VERSION ""

NS_ :

BS_:

BU_: L_3HKBD L_FHPTC L_2HKBD L_ATCU L_PCM L_EVNT L_HKBD L_RHPTC

BO_ 36 L_ATCU_04: 8 L_ATCU
 SG_ L_ATCU_ArClnIntroEvt : 0|1@1+ (1,0) [0|0] ""  L_HKBD
 SG_ L_ATCU_ArClnSmblClr : 1|4@1+ (1,0) [0|0] ""  L_HKBD
 SG_ L_ATCU_DustLevelDis : 19|3@1+ (1,0) [0|0] ""  L_HKBD
 SG_ L_ATCU_DustBarDisOff : 22|1@1+ (1,0) [0|0] ""  L_HKBD
 SG_ L_ATCU_DustSnrStepDis : 23|6@1+ (1,0) [0|0] ""  L_HKBD
 SG_ L_ATCU_FragStrhDis : 29|2@1+ (1,0) [0|0] ""  L_HKBD,L_PCM
 SG_ L_ATCU_FragKindDis : 31|3@1+ (1,0) [0|0] ""  L_HKBD,L_PCM
 SG_ L_ATCU_Frag1Inform : 34|4@1+ (1,0) [0|0] ""  L_HKBD,L_PCM
 SG_ L_ATCU_Frag2Inform : 38|4@1+ (1,0) [0|0] ""  L_HKBD,L_PCM
 SG_ L_ATCU_Frag1RemainDisp : 42|4@1+ (1,0) [0|0] ""  L_HKBD,L_PCM
 SG_ L_ATCU_Frag2RemainDisp : 46|4@1+ (1,0) [0|0] ""  L_2HKBD,L_HKBD
 SG_ L_ATCU_ArClnSmblTyp : 5|4@1+ (1,0) [0|0] ""  L_HKBD
 SG_ L_ATCU_FrtBlwMaxLvlVaild : 50|4@1+ (1,0) [0|0] ""  L_2HKBD,L_HKBD
 SG_ L_ATCU_OpSta : 54|3@1+ (1,0) [0|0] ""  L_EVNT,L_HKBD
 SG_ L_ATCU_TempDispUnit : 57|2@1+ (1,0) [0|0] ""  L_2HKBD,L_HKBD
 SG_ L_ATCU_DrvAUTOStep : 59|4@1+ (1,0) [0|0] ""  L_HKBD
 SG_ L_ATCU_DiagCodeDis : 9|10@1+ (1,-1) [0|0] ""  L_HKBD

BO_ 37 L_ATCU_05: 8 L_ATCU
 SG_ L_ATCU_RrOpSta : 0|3@1+ (1,0) [0|0] ""  L_2HKBD,L_HKBD
 SG_ L_ATCU_RrDrvTempFDis : 11|8@1+ (1,56) [0|0] "¢µ"  L_2HKBD,L_HKBD
 SG_ L_ATCU_RrDrvModDis : 19|4@1+ (1,0) [0|0] ""  L_2HKBD,L_EVNT,L_HKBD
 SG_ L_ATCU_RrDrvBlwDis : 23|4@1+ (1,0) [0|0] ""  L_2HKBD,L_HKBD
 SG_ L_ATCU_RrDrvAutoDis : 27|2@1+ (1,0) [0|0] ""  L_2HKBD,L_HKBD
 SG_ L_ATCU_RrDrvMultiAutoBlwDis : 29|2@1+ (1,0) [0|0] ""  L_2HKBD,L_HKBD
 SG_ L_ATCU_RrDrvTempCDis : 3|8@1+ (0.5,14) [0|0] "¡É"  L_2HKBD,L_HKBD
 SG_ L_ATCU_RrSyncDis : 31|2@1+ (1,0) [0|0] ""  L_2HKBD,L_HKBD
 SG_ L_ATCU_RrLcdBckLightSta : 33|1@1+ (1,0) [0|0] ""  L_2HKBD,L_HKBD
 SG_ L_ATCU_RrGUIBlankDis : 34|1@1+ (1,0) [0|0] ""  L_2HKBD,L_HKBD
 SG_ L_ATCU_RLStHeatSwHInd : 35|1@1+ (1,0) [0|0] ""  L_2HKBD,L_HKBD
 SG_ L_ATCU_RLStHeatSwMInd : 36|1@1+ (1,0) [0|0] ""  L_2HKBD,L_HKBD
 SG_ L_ATCU_RLStHeatSwLInd : 37|1@1+ (1,0) [0|0] ""  L_2HKBD,L_HKBD
 SG_ L_ATCU_RLStVntSwHInd : 38|1@1+ (1,0) [0|0] ""  L_2HKBD,L_HKBD
 SG_ L_ATCU_RLStVntSwMInd : 39|1@1+ (1,0) [0|0] ""  L_2HKBD,L_HKBD
 SG_ L_ATCU_RLStVntSwLInd : 40|1@1+ (1,0) [0|0] ""  L_2HKBD,L_HKBD
 SG_ L_ATCU_RRStHeatSwHInd : 41|1@1+ (1,0) [0|0] ""  L_2HKBD,L_HKBD
 SG_ L_ATCU_RRStHeatSwMInd : 42|1@1+ (1,0) [0|0] ""  L_2HKBD,L_HKBD
 SG_ L_ATCU_RRStHeatSwLInd : 43|1@1+ (1,0) [0|0] ""  L_2HKBD,L_HKBD
 SG_ L_ATCU_RRStVntSwHInd : 44|1@1+ (1,0) [0|0] ""  L_2HKBD,L_HKBD
 SG_ L_ATCU_RRStVntSwMInd : 45|1@1+ (1,0) [0|0] ""  L_2HKBD,L_HKBD
 SG_ L_ATCU_RRStVntSwLInd : 46|1@1+ (1,0) [0|0] ""  L_2HKBD,L_HKBD
 SG_ L_ATCU_RrMTCOpSta : 47|2@1+ (1,0) [0|0] ""  L_2HKBD,L_HKBD
 SG_ L_ATCU_RrMTCTempLvl : 49|4@1+ (1,0) [0|0] ""  L_2HKBD,L_HKBD
 SG_ L_ATCU_RrPsModDis : 53|4@1+ (1,0) [0|0] ""  L_2HKBD,L_EVNT,L_HKBD
 SG_ L_ATCU_RrLockDis : 57|2@1+ (1,0) [0|0] ""  L_2HKBD,L_HKBD
 SG_ L_ATCU_RrDrvAutoStep : 59|4@1+ (1,0) [0|0] ""  L_2HKBD,L_HKBD

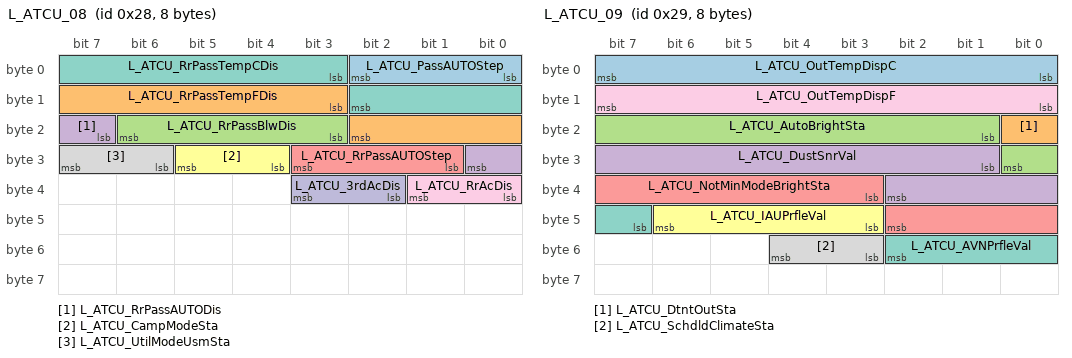
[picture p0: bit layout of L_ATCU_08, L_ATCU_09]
BO_ 40 L_ATCU_08: 8 L_ATCU
 SG_ L_ATCU_PassAUTOStep : 0|3@1+ (1,0) [0|0] ""  L_2HKBD,L_HKBD
 SG_ L_ATCU_RrPassTempFDis : 11|8@1+ (1,56) [0|0] "¢µ"  L_2HKBD,L_HKBD
 SG_ L_ATCU_RrPassBlwDis : 19|4@1+ (1,0) [0|0] ""  L_2HKBD,L_HKBD
 SG_ L_ATCU_RrPassAUTODis : 23|2@1+ (1,0) [0|0] ""  L_2HKBD,L_HKBD
 SG_ L_ATCU_RrPassAUTOStep : 25|3@1+ (1,0) [0|0] ""  L_2HKBD,L_HKBD
 SG_ L_ATCU_CampModeSta : 28|2@1+ (1,0) [0|0] ""  L_2HKBD,L_3HKBD,L_EVNT,L_HKBD
 SG_ L_ATCU_RrPassTempCDis : 3|8@1+ (0.5,14) [0|0] "¡É"  L_2HKBD,L_HKBD
 SG_ L_ATCU_UtilModeUsmSta : 30|2@1+ (1,0) [0|0] ""  L_2HKBD,L_3HKBD,L_EVNT,L_HKBD
 SG_ L_ATCU_RrAcDis : 32|2@1+ (1,0) [0|0] ""  L_2HKBD,L_3HKBD,L_HKBD
 SG_ L_ATCU_3rdAcDis : 34|2@1+ (1,0) [0|0] ""  L_2HKBD,L_3HKBD,L_HKBD

BO_ 41 L_ATCU_09: 8 L_ATCU
 SG_ L_ATCU_OutTempDispC : 0|8@1+ (0.5,-41) [0|0] "¡É"  L_FHPTC,L_HKBD,L_RHPTC
 SG_ L_ATCU_DtntOutSta : 16|1@1+ (1,0) [0|0] ""  L_2HKBD,L_EVNT,L_HKBD
 SG_ L_ATCU_AutoBrightSta : 17|8@1+ (1,0) [0|0] ""  L_2HKBD,L_EVNT,L_HKBD
 SG_ L_ATCU_DustSnrVal : 25|10@1+ (1,0) [0|0] "um/m3"  L_HKBD
 SG_ L_ATCU_NotMinModeBrightSta : 35|8@1+ (1,0) [0|0] ""  L_2HKBD,L_3HKBD,L_EVNT,L_HKBD
 SG_ L_ATCU_IAUPrfleVal : 43|4@1+ (1,0) [0|0] ""  L_EVNT
 SG_ L_ATCU_AVNPrfleVal : 47|4@1+ (1,0) [0|0] ""  L_EVNT
 SG_ L_ATCU_SchdldClimateSta : 51|2@1+ (1,0) [0|0] ""  L_EVNT
 SG_ L_ATCU_OutTempDispF : 8|8@1+ (1,-42) [0|0] "¢µ"  L_FHPTC,L_HKBD,L_RHPTC

BO_ 49 L_ATCU_11: 8 L_ATCU
 SG_ L_ATCU_ResetPreWrngForOthers : 0|2@1+ (1,0) [0|0] ""  L_2HKBD,L_3HKBD,L_EVNT,L_HKBD,L_PCM
 SG_ L_ATCU_ResetReqForOthers : 2|2@1+ (1,0) [0|0] ""  L_2HKBD,L_3HKBD,L_EVNT,L_HKBD,L_PCM

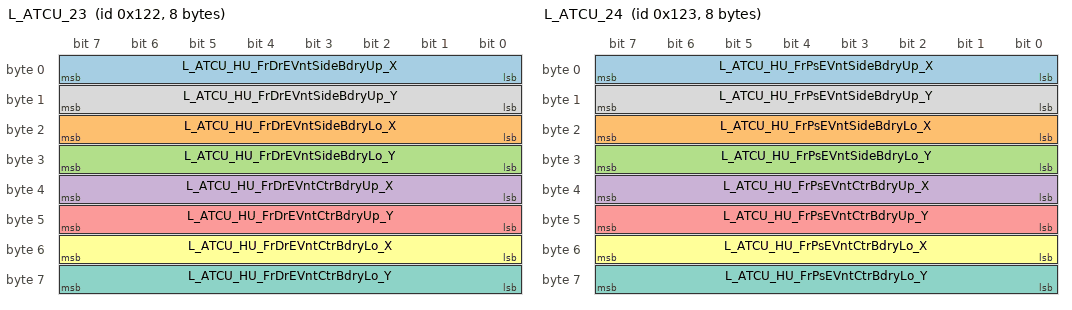
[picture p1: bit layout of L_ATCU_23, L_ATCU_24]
BO_ 290 L_ATCU_23: 8 L_ATCU
 SG_ L_ATCU_HU_FrDrEVntSideBdryUp_X : 0|8@1+ (10,0) [0|0] ""  L_EVNT
 SG_ L_ATCU_HU_FrDrEVntSideBdryLo_X : 16|8@1+ (10,0) [0|0] ""  L_EVNT
 SG_ L_ATCU_HU_FrDrEVntSideBdryLo_Y : 24|8@1+ (10,0) [0|0] ""  L_EVNT
 SG_ L_ATCU_HU_FrDrEVntCtrBdryUp_X : 32|8@1+ (10,0) [0|0] ""  L_EVNT
 SG_ L_ATCU_HU_FrDrEVntCtrBdryUp_Y : 40|8@1+ (10,0) [0|0] ""  L_EVNT
 SG_ L_ATCU_HU_FrDrEVntCtrBdryLo_X : 48|8@1+ (10,0) [0|0] ""  L_EVNT
 SG_ L_ATCU_HU_FrDrEVntCtrBdryLo_Y : 56|8@1+ (10,0) [0|0] ""  L_EVNT
 SG_ L_ATCU_HU_FrDrEVntSideBdryUp_Y : 8|8@1+ (10,0) [0|0] ""  L_EVNT

BO_ 291 L_ATCU_24: 8 L_ATCU
 SG_ L_ATCU_HU_FrPsEVntSideBdryUp_X : 0|8@1+ (10,0) [0|0] ""  L_EVNT
 SG_ L_ATCU_HU_FrPsEVntSideBdryLo_X : 16|8@1+ (10,0) [0|0] ""  L_EVNT
 SG_ L_ATCU_HU_FrPsEVntSideBdryLo_Y : 24|8@1+ (10,0) [0|0] ""  L_EVNT
 SG_ L_ATCU_HU_FrPsEVntCtrBdryUp_X : 32|8@1+ (10,0) [0|0] ""  L_EVNT
 SG_ L_ATCU_HU_FrPsEVntCtrBdryUp_Y : 40|8@1+ (10,0) [0|0] ""  L_EVNT
 SG_ L_ATCU_HU_FrPsEVntCtrBdryLo_X : 48|8@1+ (10,0) [0|0] ""  L_EVNT
 SG_ L_ATCU_HU_FrPsEVntCtrBdryLo_Y : 56|8@1+ (10,0) [0|0] ""  L_EVNT
 SG_ L_ATCU_HU_FrPsEVntSideBdryUp_Y : 8|8@1+ (10,0) [0|0] ""  L_EVNT

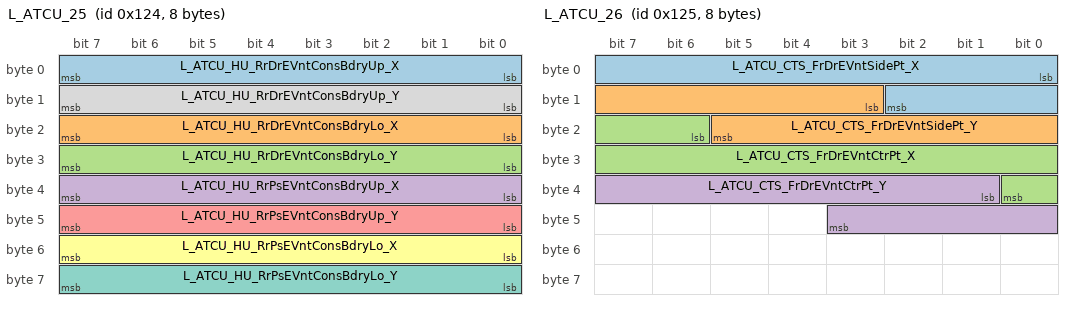
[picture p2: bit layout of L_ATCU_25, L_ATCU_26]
BO_ 292 L_ATCU_25: 8 L_ATCU
 SG_ L_ATCU_HU_RrDrEVntConsBdryUp_X : 0|8@1+ (10,0) [0|0] ""  L_EVNT
 SG_ L_ATCU_HU_RrDrEVntConsBdryLo_X : 16|8@1+ (10,0) [0|0] ""  L_EVNT
 SG_ L_ATCU_HU_RrDrEVntConsBdryLo_Y : 24|8@1+ (10,0) [0|0] ""  L_EVNT
 SG_ L_ATCU_HU_RrPsEVntConsBdryUp_X : 32|8@1+ (10,0) [0|0] ""  L_EVNT
 SG_ L_ATCU_HU_RrPsEVntConsBdryUp_Y : 40|8@1+ (10,0) [0|0] ""  L_EVNT
 SG_ L_ATCU_HU_RrPsEVntConsBdryLo_X : 48|8@1+ (10,0) [0|0] ""  L_EVNT
 SG_ L_ATCU_HU_RrPsEVntConsBdryLo_Y : 56|8@1+ (10,0) [0|0] ""  L_EVNT
 SG_ L_ATCU_HU_RrDrEVntConsBdryUp_Y : 8|8@1+ (10,0) [0|0] ""  L_EVNT

BO_ 293 L_ATCU_26: 8 L_ATCU
 SG_ L_ATCU_CTS_FrDrEVntSidePt_X : 0|11@1+ (1,0) [0|0] ""  L_EVNT
 SG_ L_ATCU_CTS_FrDrEVntSidePt_Y : 11|11@1+ (1,0) [0|0] ""  L_EVNT
 SG_ L_ATCU_CTS_FrDrEVntCtrPt_X : 22|11@1+ (1,0) [0|0] ""  L_EVNT
 SG_ L_ATCU_CTS_FrDrEVntCtrPt_Y : 33|11@1+ (1,0) [0|0] ""  L_EVNT

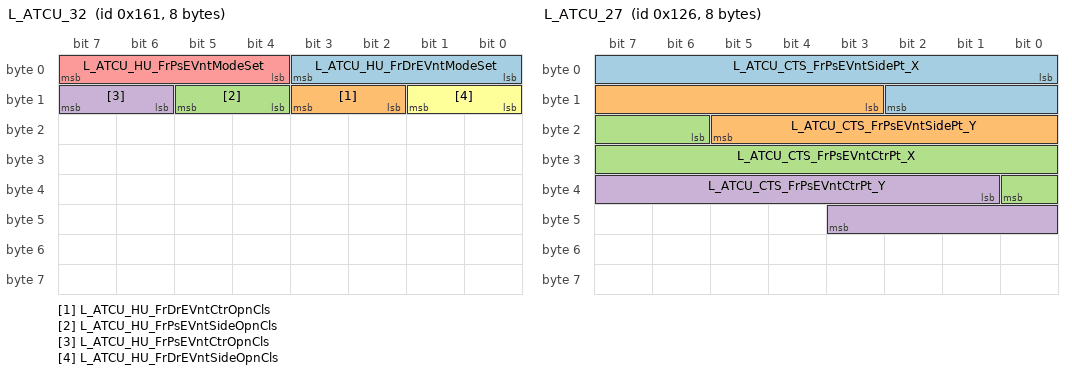
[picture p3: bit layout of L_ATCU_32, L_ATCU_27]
BO_ 353 L_ATCU_32: 8 L_ATCU
 SG_ L_ATCU_HU_FrDrEVntModeSet : 0|4@1+ (1,0) [0|0] ""  L_EVNT
 SG_ L_ATCU_HU_FrDrEVntCtrOpnCls : 10|2@1+ (1,0) [0|0] ""  L_EVNT
 SG_ L_ATCU_HU_FrPsEVntSideOpnCls : 12|2@1+ (1,0) [0|0] ""  L_EVNT
 SG_ L_ATCU_HU_FrPsEVntCtrOpnCls : 14|2@1+ (1,0) [0|0] ""  L_EVNT
 SG_ L_ATCU_HU_FrPsEVntModeSet : 4|4@1+ (1,0) [0|0] ""  L_EVNT
 SG_ L_ATCU_HU_FrDrEVntSideOpnCls : 8|2@1+ (1,0) [0|0] ""  L_EVNT

BO_ 294 L_ATCU_27: 8 L_ATCU
 SG_ L_ATCU_CTS_FrPsEVntSidePt_X : 0|11@1+ (1,0) [0|0] ""  L_EVNT
 SG_ L_ATCU_CTS_FrPsEVntSidePt_Y : 11|11@1+ (1,0) [0|0] ""  L_EVNT
 SG_ L_ATCU_CTS_FrPsEVntCtrPt_X : 22|11@1+ (1,0) [0|0] ""  L_EVNT
 SG_ L_ATCU_CTS_FrPsEVntCtrPt_Y : 33|11@1+ (1,0) [0|0] ""  L_EVNT

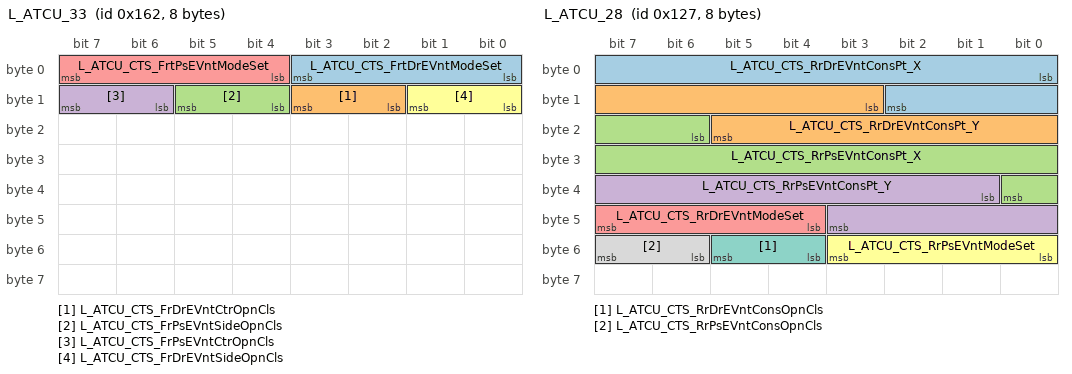
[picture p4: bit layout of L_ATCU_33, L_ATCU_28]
BO_ 354 L_ATCU_33: 8 L_ATCU
 SG_ L_ATCU_CTS_FrtDrEVntModeSet : 0|4@1+ (1,0) [0|0] ""  L_EVNT
 SG_ L_ATCU_CTS_FrDrEVntCtrOpnCls : 10|2@1+ (1,0) [0|0] ""  L_EVNT
 SG_ L_ATCU_CTS_FrPsEVntSideOpnCls : 12|2@1+ (1,0) [0|0] ""  L_EVNT
 SG_ L_ATCU_CTS_FrPsEVntCtrOpnCls : 14|2@1+ (1,0) [0|0] ""  L_EVNT
 SG_ L_ATCU_CTS_FrtPsEVntModeSet : 4|4@1+ (1,0) [0|0] ""  L_EVNT
 SG_ L_ATCU_CTS_FrDrEVntSideOpnCls : 8|2@1+ (1,0) [0|0] ""  L_EVNT

BO_ 295 L_ATCU_28: 8 L_ATCU
 SG_ L_ATCU_CTS_RrDrEVntConsPt_X : 0|11@1+ (1,0) [0|0] ""  L_EVNT
 SG_ L_ATCU_CTS_RrDrEVntConsPt_Y : 11|11@1+ (1,0) [0|0] ""  L_EVNT
 SG_ L_ATCU_CTS_RrPsEVntConsPt_X : 22|11@1+ (1,0) [0|0] ""  L_EVNT
 SG_ L_ATCU_CTS_RrPsEVntConsPt_Y : 33|11@1+ (1,0) [0|0] ""  L_EVNT
 SG_ L_ATCU_CTS_RrDrEVntModeSet : 44|4@1+ (1,0) [0|0] ""  L_EVNT
 SG_ L_ATCU_CTS_RrPsEVntModeSet : 48|4@1+ (1,0) [0|0] ""  L_EVNT
 SG_ L_ATCU_CTS_RrDrEVntConsOpnCls : 52|2@1+ (1,0) [0|0] ""  L_EVNT
 SG_ L_ATCU_CTS_RrPsEVntConsOpnCls : 54|2@1+ (1,0) [0|0] ""  L_EVNT

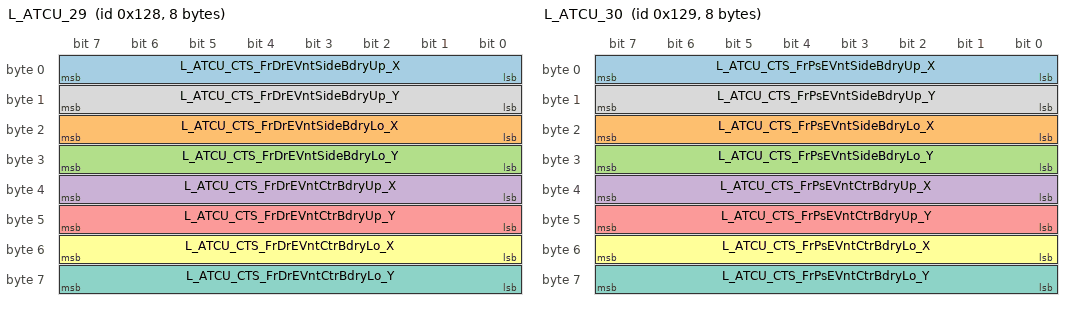
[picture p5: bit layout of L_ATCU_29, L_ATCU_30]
BO_ 296 L_ATCU_29: 8 L_ATCU
 SG_ L_ATCU_CTS_FrDrEVntSideBdryUp_X : 0|8@1+ (10,0) [0|0] ""  L_EVNT
 SG_ L_ATCU_CTS_FrDrEVntSideBdryLo_X : 16|8@1+ (10,0) [0|0] ""  L_EVNT
 SG_ L_ATCU_CTS_FrDrEVntSideBdryLo_Y : 24|8@1+ (10,0) [0|0] ""  L_EVNT
 SG_ L_ATCU_CTS_FrDrEVntCtrBdryUp_X : 32|8@1+ (10,0) [0|0] ""  L_EVNT
 SG_ L_ATCU_CTS_FrDrEVntCtrBdryUp_Y : 40|8@1+ (10,0) [0|0] ""  L_EVNT
 SG_ L_ATCU_CTS_FrDrEVntCtrBdryLo_X : 48|8@1+ (10,0) [0|0] ""  L_EVNT
 SG_ L_ATCU_CTS_FrDrEVntCtrBdryLo_Y : 56|8@1+ (10,0) [0|0] ""  L_EVNT
 SG_ L_ATCU_CTS_FrDrEVntSideBdryUp_Y : 8|8@1+ (10,0) [0|0] ""  L_EVNT

BO_ 297 L_ATCU_30: 8 L_ATCU
 SG_ L_ATCU_CTS_FrPsEVntSideBdryUp_X : 0|8@1+ (10,0) [0|0] ""  L_EVNT
 SG_ L_ATCU_CTS_FrPsEVntSideBdryLo_X : 16|8@1+ (10,0) [0|0] ""  L_EVNT
 SG_ L_ATCU_CTS_FrPsEVntSideBdryLo_Y : 24|8@1+ (10,0) [0|0] ""  L_EVNT
 SG_ L_ATCU_CTS_FrPsEVntCtrBdryUp_X : 32|8@1+ (10,0) [0|0] ""  L_EVNT
 SG_ L_ATCU_CTS_FrPsEVntCtrBdryUp_Y : 40|8@1+ (10,0) [0|0] ""  L_EVNT
 SG_ L_ATCU_CTS_FrPsEVntCtrBdryLo_X : 48|8@1+ (10,0) [0|0] ""  L_EVNT
 SG_ L_ATCU_CTS_FrPsEVntCtrBdryLo_Y : 56|8@1+ (10,0) [0|0] ""  L_EVNT
 SG_ L_ATCU_CTS_FrPsEVntSideBdryUp_Y : 8|8@1+ (10,0) [0|0] ""  L_EVNT

CM_ BO_ 36 "[PE] Periodic and On Event";
CM_ SG_ 36 L_ATCU_ArClnIntroEvt "ATCU_AirCleaningIntroEvent";
CM_ SG_ 36 L_ATCU_ArClnSmblClr "ATCU_AirCleaningSymbolColor";
CM_ SG_ 36 L_ATCU_DustLevelDis "ATCU_DustLevelDisplay";
CM_ SG_ 36 L_ATCU_DustBarDisOff "ATCU_DustBarDisplayOff";
CM_ SG_ 36 L_ATCU_DustSnrStepDis "ATCU_DustSensorStepDisplay";
CM_ SG_ 36 L_ATCU_FragStrhDis "ATCU_FragStrengthDisplay";
CM_ SG_ 36 L_ATCU_FragKindDis "ATCU_FragKindDisplay";
CM_ SG_ 36 L_ATCU_Frag1Inform "ATCU_Frag1Information";
CM_ SG_ 36 L_ATCU_Frag2Inform "ATCU_Frag2Information";
CM_ SG_ 36 L_ATCU_Frag1RemainDisp "ATCU_Frag1RemainDisplay";
CM_ SG_ 36 L_ATCU_Frag2RemainDisp "ATCU_Frag2RemainDisplay";
CM_ SG_ 36 L_ATCU_ArClnSmblTyp "ATCU_AircCleaningSymbolType";
CM_ SG_ 36 L_ATCU_FrtBlwMaxLvlVaild "ATCU_FrontBlowerMaxLevelVaild";
CM_ SG_ 36 L_ATCU_OpSta "ATCU_OperationStatus";
CM_ SG_ 36 L_ATCU_TempDispUnit "ATCU_TemperatureDisplayUnit";
CM_ SG_ 36 L_ATCU_DrvAUTOStep "ATCU_DriverAutoStep";
CM_ SG_ 36 L_ATCU_DiagCodeDis "ATCU_DiagCodeDisplay";
CM_ BO_ 37 "[PE] Periodic and On Event";
CM_ SG_ 37 L_ATCU_RrOpSta "ATCU_RearOperationStatus";
CM_ SG_ 37 L_ATCU_RrDrvTempFDis "ATCU_RearDriverTemperature¢µDisplay";
CM_ SG_ 37 L_ATCU_RrDrvModDis "ATCU_RearDriverModeDisplay";
CM_ SG_ 37 L_ATCU_RrDrvBlwDis "ATCU_RearDriverBlowerDisplay";
CM_ SG_ 37 L_ATCU_RrDrvAutoDis "ATCU_RearDriverAutoDisplay";
CM_ SG_ 37 L_ATCU_RrDrvMultiAutoBlwDis "ATCU_RearDriverMultiAutoBlowerDisplay";
CM_ SG_ 37 L_ATCU_RrDrvTempCDis "ATCU_RearDriverTemperature¡ÉDisplay";
CM_ SG_ 37 L_ATCU_RrSyncDis "ATCU_RearSyncDisplay";
CM_ SG_ 37 L_ATCU_RrLcdBckLightSta "ATCU_RearLCDBackLightStatus";
CM_ SG_ 37 L_ATCU_RrGUIBlankDis "ATCU_RearGUIBlankDisplay";
CM_ SG_ 37 L_ATCU_RLStHeatSwHInd "ATCU_RearLeftSeatHeatSwitchHighIndicator";
CM_ SG_ 37 L_ATCU_RLStHeatSwMInd "ATCU_RearLeftSeatHeatSwitchMiddleIndicator";
CM_ SG_ 37 L_ATCU_RLStHeatSwLInd "ATCU_RearLeftSeatHeatSwitchLowIndicator";
CM_ SG_ 37 L_ATCU_RLStVntSwHInd "ATCU_RearLeftSeatVentilationSwitchHighIndicator";
CM_ SG_ 37 L_ATCU_RLStVntSwMInd "ATCU_RearLeftSeatVentilationSwitchMiddleIndicator";
CM_ SG_ 37 L_ATCU_RLStVntSwLInd "ATCU_RearLeftSeatVentilationSwitchLowIndicator";
CM_ SG_ 37 L_ATCU_RRStHeatSwHInd "ATCU_RearRightSeatHeatSwitchHighIndicator";
CM_ SG_ 37 L_ATCU_RRStHeatSwMInd "ATCU_RearRightSeatHeatSwitchMiddleIndicator";
CM_ SG_ 37 L_ATCU_RRStHeatSwLInd "ATCU_RearRightSeatHeatSwitchLowIndicator";
CM_ SG_ 37 L_ATCU_RRStVntSwHInd "ATCU_RearRightSeatVentilationSwitchHighIndicator";
CM_ SG_ 37 L_ATCU_RRStVntSwMInd "ATCU_RearRightSeatVentilationSwitchMiddleIndicator";
CM_ SG_ 37 L_ATCU_RRStVntSwLInd "ATCU_RearRightSeatVentilationSwitchLowIndicator";
CM_ SG_ 37 L_ATCU_RrMTCOpSta "ATCU_RearMTCOperationStatus";
CM_ SG_ 37 L_ATCU_RrMTCTempLvl "ATCU_RearMTCTempLevel";
CM_ SG_ 37 L_ATCU_RrPsModDis "ATCU_RearPassengerModeDisplay";
CM_ SG_ 37 L_ATCU_RrLockDis "ATCU_RearLockDisplay";
CM_ SG_ 37 L_ATCU_RrDrvAutoStep "ATCU_RearDriverAutoStep";
CM_ BO_ 40 "[PE] Periodic and On Event";
CM_ SG_ 40 L_ATCU_PassAUTOStep "ATCU_PassAUTOStep";
CM_ SG_ 40 L_ATCU_RrPassTempFDis "ATCU_RrPassTempFDisplay";
CM_ SG_ 40 L_ATCU_RrPassBlwDis "ATCU_RrPassBlwDis";
CM_ SG_ 40 L_ATCU_RrPassAUTODis "ATCU_RrPassAUTODis";
CM_ SG_ 40 L_ATCU_RrPassAUTOStep "ATCU_RrPassAUTOStep";
CM_ SG_ 40 L_ATCU_CampModeSta "ATCU_CampModeStatus";
CM_ SG_ 40 L_ATCU_RrPassTempCDis "ATCU_RrPassTempCDisplay";
CM_ SG_ 40 L_ATCU_UtilModeUsmSta "ATCU_UtilityModeUSMStatus";
CM_ SG_ 40 L_ATCU_RrAcDis "ATCU_RrAcDisplay";
CM_ SG_ 40 L_ATCU_3rdAcDis "L_ATCU_3rdAcDisplay";
CM_ BO_ 41 "[P] Periodic";
CM_ SG_ 41 L_ATCU_OutTempDispC "ATCU_OutTemperatureDisplay(¡É)";
CM_ SG_ 41 L_ATCU_DtntOutSta "ATCU_DetentOutStatus";
CM_ SG_ 41 L_ATCU_AutoBrightSta "ATCU_AutoBrightStatus";
CM_ SG_ 41 L_ATCU_DustSnrVal "ATCU_DustSensorValue";
CM_ SG_ 41 L_ATCU_NotMinModeBrightSta "ATCU_NotMinimumModeBrightStatus";
CM_ SG_ 41 L_ATCU_IAUPrfleVal "L_ATCU_IAUProfileValue";
CM_ SG_ 41 L_ATCU_AVNPrfleVal "L_ATCU_AVNProfileValue";
CM_ SG_ 41 L_ATCU_SchdldClimateSta "Operation of the air conditioning system, controlled by the remote control instructions according to the Power status and VCU(HCU, CCU, etc.), NOT ROUTING.";
CM_ SG_ 41 L_ATCU_OutTempDispF "ATCU_OutTemperatureDisplay(¢µ)";
CM_ BO_ 49 "[PE] Periodic and On Event";
CM_ SG_ 49 L_ATCU_ResetPreWrngForOthers "This is a PDC routing signal for reset preparing sideeffect of reset";
CM_ SG_ 49 L_ATCU_ResetReqForOthers "This is a PDC routing signal for SW reset except for Gateway";
CM_ BO_ 290 "[P] Periodic";
CM_ SG_ 290 L_ATCU_HU_FrDrEVntSideBdryUp_X "Front Driver Electric Vent Side Boundary Upper X Point";
CM_ SG_ 290 L_ATCU_HU_FrDrEVntSideBdryLo_X "Front Driver Electric Vent Side Boundary Lower X Point";
CM_ SG_ 290 L_ATCU_HU_FrDrEVntSideBdryLo_Y "Front Driver Electric Vent Side Boundary Lower Y Point";
CM_ SG_ 290 L_ATCU_HU_FrDrEVntCtrBdryUp_X "Front Driver Electric Vent Center Boundary Upper X Point";
CM_ SG_ 290 L_ATCU_HU_FrDrEVntCtrBdryUp_Y "Front Driver Electric Vent Center Boundary Upper Y Point";
CM_ SG_ 290 L_ATCU_HU_FrDrEVntCtrBdryLo_X "Front Driver Electric Vent Center Boundary Lower X Point";
CM_ SG_ 290 L_ATCU_HU_FrDrEVntCtrBdryLo_Y "Front Driver Electric Vent Center Boundary Lower Y Point";
CM_ SG_ 290 L_ATCU_HU_FrDrEVntSideBdryUp_Y "Front Driver Electric Vent Side Boundary Upper Y Point";
CM_ BO_ 291 "[P] Periodic";
CM_ SG_ 291 L_ATCU_HU_FrPsEVntSideBdryUp_X "Front Passenger Electric Vent Side Boundary Upper X Point";
CM_ SG_ 291 L_ATCU_HU_FrPsEVntSideBdryLo_X "Front Passenger Electric Vent Side Boundary Lower X Point";
CM_ SG_ 291 L_ATCU_HU_FrPsEVntSideBdryLo_Y "Front Passenger Electric Vent Side Boundary Lower Y Point";
CM_ SG_ 291 L_ATCU_HU_FrPsEVntCtrBdryUp_X "Front Passenger Electric Vent Center Boundary Upper X Point";
CM_ SG_ 291 L_ATCU_HU_FrPsEVntCtrBdryUp_Y "Front Passenger Electric Vent Center Boundary Upper Y Point";
CM_ SG_ 291 L_ATCU_HU_FrPsEVntCtrBdryLo_X "Front Passenger Electric Vent Center Boundary Lower X Point";
CM_ SG_ 291 L_ATCU_HU_FrPsEVntCtrBdryLo_Y "Front Passenger Electric Vent Center Boundary Lower Y Point";
CM_ SG_ 291 L_ATCU_HU_FrPsEVntSideBdryUp_Y "Front Passenger Electric Vent Side Boundary Upper Y Point";
CM_ BO_ 292 "[P] Periodic";
CM_ SG_ 292 L_ATCU_HU_RrDrEVntConsBdryUp_X "Rear Driver Electric Vent Console Boundary Upper X Point";
CM_ SG_ 292 L_ATCU_HU_RrDrEVntConsBdryLo_X "Rear Driver Electric Vent Console Boundary Lower X Point";
CM_ SG_ 292 L_ATCU_HU_RrDrEVntConsBdryLo_Y "Rear Driver Electric Vent Console Boundary Lower Y Point";
CM_ SG_ 292 L_ATCU_HU_RrPsEVntConsBdryUp_X "Rear Passenger Electric Vent Console Boundary Upper X Point";
CM_ SG_ 292 L_ATCU_HU_RrPsEVntConsBdryUp_Y "Rear Passenger Electric Vent Console Boundary Upper Y Point";
CM_ SG_ 292 L_ATCU_HU_RrPsEVntConsBdryLo_X "Rear Passenger Electric Vent Console Boundary Lower X Point";
CM_ SG_ 292 L_ATCU_HU_RrPsEVntConsBdryLo_Y "Rear Passenger Electric Vent Console Boundary Lower Y Point";
CM_ SG_ 292 L_ATCU_HU_RrDrEVntConsBdryUp_Y "Rear Driver Electric Vent Console Boundary Upper Y Point";
CM_ BO_ 293 "[EC] On Event and On Change";
CM_ SG_ 293 L_ATCU_CTS_FrDrEVntSidePt_X "Front Driver Electric Vent Side Touch Point X Value";
CM_ SG_ 293 L_ATCU_CTS_FrDrEVntSidePt_Y "Front Driver Electric Vent Side Touch Point Y Value";
CM_ SG_ 293 L_ATCU_CTS_FrDrEVntCtrPt_X "Front Driver Electric Vent Center Touch Point X Value";
CM_ SG_ 293 L_ATCU_CTS_FrDrEVntCtrPt_Y "Front Driver Electric Vent Center Touch Point Y Value";
CM_ BO_ 294 "[EC] On Event and On Change";
CM_ SG_ 294 L_ATCU_CTS_FrPsEVntSidePt_X "Front Passenger Electric Vent Side Touch Point X Value";
CM_ SG_ 294 L_ATCU_CTS_FrPsEVntSidePt_Y "Front Passenger Electric Vent Side Touch Point Y Value";
CM_ SG_ 294 L_ATCU_CTS_FrPsEVntCtrPt_X "Front Passenger Electric Vent Center Touch Point X Value";
CM_ SG_ 294 L_ATCU_CTS_FrPsEVntCtrPt_Y "Front Passenger Electric Vent Center Touch Point Y Value";
CM_ BO_ 295 "[EC] On Event and On Change";
CM_ SG_ 295 L_ATCU_CTS_RrDrEVntConsPt_X "Rear Driver Electric Vent Console Touch Point  X Value";
CM_ SG_ 295 L_ATCU_CTS_RrDrEVntConsPt_Y "Rear Driver Electric Vent Console Touch Point  Y Value";
CM_ SG_ 295 L_ATCU_CTS_RrPsEVntConsPt_X "Rear Passenger Electric Vent Console Touch Point  X Value";
CM_ SG_ 295 L_ATCU_CTS_RrPsEVntConsPt_Y "Rear Passenger Electric Vent Console Touch Point  Y Value";
CM_ SG_ 295 L_ATCU_CTS_RrDrEVntModeSet "Rear Driver Electric Vent Mode Set";
CM_ SG_ 295 L_ATCU_CTS_RrPsEVntModeSet "Rear Passenger Electric Vent Mode Set";
CM_ SG_ 295 L_ATCU_CTS_RrDrEVntConsOpnCls "Rear Driver Electric Vent Console Open Close Signal";
CM_ SG_ 295 L_ATCU_CTS_RrPsEVntConsOpnCls "Rear Passenger Electric Vent Console Open Close Signal";
CM_ BO_ 296 "[P] Periodic";
CM_ SG_ 296 L_ATCU_CTS_FrDrEVntSideBdryUp_X "Front Driver Electric Vent Side Boundary Upper X Point";
CM_ SG_ 296 L_ATCU_CTS_FrDrEVntSideBdryLo_X "Front Driver Electric Vent Side Boundary Lower X Point";
CM_ SG_ 296 L_ATCU_CTS_FrDrEVntSideBdryLo_Y "Front Driver Electric Vent Side Boundary Lower Y Point";
CM_ SG_ 296 L_ATCU_CTS_FrDrEVntCtrBdryUp_X "Front Driver Electric Vent Center Boundary Upper X Point";
CM_ SG_ 296 L_ATCU_CTS_FrDrEVntCtrBdryUp_Y "Front Driver Electric Vent Center Boundary Upper Y Point";
CM_ SG_ 296 L_ATCU_CTS_FrDrEVntCtrBdryLo_X "Front Driver Electric Vent Center Boundary Lower X Point";
CM_ SG_ 296 L_ATCU_CTS_FrDrEVntCtrBdryLo_Y "Front Driver Electric Vent Center Boundary Lower Y Point";
CM_ SG_ 296 L_ATCU_CTS_FrDrEVntSideBdryUp_Y "Front Driver Electric Vent Side Boundary Upper Y Point";
CM_ BO_ 297 "[P] Periodic";
CM_ SG_ 297 L_ATCU_CTS_FrPsEVntSideBdryUp_X "Front Passenger Electric Vent Side Boundary Upper X Point";
CM_ SG_ 297 L_ATCU_CTS_FrPsEVntSideBdryLo_X "Front Passenger Electric Vent Side Boundary Lower X Point";
CM_ SG_ 297 L_ATCU_CTS_FrPsEVntSideBdryLo_Y "Front Passenger Electric Vent Side Boundary Lower Y Point";
CM_ SG_ 297 L_ATCU_CTS_FrPsEVntCtrBdryUp_X "Front Passenger Electric Vent Center Boundary Upper X Point";
CM_ SG_ 297 L_ATCU_CTS_FrPsEVntCtrBdryUp_Y "Front Passenger Electric Vent Center Boundary Upper Y Point";
CM_ SG_ 297 L_ATCU_CTS_FrPsEVntCtrBdryLo_X "Front Passenger Electric Vent Center Boundary Lower X Point";
CM_ SG_ 297 L_ATCU_CTS_FrPsEVntCtrBdryLo_Y "Front Passenger Electric Vent Center Boundary Lower Y Point";
CM_ SG_ 297 L_ATCU_CTS_FrPsEVntSideBdryUp_Y "Front Passenger Electric Vent Side Boundary Upper Y Point";
CM_ BO_ 353 "[EC] On Event and On Change";
CM_ SG_ 353 L_ATCU_HU_FrDrEVntModeSet "Front Driver Electric Vent Mode Set";
CM_ SG_ 353 L_ATCU_HU_FrDrEVntCtrOpnCls "Front Driver Electric Vent Center Open Close Signal";
CM_ SG_ 353 L_ATCU_HU_FrPsEVntSideOpnCls "Front Passenger Electric Vent Side Open Close Signal";
CM_ SG_ 353 L_ATCU_HU_FrPsEVntCtrOpnCls "Front Passenger Electric Vent Center Open Close Signal";
CM_ SG_ 353 L_ATCU_HU_FrPsEVntModeSet "Front Passenger Electric Vent Mode Set";
CM_ SG_ 353 L_ATCU_HU_FrDrEVntSideOpnCls "Front Driver Electric Vent Side Open Close Signal";
CM_ BO_ 354 "[EC] On Event and On Change";
CM_ SG_ 354 L_ATCU_CTS_FrtDrEVntModeSet "Front Driver Electric Vent Mode Set";
CM_ SG_ 354 L_ATCU_CTS_FrDrEVntCtrOpnCls "Front Driver Electric Vent Center Open Close Signal";
CM_ SG_ 354 L_ATCU_CTS_FrPsEVntSideOpnCls "Front Passenger Electric Vent Side Open Close Signal";
CM_ SG_ 354 L_ATCU_CTS_FrPsEVntCtrOpnCls "Front Passenger Electric Vent Center Open Close Signal";
CM_ SG_ 354 L_ATCU_CTS_FrtPsEVntModeSet "Front Passenger Electric Vent Mode Set";
CM_ SG_ 354 L_ATCU_CTS_FrDrEVntSideOpnCls "Front Driver Electric Vent Side Open Close Signal";
BA_DEF_ BO_ "UsrMsgIDSforwardDeviation" INT 0 100 ;
BA_DEF_ BO_ "UsrMsgIDSbackwardDeviation" INT 50 1000 ;
BA_DEF_ BO_ "GenMsgCycleTime" INT 0 2000 ;
BA_DEF_ BO_ "GenMsgStartDelayTime" INT 0 2000 ;
BA_DEF_ BO_ "GenMsgSendType" ENUM "Cyclic","NoMsgSendType" ;
BA_DEF_ BO_ "GenMsgCycleTimeFast" INT 0 500 ;
BA_DEF_ BO_ "GenMsgDelayTime" INT 0 20 ;
BA_DEF_ BO_ "GenMsgILSupport" ENUM "No","Yes" ;
BA_DEF_ BO_ "GenMsgNrOfRepetition" INT 0 3 ;
BA_DEF_ BO_ "VFrameFormat" ENUM "StandardCAN","ExtendedCAN","reserved","reserved","reserved","reserved","reserved","reserved","reserved","reserved","reserved","reserved","reserved","reserved","StandardCAN_FD","ExtendedCAN_FD" ;
BA_DEF_ SG_ "UserSigValidity" ENUM "B+","ACC","IG","IG1","IG2","IG3","IG1 or IG2","IG1 or IG3","Undef" ;
BA_DEF_ SG_ "UsrSigPurpose" ENUM "Undef","FN","DIAG","DIAG(Req)","DIAG(Res)","DIAG(Phy)","DEV","CCP(Req)","CCP(Res)","NM","TP" ;
BA_DEF_ SG_ "GenSigStartValue" INT 0 1215752192 ;
BA_DEF_ SG_ "NetworkRequestHoldingTime" INT 0 65535 ;
BA_DEF_ SG_ "Description" STRING ;
BA_DEF_ SG_ "Version" STRING ;
BA_DEF_ SG_ "GenSigEnvVarType" ENUM "Int","Float","Undef" ;
BA_DEF_ SG_ "GenSigSendType" ENUM "Cyclic","OnWrite","OnWriteWithRepetition","OnChange","OnChangeWithRepetition","IfActive","IfActiveWithRepetition","NoSigSendType","OnChangeAndIfActive","OnChangeAndIfActiveWithRepetition" ;
BA_DEF_ SG_ "GwSigLatencyTime" INT 0 65536 ;
BA_DEF_ SG_ "GwSigMissingSourceType" ENUM "Undef","OldValue","DefaultValue","InitialValue" ;
BA_DEF_ SG_ "NWM-WakeupAllowed" ENUM "<n.a.>" ;
BA_DEF_ SG_ "RoutingFactor" INT 1 1215752192 ;
BA_DEF_REL_ BU_SG_REL_ "GenSigTimeoutTime" INT 0 7000 ;
BA_DEF_DEF_ "UsrMsgIDSforwardDeviation" 10 ;
BA_DEF_DEF_ "UsrMsgIDSbackwardDeviation" 100 ;
BA_DEF_DEF_ "GenMsgCycleTime" 200 ;
BA_DEF_DEF_ "GenMsgStartDelayTime" 0 ;
BA_DEF_DEF_ "GenMsgSendType" "NoMsgSendType" ;
BA_DEF_DEF_ "GenMsgCycleTimeFast" 40 ;
BA_DEF_DEF_ "GenMsgDelayTime" 20 ;
BA_DEF_DEF_ "GenMsgILSupport" "Yes" ;
BA_DEF_DEF_ "GenMsgNrOfRepetition" 3 ;
BA_DEF_DEF_ "VFrameFormat" "StandardCAN" ;
BA_DEF_DEF_ "UserSigValidity" "IG" ;
BA_DEF_DEF_ "UsrSigPurpose" "FN" ;
BA_DEF_DEF_ "GenSigStartValue" 0 ;
BA_DEF_DEF_ "NetworkRequestHoldingTime" 0 ;
BA_DEF_DEF_ "Description" "" ;
BA_DEF_DEF_ "Version" "" ;
BA_DEF_DEF_ "GenSigEnvVarType" "Undef" ;
BA_DEF_DEF_ "GenSigSendType" "NoSigSendType" ;
BA_DEF_DEF_ "GwSigLatencyTime" 40 ;
BA_DEF_DEF_ "GwSigMissingSourceType" "Undef" ;
BA_DEF_DEF_ "NWM-WakeupAllowed" "<n.a.>" ;
BA_DEF_DEF_ "RoutingFactor" 1 ;
BA_DEF_DEF_REL_ "GenSigTimeoutTime" 500 ;
BA_ "GenMsgSendType" BO_ 36 0;
BA_ "GenSigSendType" SG_ 36 L_ATCU_ArClnIntroEvt 4;
BA_ "UserSigValidity" SG_ 36 L_ATCU_ArClnIntroEvt 7;
BA_REL_ "GenSigTimeoutTime" BU_SG_REL_ L_HKBD SG_ 36 L_ATCU_ArClnIntroEvt 1500;
BA_ "Version" SG_ 36 L_ATCU_ArClnIntroEvt "23.08.13";
BA_ "Description" SG_ 36 L_ATCU_ArClnSmblClr "This signal indicates the information about Color of AirCleaning Symbol displaying in the AVN";
BA_ "GenSigSendType" SG_ 36 L_ATCU_ArClnSmblClr 4;
BA_ "UserSigValidity" SG_ 36 L_ATCU_ArClnSmblClr 7;
BA_REL_ "GenSigTimeoutTime" BU_SG_REL_ L_HKBD SG_ 36 L_ATCU_ArClnSmblClr 1500;
BA_ "Version" SG_ 36 L_ATCU_ArClnSmblClr "23.08.13";
BA_ "GenSigSendType" SG_ 36 L_ATCU_DustLevelDis 4;
BA_ "UserSigValidity" SG_ 36 L_ATCU_DustLevelDis 7;
BA_REL_ "GenSigTimeoutTime" BU_SG_REL_ L_HKBD SG_ 36 L_ATCU_DustLevelDis 1500;
BA_ "Version" SG_ 36 L_ATCU_DustLevelDis "23.08.13";
BA_ "GenSigSendType" SG_ 36 L_ATCU_DustBarDisOff 4;
BA_ "UserSigValidity" SG_ 36 L_ATCU_DustBarDisOff 7;
BA_REL_ "GenSigTimeoutTime" BU_SG_REL_ L_HKBD SG_ 36 L_ATCU_DustBarDisOff 1500;
BA_ "Version" SG_ 36 L_ATCU_DustBarDisOff "23.08.13";
BA_ "GenSigSendType" SG_ 36 L_ATCU_DustSnrStepDis 4;
BA_ "UserSigValidity" SG_ 36 L_ATCU_DustSnrStepDis 7;
BA_REL_ "GenSigTimeoutTime" BU_SG_REL_ L_HKBD SG_ 36 L_ATCU_DustSnrStepDis 1500;
BA_ "Version" SG_ 36 L_ATCU_DustSnrStepDis "23.08.13";
BA_ "GenSigSendType" SG_ 36 L_ATCU_FragStrhDis 4;
BA_ "UserSigValidity" SG_ 36 L_ATCU_FragStrhDis 7;
BA_REL_ "GenSigTimeoutTime" BU_SG_REL_ L_HKBD SG_ 36 L_ATCU_FragStrhDis 1500;
BA_REL_ "GenSigTimeoutTime" BU_SG_REL_ L_PCM SG_ 36 L_ATCU_FragStrhDis 1500;
BA_ "Version" SG_ 36 L_ATCU_FragStrhDis "23.08.13";
BA_ "Description" SG_ 36 L_ATCU_FragKindDis "This singal indicates display value of Fragnance kind";
BA_ "GenSigSendType" SG_ 36 L_ATCU_FragKindDis 4;
BA_ "UserSigValidity" SG_ 36 L_ATCU_FragKindDis 7;
BA_REL_ "GenSigTimeoutTime" BU_SG_REL_ L_HKBD SG_ 36 L_ATCU_FragKindDis 1500;
BA_REL_ "GenSigTimeoutTime" BU_SG_REL_ L_PCM SG_ 36 L_ATCU_FragKindDis 1500;
BA_ "Version" SG_ 36 L_ATCU_FragKindDis "24.05.08";
BA_ "Description" SG_ 36 L_ATCU_Frag1Inform "This signal indicates Information of Fragrance 1";
BA_ "GenSigSendType" SG_ 36 L_ATCU_Frag1Inform 4;
BA_ "UserSigValidity" SG_ 36 L_ATCU_Frag1Inform 7;
BA_REL_ "GenSigTimeoutTime" BU_SG_REL_ L_HKBD SG_ 36 L_ATCU_Frag1Inform 1500;
BA_REL_ "GenSigTimeoutTime" BU_SG_REL_ L_PCM SG_ 36 L_ATCU_Frag1Inform 1500;
BA_ "Version" SG_ 36 L_ATCU_Frag1Inform "23.08.13";
BA_ "Description" SG_ 36 L_ATCU_Frag2Inform "This signal indicates Information of Fragrance 2";
BA_ "GenSigSendType" SG_ 36 L_ATCU_Frag2Inform 4;
BA_ "UserSigValidity" SG_ 36 L_ATCU_Frag2Inform 7;
BA_REL_ "GenSigTimeoutTime" BU_SG_REL_ L_HKBD SG_ 36 L_ATCU_Frag2Inform 1500;
BA_REL_ "GenSigTimeoutTime" BU_SG_REL_ L_PCM SG_ 36 L_ATCU_Frag2Inform 1500;
BA_ "Version" SG_ 36 L_ATCU_Frag2Inform "23.08.13";
BA_ "Description" SG_ 36 L_ATCU_Frag1RemainDisp "This signal indicates Remain Display of Ragrnace No.1";
BA_ "GenSigSendType" SG_ 36 L_ATCU_Frag1RemainDisp 4;
BA_ "UserSigValidity" SG_ 36 L_ATCU_Frag1RemainDisp 7;
BA_REL_ "GenSigTimeoutTime" BU_SG_REL_ L_HKBD SG_ 36 L_ATCU_Frag1RemainDisp 1500;
BA_REL_ "GenSigTimeoutTime" BU_SG_REL_ L_PCM SG_ 36 L_ATCU_Frag1RemainDisp 1500;
BA_ "Version" SG_ 36 L_ATCU_Frag1RemainDisp "23.08.13";
BA_ "Description" SG_ 36 L_ATCU_Frag2RemainDisp "This signal indicates Remain Display of Ragrnace No.2";
BA_ "GenSigSendType" SG_ 36 L_ATCU_Frag2RemainDisp 4;
BA_ "UserSigValidity" SG_ 36 L_ATCU_Frag2RemainDisp 7;
BA_REL_ "GenSigTimeoutTime" BU_SG_REL_ L_2HKBD SG_ 36 L_ATCU_Frag2RemainDisp 1500;
BA_REL_ "GenSigTimeoutTime" BU_SG_REL_ L_HKBD SG_ 36 L_ATCU_Frag2RemainDisp 1500;
BA_ "Version" SG_ 36 L_ATCU_Frag2RemainDisp "23.08.13";
BA_ "Description" SG_ 36 L_ATCU_ArClnSmblTyp "This signal indicate the feature of Air Cleaning Symbol displaying in the AVN";
BA_ "GenSigSendType" SG_ 36 L_ATCU_ArClnSmblTyp 4;
BA_ "UserSigValidity" SG_ 36 L_ATCU_ArClnSmblTyp 7;
BA_REL_ "GenSigTimeoutTime" BU_SG_REL_ L_HKBD SG_ 36 L_ATCU_ArClnSmblTyp 1500;
BA_ "Version" SG_ 36 L_ATCU_ArClnSmblTyp "23.08.13";
BA_ "Description" SG_ 36 L_ATCU_FrtBlwMaxLvlVaild "This signal indicates the maximum step of Front Blower according to multi auto steps.";
BA_ "GenSigSendType" SG_ 36 L_ATCU_FrtBlwMaxLvlVaild 4;
BA_ "UserSigValidity" SG_ 36 L_ATCU_FrtBlwMaxLvlVaild 7;
BA_REL_ "GenSigTimeoutTime" BU_SG_REL_ L_2HKBD SG_ 36 L_ATCU_FrtBlwMaxLvlVaild 1500;
BA_REL_ "GenSigTimeoutTime" BU_SG_REL_ L_HKBD SG_ 36 L_ATCU_FrtBlwMaxLvlVaild 1500;
BA_ "Version" SG_ 36 L_ATCU_FrtBlwMaxLvlVaild "23.08.13";
BA_ "GenSigSendType" SG_ 36 L_ATCU_OpSta 4;
BA_ "UserSigValidity" SG_ 36 L_ATCU_OpSta 7;
BA_REL_ "GenSigTimeoutTime" BU_SG_REL_ L_EVNT SG_ 36 L_ATCU_OpSta 1500;
BA_REL_ "GenSigTimeoutTime" BU_SG_REL_ L_HKBD SG_ 36 L_ATCU_OpSta 1500;
BA_ "Version" SG_ 36 L_ATCU_OpSta "23.08.13";
BA_ "Description" SG_ 36 L_ATCU_TempDispUnit "This signal is unit of Temperature display";
BA_ "GenSigSendType" SG_ 36 L_ATCU_TempDispUnit 4;
BA_ "UserSigValidity" SG_ 36 L_ATCU_TempDispUnit 7;
BA_REL_ "GenSigTimeoutTime" BU_SG_REL_ L_2HKBD SG_ 36 L_ATCU_TempDispUnit 1500;
BA_REL_ "GenSigTimeoutTime" BU_SG_REL_ L_HKBD SG_ 36 L_ATCU_TempDispUnit 1500;
BA_ "Version" SG_ 36 L_ATCU_TempDispUnit "24.05.08";
BA_ "GenSigSendType" SG_ 36 L_ATCU_DrvAUTOStep 4;
BA_ "UserSigValidity" SG_ 36 L_ATCU_DrvAUTOStep 7;
BA_REL_ "GenSigTimeoutTime" BU_SG_REL_ L_HKBD SG_ 36 L_ATCU_DrvAUTOStep 1500;
BA_ "Version" SG_ 36 L_ATCU_DrvAUTOStep "23.08.13";
BA_ "Description" SG_ 36 L_ATCU_DiagCodeDis "0x1~0x3FE:PHY=(HEX*1.0-1.0)";
BA_ "GenSigSendType" SG_ 36 L_ATCU_DiagCodeDis 4;
BA_ "UserSigValidity" SG_ 36 L_ATCU_DiagCodeDis 7;
BA_REL_ "GenSigTimeoutTime" BU_SG_REL_ L_HKBD SG_ 36 L_ATCU_DiagCodeDis 1500;
BA_ "Version" SG_ 36 L_ATCU_DiagCodeDis "23.08.13";
BA_ "GenMsgSendType" BO_ 37 0;
BA_ "Description" SG_ 37 L_ATCU_RrOpSta "ATCU_RearOperationStatus";
BA_ "GenSigSendType" SG_ 37 L_ATCU_RrOpSta 4;
BA_ "UserSigValidity" SG_ 37 L_ATCU_RrOpSta 7;
BA_REL_ "GenSigTimeoutTime" BU_SG_REL_ L_2HKBD SG_ 37 L_ATCU_RrOpSta 1500;
BA_REL_ "GenSigTimeoutTime" BU_SG_REL_ L_HKBD SG_ 37 L_ATCU_RrOpSta 1500;
BA_ "Version" SG_ 37 L_ATCU_RrOpSta "24.08.00";
BA_ "Description" SG_ 37 L_ATCU_RrDrvTempFDis "This signal indicates Outside Temperature (¢µ)

(Use for display only)";
BA_ "GenSigSendType" SG_ 37 L_ATCU_RrDrvTempFDis 4;
BA_ "UserSigValidity" SG_ 37 L_ATCU_RrDrvTempFDis 7;
BA_REL_ "GenSigTimeoutTime" BU_SG_REL_ L_2HKBD SG_ 37 L_ATCU_RrDrvTempFDis 1500;
BA_REL_ "GenSigTimeoutTime" BU_SG_REL_ L_HKBD SG_ 37 L_ATCU_RrDrvTempFDis 1500;
BA_ "Version" SG_ 37 L_ATCU_RrDrvTempFDis "23.08.13";
BA_ "Description" SG_ 37 L_ATCU_RrDrvModDis "ATCU_RearDriverModeDisplay";
BA_ "GenSigSendType" SG_ 37 L_ATCU_RrDrvModDis 4;
BA_ "UserSigValidity" SG_ 37 L_ATCU_RrDrvModDis 7;
BA_REL_ "GenSigTimeoutTime" BU_SG_REL_ L_2HKBD SG_ 37 L_ATCU_RrDrvModDis 1500;
BA_REL_ "GenSigTimeoutTime" BU_SG_REL_ L_EVNT SG_ 37 L_ATCU_RrDrvModDis 1500;
BA_REL_ "GenSigTimeoutTime" BU_SG_REL_ L_HKBD SG_ 37 L_ATCU_RrDrvModDis 1500;
BA_ "Version" SG_ 37 L_ATCU_RrDrvModDis "24.05.08";
BA_ "GenSigSendType" SG_ 37 L_ATCU_RrDrvBlwDis 4;
BA_ "UserSigValidity" SG_ 37 L_ATCU_RrDrvBlwDis 7;
BA_REL_ "GenSigTimeoutTime" BU_SG_REL_ L_2HKBD SG_ 37 L_ATCU_RrDrvBlwDis 1500;
BA_REL_ "GenSigTimeoutTime" BU_SG_REL_ L_HKBD SG_ 37 L_ATCU_RrDrvBlwDis 1500;
BA_ "Version" SG_ 37 L_ATCU_RrDrvBlwDis "23.08.13";
BA_ "GenSigSendType" SG_ 37 L_ATCU_RrDrvAutoDis 4;
BA_ "UserSigValidity" SG_ 37 L_ATCU_RrDrvAutoDis 7;
BA_REL_ "GenSigTimeoutTime" BU_SG_REL_ L_2HKBD SG_ 37 L_ATCU_RrDrvAutoDis 1500;
BA_REL_ "GenSigTimeoutTime" BU_SG_REL_ L_HKBD SG_ 37 L_ATCU_RrDrvAutoDis 1500;
BA_ "Version" SG_ 37 L_ATCU_RrDrvAutoDis "23.08.13";
BA_ "GenSigSendType" SG_ 37 L_ATCU_RrDrvMultiAutoBlwDis 4;
BA_ "UserSigValidity" SG_ 37 L_ATCU_RrDrvMultiAutoBlwDis 7;
BA_REL_ "GenSigTimeoutTime" BU_SG_REL_ L_2HKBD SG_ 37 L_ATCU_RrDrvMultiAutoBlwDis 1500;
BA_REL_ "GenSigTimeoutTime" BU_SG_REL_ L_HKBD SG_ 37 L_ATCU_RrDrvMultiAutoBlwDis 1500;
BA_ "Version" SG_ 37 L_ATCU_RrDrvMultiAutoBlwDis "23.08.13";
BA_ "Description" SG_ 37 L_ATCU_RrDrvTempCDis "This signal indicates Outside temperature (¡É).

(Use for display only)";
BA_ "GenSigSendType" SG_ 37 L_ATCU_RrDrvTempCDis 4;
BA_ "UserSigValidity" SG_ 37 L_ATCU_RrDrvTempCDis 7;
BA_REL_ "GenSigTimeoutTime" BU_SG_REL_ L_2HKBD SG_ 37 L_ATCU_RrDrvTempCDis 1500;
BA_REL_ "GenSigTimeoutTime" BU_SG_REL_ L_HKBD SG_ 37 L_ATCU_RrDrvTempCDis 1500;
BA_ "Version" SG_ 37 L_ATCU_RrDrvTempCDis "23.08.13";
BA_ "GenSigSendType" SG_ 37 L_ATCU_RrSyncDis 4;
BA_ "UserSigValidity" SG_ 37 L_ATCU_RrSyncDis 7;
BA_REL_ "GenSigTimeoutTime" BU_SG_REL_ L_2HKBD SG_ 37 L_ATCU_RrSyncDis 1500;
BA_REL_ "GenSigTimeoutTime" BU_SG_REL_ L_HKBD SG_ 37 L_ATCU_RrSyncDis 1500;
BA_ "Version" SG_ 37 L_ATCU_RrSyncDis "23.08.13";
BA_ "GenSigSendType" SG_ 37 L_ATCU_RrLcdBckLightSta 4;
BA_ "UserSigValidity" SG_ 37 L_ATCU_RrLcdBckLightSta 7;
BA_REL_ "GenSigTimeoutTime" BU_SG_REL_ L_2HKBD SG_ 37 L_ATCU_RrLcdBckLightSta 1500;
BA_REL_ "GenSigTimeoutTime" BU_SG_REL_ L_HKBD SG_ 37 L_ATCU_RrLcdBckLightSta 1500;
BA_ "Version" SG_ 37 L_ATCU_RrLcdBckLightSta "23.08.13";
BA_ "GenSigSendType" SG_ 37 L_ATCU_RrGUIBlankDis 4;
BA_ "UserSigValidity" SG_ 37 L_ATCU_RrGUIBlankDis 7;
BA_REL_ "GenSigTimeoutTime" BU_SG_REL_ L_2HKBD SG_ 37 L_ATCU_RrGUIBlankDis 1500;
BA_REL_ "GenSigTimeoutTime" BU_SG_REL_ L_HKBD SG_ 37 L_ATCU_RrGUIBlankDis 1500;
BA_ "Version" SG_ 37 L_ATCU_RrGUIBlankDis "23.08.13";
BA_ "GenSigSendType" SG_ 37 L_ATCU_RLStHeatSwHInd 4;
BA_ "UserSigValidity" SG_ 37 L_ATCU_RLStHeatSwHInd 7;
BA_REL_ "GenSigTimeoutTime" BU_SG_REL_ L_2HKBD SG_ 37 L_ATCU_RLStHeatSwHInd 1500;
BA_REL_ "GenSigTimeoutTime" BU_SG_REL_ L_HKBD SG_ 37 L_ATCU_RLStHeatSwHInd 1500;
BA_ "Version" SG_ 37 L_ATCU_RLStHeatSwHInd "23.08.13";
BA_ "GenSigSendType" SG_ 37 L_ATCU_RLStHeatSwMInd 4;
BA_ "UserSigValidity" SG_ 37 L_ATCU_RLStHeatSwMInd 7;
BA_REL_ "GenSigTimeoutTime" BU_SG_REL_ L_2HKBD SG_ 37 L_ATCU_RLStHeatSwMInd 1500;
BA_REL_ "GenSigTimeoutTime" BU_SG_REL_ L_HKBD SG_ 37 L_ATCU_RLStHeatSwMInd 1500;
BA_ "Version" SG_ 37 L_ATCU_RLStHeatSwMInd "23.08.13";
BA_ "GenSigSendType" SG_ 37 L_ATCU_RLStHeatSwLInd 4;
BA_ "UserSigValidity" SG_ 37 L_ATCU_RLStHeatSwLInd 7;
BA_REL_ "GenSigTimeoutTime" BU_SG_REL_ L_2HKBD SG_ 37 L_ATCU_RLStHeatSwLInd 1500;
BA_REL_ "GenSigTimeoutTime" BU_SG_REL_ L_HKBD SG_ 37 L_ATCU_RLStHeatSwLInd 1500;
BA_ "Version" SG_ 37 L_ATCU_RLStHeatSwLInd "23.08.13";
BA_ "GenSigSendType" SG_ 37 L_ATCU_RLStVntSwHInd 4;
BA_ "UserSigValidity" SG_ 37 L_ATCU_RLStVntSwHInd 7;
BA_REL_ "GenSigTimeoutTime" BU_SG_REL_ L_2HKBD SG_ 37 L_ATCU_RLStVntSwHInd 1500;
BA_REL_ "GenSigTimeoutTime" BU_SG_REL_ L_HKBD SG_ 37 L_ATCU_RLStVntSwHInd 1500;
BA_ "Version" SG_ 37 L_ATCU_RLStVntSwHInd "23.08.13";
BA_ "GenSigSendType" SG_ 37 L_ATCU_RLStVntSwMInd 4;
BA_ "UserSigValidity" SG_ 37 L_ATCU_RLStVntSwMInd 7;
BA_REL_ "GenSigTimeoutTime" BU_SG_REL_ L_2HKBD SG_ 37 L_ATCU_RLStVntSwMInd 1500;
BA_REL_ "GenSigTimeoutTime" BU_SG_REL_ L_HKBD SG_ 37 L_ATCU_RLStVntSwMInd 1500;
BA_ "Version" SG_ 37 L_ATCU_RLStVntSwMInd "23.08.13";
BA_ "GenSigSendType" SG_ 37 L_ATCU_RLStVntSwLInd 4;
BA_ "UserSigValidity" SG_ 37 L_ATCU_RLStVntSwLInd 7;
BA_REL_ "GenSigTimeoutTime" BU_SG_REL_ L_2HKBD SG_ 37 L_ATCU_RLStVntSwLInd 1500;
BA_REL_ "GenSigTimeoutTime" BU_SG_REL_ L_HKBD SG_ 37 L_ATCU_RLStVntSwLInd 1500;
BA_ "Version" SG_ 37 L_ATCU_RLStVntSwLInd "23.08.13";
BA_ "GenSigSendType" SG_ 37 L_ATCU_RRStHeatSwHInd 4;
BA_ "UserSigValidity" SG_ 37 L_ATCU_RRStHeatSwHInd 7;
BA_REL_ "GenSigTimeoutTime" BU_SG_REL_ L_2HKBD SG_ 37 L_ATCU_RRStHeatSwHInd 1500;
BA_REL_ "GenSigTimeoutTime" BU_SG_REL_ L_HKBD SG_ 37 L_ATCU_RRStHeatSwHInd 1500;
BA_ "Version" SG_ 37 L_ATCU_RRStHeatSwHInd "23.08.13";
BA_ "GenSigSendType" SG_ 37 L_ATCU_RRStHeatSwMInd 4;
BA_ "UserSigValidity" SG_ 37 L_ATCU_RRStHeatSwMInd 7;
BA_REL_ "GenSigTimeoutTime" BU_SG_REL_ L_2HKBD SG_ 37 L_ATCU_RRStHeatSwMInd 1500;
BA_REL_ "GenSigTimeoutTime" BU_SG_REL_ L_HKBD SG_ 37 L_ATCU_RRStHeatSwMInd 1500;
BA_ "Version" SG_ 37 L_ATCU_RRStHeatSwMInd "23.08.13";
BA_ "GenSigSendType" SG_ 37 L_ATCU_RRStHeatSwLInd 4;
BA_ "UserSigValidity" SG_ 37 L_ATCU_RRStHeatSwLInd 7;
BA_REL_ "GenSigTimeoutTime" BU_SG_REL_ L_2HKBD SG_ 37 L_ATCU_RRStHeatSwLInd 1500;
BA_REL_ "GenSigTimeoutTime" BU_SG_REL_ L_HKBD SG_ 37 L_ATCU_RRStHeatSwLInd 1500;
BA_ "Version" SG_ 37 L_ATCU_RRStHeatSwLInd "23.08.13";
BA_ "GenSigSendType" SG_ 37 L_ATCU_RRStVntSwHInd 4;
BA_ "UserSigValidity" SG_ 37 L_ATCU_RRStVntSwHInd 7;
BA_REL_ "GenSigTimeoutTime" BU_SG_REL_ L_2HKBD SG_ 37 L_ATCU_RRStVntSwHInd 1500;
BA_REL_ "GenSigTimeoutTime" BU_SG_REL_ L_HKBD SG_ 37 L_ATCU_RRStVntSwHInd 1500;
BA_ "Version" SG_ 37 L_ATCU_RRStVntSwHInd "23.08.13";
BA_ "GenSigSendType" SG_ 37 L_ATCU_RRStVntSwMInd 4;
BA_ "UserSigValidity" SG_ 37 L_ATCU_RRStVntSwMInd 7;
BA_REL_ "GenSigTimeoutTime" BU_SG_REL_ L_2HKBD SG_ 37 L_ATCU_RRStVntSwMInd 1500;
BA_REL_ "GenSigTimeoutTime" BU_SG_REL_ L_HKBD SG_ 37 L_ATCU_RRStVntSwMInd 1500;
BA_ "Version" SG_ 37 L_ATCU_RRStVntSwMInd "23.08.13";
BA_ "GenSigSendType" SG_ 37 L_ATCU_RRStVntSwLInd 4;
BA_ "UserSigValidity" SG_ 37 L_ATCU_RRStVntSwLInd 7;
BA_REL_ "GenSigTimeoutTime" BU_SG_REL_ L_2HKBD SG_ 37 L_ATCU_RRStVntSwLInd 1500;
BA_REL_ "GenSigTimeoutTime" BU_SG_REL_ L_HKBD SG_ 37 L_ATCU_RRStVntSwLInd 1500;
BA_ "Version" SG_ 37 L_ATCU_RRStVntSwLInd "23.08.13";
BA_ "GenSigSendType" SG_ 37 L_ATCU_RrMTCOpSta 4;
BA_ "UserSigValidity" SG_ 37 L_ATCU_RrMTCOpSta 7;
BA_REL_ "GenSigTimeoutTime" BU_SG_REL_ L_2HKBD SG_ 37 L_ATCU_RrMTCOpSta 1500;
BA_REL_ "GenSigTimeoutTime" BU_SG_REL_ L_HKBD SG_ 37 L_ATCU_RrMTCOpSta 1500;
BA_ "Version" SG_ 37 L_ATCU_RrMTCOpSta "23.08.13";
BA_ "GenSigSendType" SG_ 37 L_ATCU_RrMTCTempLvl 4;
BA_ "UserSigValidity" SG_ 37 L_ATCU_RrMTCTempLvl 7;
BA_REL_ "GenSigTimeoutTime" BU_SG_REL_ L_2HKBD SG_ 37 L_ATCU_RrMTCTempLvl 1500;
BA_REL_ "GenSigTimeoutTime" BU_SG_REL_ L_HKBD SG_ 37 L_ATCU_RrMTCTempLvl 1500;
BA_ "Version" SG_ 37 L_ATCU_RrMTCTempLvl "23.08.13";
BA_ "Description" SG_ 37 L_ATCU_RrPsModDis "ATCU_RearPassengerModeDisplay";
BA_ "GenSigSendType" SG_ 37 L_ATCU_RrPsModDis 4;
BA_ "UserSigValidity" SG_ 37 L_ATCU_RrPsModDis 7;
BA_REL_ "GenSigTimeoutTime" BU_SG_REL_ L_2HKBD SG_ 37 L_ATCU_RrPsModDis 1500;
BA_REL_ "GenSigTimeoutTime" BU_SG_REL_ L_EVNT SG_ 37 L_ATCU_RrPsModDis 1500;
BA_REL_ "GenSigTimeoutTime" BU_SG_REL_ L_HKBD SG_ 37 L_ATCU_RrPsModDis 1500;
BA_ "Version" SG_ 37 L_ATCU_RrPsModDis "24.05.08";
BA_ "GenSigSendType" SG_ 37 L_ATCU_RrLockDis 4;
BA_ "UserSigValidity" SG_ 37 L_ATCU_RrLockDis 7;
BA_REL_ "GenSigTimeoutTime" BU_SG_REL_ L_2HKBD SG_ 37 L_ATCU_RrLockDis 1500;
BA_REL_ "GenSigTimeoutTime" BU_SG_REL_ L_HKBD SG_ 37 L_ATCU_RrLockDis 1500;
BA_ "Version" SG_ 37 L_ATCU_RrLockDis "23.08.13";
BA_ "GenSigSendType" SG_ 37 L_ATCU_RrDrvAutoStep 4;
BA_ "UserSigValidity" SG_ 37 L_ATCU_RrDrvAutoStep 7;
BA_REL_ "GenSigTimeoutTime" BU_SG_REL_ L_2HKBD SG_ 37 L_ATCU_RrDrvAutoStep 1500;
BA_REL_ "GenSigTimeoutTime" BU_SG_REL_ L_HKBD SG_ 37 L_ATCU_RrDrvAutoStep 1500;
BA_ "Version" SG_ 37 L_ATCU_RrDrvAutoStep "23.08.13";
BA_ "GenMsgSendType" BO_ 40 0;
BA_ "GenSigSendType" SG_ 40 L_ATCU_PassAUTOStep 4;
BA_ "UserSigValidity" SG_ 40 L_ATCU_PassAUTOStep 7;
BA_REL_ "GenSigTimeoutTime" BU_SG_REL_ L_2HKBD SG_ 40 L_ATCU_PassAUTOStep 1500;
BA_REL_ "GenSigTimeoutTime" BU_SG_REL_ L_HKBD SG_ 40 L_ATCU_PassAUTOStep 1500;
BA_ "Version" SG_ 40 L_ATCU_PassAUTOStep "23.08.13";
BA_ "GenSigSendType" SG_ 40 L_ATCU_RrPassTempFDis 4;
BA_ "UserSigValidity" SG_ 40 L_ATCU_RrPassTempFDis 7;
BA_REL_ "GenSigTimeoutTime" BU_SG_REL_ L_2HKBD SG_ 40 L_ATCU_RrPassTempFDis 1500;
BA_REL_ "GenSigTimeoutTime" BU_SG_REL_ L_HKBD SG_ 40 L_ATCU_RrPassTempFDis 1500;
BA_ "Version" SG_ 40 L_ATCU_RrPassTempFDis "23.08.13";
BA_ "GenSigSendType" SG_ 40 L_ATCU_RrPassBlwDis 4;
BA_ "UserSigValidity" SG_ 40 L_ATCU_RrPassBlwDis 7;
BA_REL_ "GenSigTimeoutTime" BU_SG_REL_ L_2HKBD SG_ 40 L_ATCU_RrPassBlwDis 1500;
BA_REL_ "GenSigTimeoutTime" BU_SG_REL_ L_HKBD SG_ 40 L_ATCU_RrPassBlwDis 1500;
BA_ "Version" SG_ 40 L_ATCU_RrPassBlwDis "23.08.13";
BA_ "GenSigSendType" SG_ 40 L_ATCU_RrPassAUTODis 4;
BA_ "UserSigValidity" SG_ 40 L_ATCU_RrPassAUTODis 7;
BA_REL_ "GenSigTimeoutTime" BU_SG_REL_ L_2HKBD SG_ 40 L_ATCU_RrPassAUTODis 1500;
BA_REL_ "GenSigTimeoutTime" BU_SG_REL_ L_HKBD SG_ 40 L_ATCU_RrPassAUTODis 1500;
BA_ "Version" SG_ 40 L_ATCU_RrPassAUTODis "23.08.13";
BA_ "GenSigSendType" SG_ 40 L_ATCU_RrPassAUTOStep 4;
BA_ "UserSigValidity" SG_ 40 L_ATCU_RrPassAUTOStep 7;
BA_REL_ "GenSigTimeoutTime" BU_SG_REL_ L_2HKBD SG_ 40 L_ATCU_RrPassAUTOStep 1500;
BA_REL_ "GenSigTimeoutTime" BU_SG_REL_ L_HKBD SG_ 40 L_ATCU_RrPassAUTOStep 1500;
BA_ "Version" SG_ 40 L_ATCU_RrPassAUTOStep "23.08.13";
BA_ "Description" SG_ 40 L_ATCU_CampModeSta "Define the status of Camp Mode in EV";
BA_ "GenSigSendType" SG_ 40 L_ATCU_CampModeSta 4;
BA_ "UserSigValidity" SG_ 40 L_ATCU_CampModeSta 7;
BA_REL_ "GenSigTimeoutTime" BU_SG_REL_ L_2HKBD SG_ 40 L_ATCU_CampModeSta 1500;
BA_REL_ "GenSigTimeoutTime" BU_SG_REL_ L_3HKBD SG_ 40 L_ATCU_CampModeSta 1500;
BA_REL_ "GenSigTimeoutTime" BU_SG_REL_ L_EVNT SG_ 40 L_ATCU_CampModeSta 1500;
BA_REL_ "GenSigTimeoutTime" BU_SG_REL_ L_HKBD SG_ 40 L_ATCU_CampModeSta 1500;
BA_ "Version" SG_ 40 L_ATCU_CampModeSta "23.08.13";
BA_ "GenSigSendType" SG_ 40 L_ATCU_RrPassTempCDis 4;
BA_ "UserSigValidity" SG_ 40 L_ATCU_RrPassTempCDis 7;
BA_REL_ "GenSigTimeoutTime" BU_SG_REL_ L_2HKBD SG_ 40 L_ATCU_RrPassTempCDis 1500;
BA_REL_ "GenSigTimeoutTime" BU_SG_REL_ L_HKBD SG_ 40 L_ATCU_RrPassTempCDis 1500;
BA_ "Version" SG_ 40 L_ATCU_RrPassTempCDis "23.08.13";
BA_ "Description" SG_ 40 L_ATCU_UtilModeUsmSta "Timeout : Utility Mode OFF(Rest Mode OFF)";
BA_ "GenSigSendType" SG_ 40 L_ATCU_UtilModeUsmSta 4;
BA_ "UserSigValidity" SG_ 40 L_ATCU_UtilModeUsmSta 7;
BA_REL_ "GenSigTimeoutTime" BU_SG_REL_ L_2HKBD SG_ 40 L_ATCU_UtilModeUsmSta 1500;
BA_REL_ "GenSigTimeoutTime" BU_SG_REL_ L_3HKBD SG_ 40 L_ATCU_UtilModeUsmSta 1500;
BA_REL_ "GenSigTimeoutTime" BU_SG_REL_ L_EVNT SG_ 40 L_ATCU_UtilModeUsmSta 1500;
BA_REL_ "GenSigTimeoutTime" BU_SG_REL_ L_HKBD SG_ 40 L_ATCU_UtilModeUsmSta 1500;
BA_ "Version" SG_ 40 L_ATCU_UtilModeUsmSta "23.08.13";
BA_ "GenSigSendType" SG_ 40 L_ATCU_RrAcDis 4;
BA_ "UserSigValidity" SG_ 40 L_ATCU_RrAcDis 7;
BA_REL_ "GenSigTimeoutTime" BU_SG_REL_ L_2HKBD SG_ 40 L_ATCU_RrAcDis 1500;
BA_REL_ "GenSigTimeoutTime" BU_SG_REL_ L_3HKBD SG_ 40 L_ATCU_RrAcDis 1500;
BA_REL_ "GenSigTimeoutTime" BU_SG_REL_ L_HKBD SG_ 40 L_ATCU_RrAcDis 1500;
BA_ "Version" SG_ 40 L_ATCU_RrAcDis "24.02.01";
BA_ "GenSigSendType" SG_ 40 L_ATCU_3rdAcDis 4;
BA_ "UserSigValidity" SG_ 40 L_ATCU_3rdAcDis 7;
BA_REL_ "GenSigTimeoutTime" BU_SG_REL_ L_2HKBD SG_ 40 L_ATCU_3rdAcDis 1500;
BA_REL_ "GenSigTimeoutTime" BU_SG_REL_ L_3HKBD SG_ 40 L_ATCU_3rdAcDis 1500;
BA_REL_ "GenSigTimeoutTime" BU_SG_REL_ L_HKBD SG_ 40 L_ATCU_3rdAcDis 1500;
BA_ "Version" SG_ 40 L_ATCU_3rdAcDis "24.02.01";
BA_ "GenMsgSendType" BO_ 41 0;
BA_ "GenMsgCycleTime" BO_ 41 20;
BA_ "GenMsgCycleTimeFast" BO_ 41 0;
BA_ "GenMsgNrOfRepetition" BO_ 41 0;
BA_ "GenMsgDelayTime" BO_ 41 0;
BA_ "Description" SG_ 41 L_ATCU_OutTempDispC "This signal indicates Outside temperature (¡É).

(Use for display only)";
BA_ "UserSigValidity" SG_ 41 L_ATCU_OutTempDispC 7;
BA_ "Version" SG_ 41 L_ATCU_OutTempDispC "23.08.13";
BA_ "UserSigValidity" SG_ 41 L_ATCU_DtntOutSta 7;
BA_ "Version" SG_ 41 L_ATCU_DtntOutSta "23.08.13";
BA_ "UserSigValidity" SG_ 41 L_ATCU_AutoBrightSta 7;
BA_ "Version" SG_ 41 L_ATCU_AutoBrightSta "23.08.13";
BA_ "UserSigValidity" SG_ 41 L_ATCU_DustSnrVal 7;
BA_ "Version" SG_ 41 L_ATCU_DustSnrVal "23.08.13";
BA_ "Description" SG_ 41 L_ATCU_NotMinModeBrightSta "This signal indicates the bright level of original state. Original state means the previous state of Camp Mode.";
BA_ "UserSigValidity" SG_ 41 L_ATCU_NotMinModeBrightSta 7;
BA_ "Version" SG_ 41 L_ATCU_NotMinModeBrightSta "23.08.13";
BA_ "Description" SG_ 41 L_ATCU_IAUPrfleVal "This signal Indicate the Current detected Profile ID by IAU.

This signal is a signal that forwards profile signals from IAU to L_ATCU, and L_ATCU then forwards them as is to L_EVNT.(NOTICE : MAIN CAN's original validity is B+)";
BA_ "UserSigValidity" SG_ 41 L_ATCU_IAUPrfleVal 7;
BA_ "Version" SG_ 41 L_ATCU_IAUPrfleVal "24.03.06";
BA_ "Description" SG_ 41 L_ATCU_AVNPrfleVal "This signal is a signal that forwards profile signals from HU to L_ATCU, and L_ATCU then forwards them as is to L_EVNT.(NOTICE : MAIN CAN's original validity is B+) 

Profile 3~Profile9 value is only used from Vehicle Architecture 2.0 (STD_DB_CAR_R2, SV 24.6~) vehicle models Vehicle Architecture 1.0 (STD_DB_CAR) vehicle models can us";
BA_ "GenSigStartValue" SG_ 41 L_ATCU_AVNPrfleVal 15;
BA_ "UserSigValidity" SG_ 41 L_ATCU_AVNPrfleVal 7;
BA_ "Version" SG_ 41 L_ATCU_AVNPrfleVal "24.03.06";
BA_ "Description" SG_ 41 L_ATCU_SchdldClimateSta "Operation of the air conditioning system(NOT ROUTING)";
BA_ "UserSigValidity" SG_ 41 L_ATCU_SchdldClimateSta 7;
BA_ "Version" SG_ 41 L_ATCU_SchdldClimateSta "24.08.08";
BA_ "Description" SG_ 41 L_ATCU_OutTempDispF "This signal indicates Outside Temperature (¢µ)

(Use for display only)";
BA_ "UserSigValidity" SG_ 41 L_ATCU_OutTempDispF 7;
BA_ "Version" SG_ 41 L_ATCU_OutTempDispF "23.08.13";
BA_ "GenMsgSendType" BO_ 49 0;
BA_ "Description" SG_ 49 L_ATCU_ResetPreWrngForOthers "This is a PDC routing signal for reset preparing sideeffect of reset";
BA_ "GenSigSendType" SG_ 49 L_ATCU_ResetPreWrngForOthers 4;
BA_ "UserSigValidity" SG_ 49 L_ATCU_ResetPreWrngForOthers 0;
BA_REL_ "GenSigTimeoutTime" BU_SG_REL_ L_2HKBD SG_ 49 L_ATCU_ResetPreWrngForOthers 1500;
BA_REL_ "GenSigTimeoutTime" BU_SG_REL_ L_3HKBD SG_ 49 L_ATCU_ResetPreWrngForOthers 1500;
BA_REL_ "GenSigTimeoutTime" BU_SG_REL_ L_EVNT SG_ 49 L_ATCU_ResetPreWrngForOthers 1500;
BA_REL_ "GenSigTimeoutTime" BU_SG_REL_ L_HKBD SG_ 49 L_ATCU_ResetPreWrngForOthers 1500;
BA_REL_ "GenSigTimeoutTime" BU_SG_REL_ L_PCM SG_ 49 L_ATCU_ResetPreWrngForOthers 1500;
BA_ "Version" SG_ 49 L_ATCU_ResetPreWrngForOthers "24.07.02";
BA_ "Description" SG_ 49 L_ATCU_ResetReqForOthers "This is a PDC routing signal for SW reset except for Gateway";
BA_ "GenSigSendType" SG_ 49 L_ATCU_ResetReqForOthers 4;
BA_ "UserSigValidity" SG_ 49 L_ATCU_ResetReqForOthers 0;
BA_REL_ "GenSigTimeoutTime" BU_SG_REL_ L_2HKBD SG_ 49 L_ATCU_ResetReqForOthers 1500;
BA_REL_ "GenSigTimeoutTime" BU_SG_REL_ L_3HKBD SG_ 49 L_ATCU_ResetReqForOthers 1500;
BA_REL_ "GenSigTimeoutTime" BU_SG_REL_ L_EVNT SG_ 49 L_ATCU_ResetReqForOthers 1500;
BA_REL_ "GenSigTimeoutTime" BU_SG_REL_ L_HKBD SG_ 49 L_ATCU_ResetReqForOthers 1500;
BA_REL_ "GenSigTimeoutTime" BU_SG_REL_ L_PCM SG_ 49 L_ATCU_ResetReqForOthers 1500;
BA_ "Version" SG_ 49 L_ATCU_ResetReqForOthers "24.07.02";
BA_ "GenMsgSendType" BO_ 290 0;
BA_ "GenMsgCycleTime" BO_ 290 1000;
BA_ "GenMsgCycleTimeFast" BO_ 290 0;
BA_ "GenMsgNrOfRepetition" BO_ 290 0;
BA_ "Description" SG_ 290 L_ATCU_HU_FrDrEVntSideBdryUp_X "Electric Vent FRT Dr Side Electric Vent Upper Range X Coordinate";
BA_ "UserSigValidity" SG_ 290 L_ATCU_HU_FrDrEVntSideBdryUp_X 7;
BA_REL_ "GenSigTimeoutTime" BU_SG_REL_ L_EVNT SG_ 290 L_ATCU_HU_FrDrEVntSideBdryUp_X 5000;
BA_ "Version" SG_ 290 L_ATCU_HU_FrDrEVntSideBdryUp_X "24.05.11";
BA_ "Description" SG_ 290 L_ATCU_HU_FrDrEVntSideBdryLo_X "Electric Vent FRT Dr Side Electric Vent Lower Range X Coordinate";
BA_ "UserSigValidity" SG_ 290 L_ATCU_HU_FrDrEVntSideBdryLo_X 7;
BA_REL_ "GenSigTimeoutTime" BU_SG_REL_ L_EVNT SG_ 290 L_ATCU_HU_FrDrEVntSideBdryLo_X 5000;
BA_ "Version" SG_ 290 L_ATCU_HU_FrDrEVntSideBdryLo_X "24.05.11";
BA_ "Description" SG_ 290 L_ATCU_HU_FrDrEVntSideBdryLo_Y "Electric Vent FRT Dr Side Electric Vent Lower Range Y Coordinate";
BA_ "UserSigValidity" SG_ 290 L_ATCU_HU_FrDrEVntSideBdryLo_Y 7;
BA_REL_ "GenSigTimeoutTime" BU_SG_REL_ L_EVNT SG_ 290 L_ATCU_HU_FrDrEVntSideBdryLo_Y 5000;
BA_ "Version" SG_ 290 L_ATCU_HU_FrDrEVntSideBdryLo_Y "24.05.11";
BA_ "Description" SG_ 290 L_ATCU_HU_FrDrEVntCtrBdryUp_X "Electric Vent FRT Dr Center Electric Vent Upper Range X Coordinate";
BA_ "UserSigValidity" SG_ 290 L_ATCU_HU_FrDrEVntCtrBdryUp_X 7;
BA_REL_ "GenSigTimeoutTime" BU_SG_REL_ L_EVNT SG_ 290 L_ATCU_HU_FrDrEVntCtrBdryUp_X 5000;
BA_ "Version" SG_ 290 L_ATCU_HU_FrDrEVntCtrBdryUp_X "24.05.11";
BA_ "Description" SG_ 290 L_ATCU_HU_FrDrEVntCtrBdryUp_Y "Electric Vent FRT Dr Center Electric Vent Upper Range Y Coordinate";
BA_ "UserSigValidity" SG_ 290 L_ATCU_HU_FrDrEVntCtrBdryUp_Y 7;
BA_REL_ "GenSigTimeoutTime" BU_SG_REL_ L_EVNT SG_ 290 L_ATCU_HU_FrDrEVntCtrBdryUp_Y 5000;
BA_ "Version" SG_ 290 L_ATCU_HU_FrDrEVntCtrBdryUp_Y "24.05.11";
BA_ "Description" SG_ 290 L_ATCU_HU_FrDrEVntCtrBdryLo_X "Electric Vent FRT Dr Center Electric Vent Lower Range X Coordinate";
BA_ "UserSigValidity" SG_ 290 L_ATCU_HU_FrDrEVntCtrBdryLo_X 7;
BA_REL_ "GenSigTimeoutTime" BU_SG_REL_ L_EVNT SG_ 290 L_ATCU_HU_FrDrEVntCtrBdryLo_X 5000;
BA_ "Version" SG_ 290 L_ATCU_HU_FrDrEVntCtrBdryLo_X "24.05.11";
BA_ "Description" SG_ 290 L_ATCU_HU_FrDrEVntCtrBdryLo_Y "Electric Vent FRT Dr Center Electric Vent Lower Range Y Coordinate";
BA_ "UserSigValidity" SG_ 290 L_ATCU_HU_FrDrEVntCtrBdryLo_Y 7;
BA_REL_ "GenSigTimeoutTime" BU_SG_REL_ L_EVNT SG_ 290 L_ATCU_HU_FrDrEVntCtrBdryLo_Y 5000;
BA_ "Version" SG_ 290 L_ATCU_HU_FrDrEVntCtrBdryLo_Y "24.05.11";
BA_ "Description" SG_ 290 L_ATCU_HU_FrDrEVntSideBdryUp_Y "Electric Vent FRT Dr Side Electric Vent Upper Range Y Coordinate";
BA_ "UserSigValidity" SG_ 290 L_ATCU_HU_FrDrEVntSideBdryUp_Y 7;
BA_REL_ "GenSigTimeoutTime" BU_SG_REL_ L_EVNT SG_ 290 L_ATCU_HU_FrDrEVntSideBdryUp_Y 5000;
BA_ "Version" SG_ 290 L_ATCU_HU_FrDrEVntSideBdryUp_Y "24.05.11";
BA_ "GenMsgSendType" BO_ 291 0;
BA_ "GenMsgCycleTime" BO_ 291 1000;
BA_ "GenMsgCycleTimeFast" BO_ 291 0;
BA_ "GenMsgNrOfRepetition" BO_ 291 0;
BA_ "Description" SG_ 291 L_ATCU_HU_FrPsEVntSideBdryUp_X "Electric Vent FRT Ps Side Electric Vent Upper Range X Coordinate";
BA_ "UserSigValidity" SG_ 291 L_ATCU_HU_FrPsEVntSideBdryUp_X 7;
BA_REL_ "GenSigTimeoutTime" BU_SG_REL_ L_EVNT SG_ 291 L_ATCU_HU_FrPsEVntSideBdryUp_X 5000;
BA_ "Version" SG_ 291 L_ATCU_HU_FrPsEVntSideBdryUp_X "24.05.11";
BA_ "Description" SG_ 291 L_ATCU_HU_FrPsEVntSideBdryLo_X "Electric Vent FRT Ps Side Electric Vent Lower Range X Coordinate";
BA_ "UserSigValidity" SG_ 291 L_ATCU_HU_FrPsEVntSideBdryLo_X 7;
BA_REL_ "GenSigTimeoutTime" BU_SG_REL_ L_EVNT SG_ 291 L_ATCU_HU_FrPsEVntSideBdryLo_X 5000;
BA_ "Version" SG_ 291 L_ATCU_HU_FrPsEVntSideBdryLo_X "24.05.11";
BA_ "Description" SG_ 291 L_ATCU_HU_FrPsEVntSideBdryLo_Y "Electric Vent FRT Ps Side Electric Vent Lower Range Y Coordinate";
BA_ "UserSigValidity" SG_ 291 L_ATCU_HU_FrPsEVntSideBdryLo_Y 7;
BA_REL_ "GenSigTimeoutTime" BU_SG_REL_ L_EVNT SG_ 291 L_ATCU_HU_FrPsEVntSideBdryLo_Y 5000;
BA_ "Version" SG_ 291 L_ATCU_HU_FrPsEVntSideBdryLo_Y "24.05.11";
BA_ "Description" SG_ 291 L_ATCU_HU_FrPsEVntCtrBdryUp_X "Electric Vent FRT Ps Center Electric Vent Upper Range X Coordinate";
BA_ "UserSigValidity" SG_ 291 L_ATCU_HU_FrPsEVntCtrBdryUp_X 7;
BA_REL_ "GenSigTimeoutTime" BU_SG_REL_ L_EVNT SG_ 291 L_ATCU_HU_FrPsEVntCtrBdryUp_X 5000;
BA_ "Version" SG_ 291 L_ATCU_HU_FrPsEVntCtrBdryUp_X "24.05.11";
BA_ "Description" SG_ 291 L_ATCU_HU_FrPsEVntCtrBdryUp_Y "Electric Vent FRT Ps Center Electric Vent Upper Range Y Coordinate";
BA_ "UserSigValidity" SG_ 291 L_ATCU_HU_FrPsEVntCtrBdryUp_Y 7;
BA_REL_ "GenSigTimeoutTime" BU_SG_REL_ L_EVNT SG_ 291 L_ATCU_HU_FrPsEVntCtrBdryUp_Y 5000;
BA_ "Version" SG_ 291 L_ATCU_HU_FrPsEVntCtrBdryUp_Y "24.05.11";
BA_ "Description" SG_ 291 L_ATCU_HU_FrPsEVntCtrBdryLo_X "Electric Vent FRT Ps Center Electric Vent Lower Range X Coordinate";
BA_ "UserSigValidity" SG_ 291 L_ATCU_HU_FrPsEVntCtrBdryLo_X 7;
BA_REL_ "GenSigTimeoutTime" BU_SG_REL_ L_EVNT SG_ 291 L_ATCU_HU_FrPsEVntCtrBdryLo_X 5000;
BA_ "Version" SG_ 291 L_ATCU_HU_FrPsEVntCtrBdryLo_X "24.05.11";
BA_ "Description" SG_ 291 L_ATCU_HU_FrPsEVntCtrBdryLo_Y "Electric Vent FRT Ps Center Electric Vent Lower Range Y Coordinate";
BA_ "UserSigValidity" SG_ 291 L_ATCU_HU_FrPsEVntCtrBdryLo_Y 7;
BA_REL_ "GenSigTimeoutTime" BU_SG_REL_ L_EVNT SG_ 291 L_ATCU_HU_FrPsEVntCtrBdryLo_Y 5000;
BA_ "Version" SG_ 291 L_ATCU_HU_FrPsEVntCtrBdryLo_Y "24.05.11";
BA_ "Description" SG_ 291 L_ATCU_HU_FrPsEVntSideBdryUp_Y "Electric Vent FRT Ps Side Electric Vent Upper Range Y Coordinate";
BA_ "UserSigValidity" SG_ 291 L_ATCU_HU_FrPsEVntSideBdryUp_Y 7;
BA_REL_ "GenSigTimeoutTime" BU_SG_REL_ L_EVNT SG_ 291 L_ATCU_HU_FrPsEVntSideBdryUp_Y 5000;
BA_ "Version" SG_ 291 L_ATCU_HU_FrPsEVntSideBdryUp_Y "24.05.11";
BA_ "GenMsgSendType" BO_ 292 0;
BA_ "GenMsgCycleTime" BO_ 292 1000;
BA_ "GenMsgCycleTimeFast" BO_ 292 0;
BA_ "GenMsgNrOfRepetition" BO_ 292 0;
BA_ "Description" SG_ 292 L_ATCU_HU_RrDrEVntConsBdryUp_X "Electric Vent RR Dr Console Electric Vent Upper Range X Coordinate";
BA_ "UserSigValidity" SG_ 292 L_ATCU_HU_RrDrEVntConsBdryUp_X 7;
BA_REL_ "GenSigTimeoutTime" BU_SG_REL_ L_EVNT SG_ 292 L_ATCU_HU_RrDrEVntConsBdryUp_X 5000;
BA_ "Version" SG_ 292 L_ATCU_HU_RrDrEVntConsBdryUp_X "24.05.11";
BA_ "Description" SG_ 292 L_ATCU_HU_RrDrEVntConsBdryLo_X "Electric Vent RR Dr Console Electric Vent Lower Range X Coordinate";
BA_ "UserSigValidity" SG_ 292 L_ATCU_HU_RrDrEVntConsBdryLo_X 7;
BA_REL_ "GenSigTimeoutTime" BU_SG_REL_ L_EVNT SG_ 292 L_ATCU_HU_RrDrEVntConsBdryLo_X 5000;
BA_ "Version" SG_ 292 L_ATCU_HU_RrDrEVntConsBdryLo_X "24.05.11";
BA_ "Description" SG_ 292 L_ATCU_HU_RrDrEVntConsBdryLo_Y "Electric Vent RR Dr Console Electric Vent Lower Range Y Coordinate";
BA_ "UserSigValidity" SG_ 292 L_ATCU_HU_RrDrEVntConsBdryLo_Y 7;
BA_REL_ "GenSigTimeoutTime" BU_SG_REL_ L_EVNT SG_ 292 L_ATCU_HU_RrDrEVntConsBdryLo_Y 5000;
BA_ "Version" SG_ 292 L_ATCU_HU_RrDrEVntConsBdryLo_Y "24.05.11";
BA_ "Description" SG_ 292 L_ATCU_HU_RrPsEVntConsBdryUp_X "Electric Vent RR Ps Console Electric Vent Upper Range X Coordinate";
BA_ "UserSigValidity" SG_ 292 L_ATCU_HU_RrPsEVntConsBdryUp_X 7;
BA_REL_ "GenSigTimeoutTime" BU_SG_REL_ L_EVNT SG_ 292 L_ATCU_HU_RrPsEVntConsBdryUp_X 5000;
BA_ "Version" SG_ 292 L_ATCU_HU_RrPsEVntConsBdryUp_X "24.05.11";
BA_ "Description" SG_ 292 L_ATCU_HU_RrPsEVntConsBdryUp_Y "Electric Vent RR Ps Console Electric Vent Upper Range Y Coordinate";
BA_ "UserSigValidity" SG_ 292 L_ATCU_HU_RrPsEVntConsBdryUp_Y 7;
BA_REL_ "GenSigTimeoutTime" BU_SG_REL_ L_EVNT SG_ 292 L_ATCU_HU_RrPsEVntConsBdryUp_Y 5000;
BA_ "Version" SG_ 292 L_ATCU_HU_RrPsEVntConsBdryUp_Y "24.05.11";
BA_ "Description" SG_ 292 L_ATCU_HU_RrPsEVntConsBdryLo_X "Electric Vent RR Ps Console Electric Vent Lower Range X Coordinate";
BA_ "UserSigValidity" SG_ 292 L_ATCU_HU_RrPsEVntConsBdryLo_X 7;
BA_REL_ "GenSigTimeoutTime" BU_SG_REL_ L_EVNT SG_ 292 L_ATCU_HU_RrPsEVntConsBdryLo_X 5000;
BA_ "Version" SG_ 292 L_ATCU_HU_RrPsEVntConsBdryLo_X "24.05.11";
BA_ "Description" SG_ 292 L_ATCU_HU_RrPsEVntConsBdryLo_Y "Electric Vent RR Ps Console Electric Vent Lower Range Y Coordinate";
BA_ "UserSigValidity" SG_ 292 L_ATCU_HU_RrPsEVntConsBdryLo_Y 7;
BA_REL_ "GenSigTimeoutTime" BU_SG_REL_ L_EVNT SG_ 292 L_ATCU_HU_RrPsEVntConsBdryLo_Y 5000;
BA_ "Version" SG_ 292 L_ATCU_HU_RrPsEVntConsBdryLo_Y "24.05.11";
BA_ "Description" SG_ 292 L_ATCU_HU_RrDrEVntConsBdryUp_Y "Electric Vent RR Dr Console Electric Vent Upper Range Y Coordinate";
BA_ "UserSigValidity" SG_ 292 L_ATCU_HU_RrDrEVntConsBdryUp_Y 7;
BA_REL_ "GenSigTimeoutTime" BU_SG_REL_ L_EVNT SG_ 292 L_ATCU_HU_RrDrEVntConsBdryUp_Y 5000;
BA_ "Version" SG_ 292 L_ATCU_HU_RrDrEVntConsBdryUp_Y "24.05.11";
BA_ "GenMsgCycleTime" BO_ 293 0;
BA_ "Description" SG_ 293 L_ATCU_CTS_FrDrEVntSidePt_X "Electric Vent FRT Dr Side Vent Select Point X Coordinate";
BA_ "GenSigSendType" SG_ 293 L_ATCU_CTS_FrDrEVntSidePt_X 4;
BA_ "UserSigValidity" SG_ 293 L_ATCU_CTS_FrDrEVntSidePt_X 7;
BA_REL_ "GenSigTimeoutTime" BU_SG_REL_ L_EVNT SG_ 293 L_ATCU_CTS_FrDrEVntSidePt_X 0;
BA_ "Version" SG_ 293 L_ATCU_CTS_FrDrEVntSidePt_X "24.05.11";
BA_ "Description" SG_ 293 L_ATCU_CTS_FrDrEVntSidePt_Y "Electric Vent FRT Dr Side Vent Select Point Y Coordinate";
BA_ "GenSigSendType" SG_ 293 L_ATCU_CTS_FrDrEVntSidePt_Y 4;
BA_ "UserSigValidity" SG_ 293 L_ATCU_CTS_FrDrEVntSidePt_Y 7;
BA_REL_ "GenSigTimeoutTime" BU_SG_REL_ L_EVNT SG_ 293 L_ATCU_CTS_FrDrEVntSidePt_Y 0;
BA_ "Version" SG_ 293 L_ATCU_CTS_FrDrEVntSidePt_Y "24.05.11";
BA_ "Description" SG_ 293 L_ATCU_CTS_FrDrEVntCtrPt_X "Electric Vent FRT Dr Center Vent Select Point X Coordinate";
BA_ "GenSigSendType" SG_ 293 L_ATCU_CTS_FrDrEVntCtrPt_X 4;
BA_ "UserSigValidity" SG_ 293 L_ATCU_CTS_FrDrEVntCtrPt_X 7;
BA_REL_ "GenSigTimeoutTime" BU_SG_REL_ L_EVNT SG_ 293 L_ATCU_CTS_FrDrEVntCtrPt_X 0;
BA_ "Version" SG_ 293 L_ATCU_CTS_FrDrEVntCtrPt_X "24.05.11";
BA_ "Description" SG_ 293 L_ATCU_CTS_FrDrEVntCtrPt_Y "Electric Vent FRT Dr Center Vent Select Point Y Coordinate";
BA_ "GenSigSendType" SG_ 293 L_ATCU_CTS_FrDrEVntCtrPt_Y 4;
BA_ "UserSigValidity" SG_ 293 L_ATCU_CTS_FrDrEVntCtrPt_Y 7;
BA_REL_ "GenSigTimeoutTime" BU_SG_REL_ L_EVNT SG_ 293 L_ATCU_CTS_FrDrEVntCtrPt_Y 0;
BA_ "Version" SG_ 293 L_ATCU_CTS_FrDrEVntCtrPt_Y "24.05.11";
BA_ "GenMsgCycleTime" BO_ 294 0;
BA_ "Description" SG_ 294 L_ATCU_CTS_FrPsEVntSidePt_X "Electric Vent FRT Ps Side Vent Select Point X Coordinate";
BA_ "GenSigSendType" SG_ 294 L_ATCU_CTS_FrPsEVntSidePt_X 4;
BA_ "UserSigValidity" SG_ 294 L_ATCU_CTS_FrPsEVntSidePt_X 7;
BA_REL_ "GenSigTimeoutTime" BU_SG_REL_ L_EVNT SG_ 294 L_ATCU_CTS_FrPsEVntSidePt_X 0;
BA_ "Version" SG_ 294 L_ATCU_CTS_FrPsEVntSidePt_X "24.05.11";
BA_ "Description" SG_ 294 L_ATCU_CTS_FrPsEVntSidePt_Y "Electric Vent FRT Ps Side Vent Select Point Y Coordinate";
BA_ "GenSigSendType" SG_ 294 L_ATCU_CTS_FrPsEVntSidePt_Y 4;
BA_ "UserSigValidity" SG_ 294 L_ATCU_CTS_FrPsEVntSidePt_Y 7;
BA_REL_ "GenSigTimeoutTime" BU_SG_REL_ L_EVNT SG_ 294 L_ATCU_CTS_FrPsEVntSidePt_Y 0;
BA_ "Version" SG_ 294 L_ATCU_CTS_FrPsEVntSidePt_Y "24.05.11";
BA_ "Description" SG_ 294 L_ATCU_CTS_FrPsEVntCtrPt_X "Electric Vent FRT Ps Center Vent Select Point X Coordinate";
BA_ "GenSigSendType" SG_ 294 L_ATCU_CTS_FrPsEVntCtrPt_X 4;
BA_ "UserSigValidity" SG_ 294 L_ATCU_CTS_FrPsEVntCtrPt_X 7;
BA_REL_ "GenSigTimeoutTime" BU_SG_REL_ L_EVNT SG_ 294 L_ATCU_CTS_FrPsEVntCtrPt_X 0;
BA_ "Version" SG_ 294 L_ATCU_CTS_FrPsEVntCtrPt_X "24.05.11";
BA_ "Description" SG_ 294 L_ATCU_CTS_FrPsEVntCtrPt_Y "Electric Vent FRT Ps Center Vent Select Point Y Coordinate";
BA_ "GenSigSendType" SG_ 294 L_ATCU_CTS_FrPsEVntCtrPt_Y 4;
BA_ "UserSigValidity" SG_ 294 L_ATCU_CTS_FrPsEVntCtrPt_Y 7;
BA_REL_ "GenSigTimeoutTime" BU_SG_REL_ L_EVNT SG_ 294 L_ATCU_CTS_FrPsEVntCtrPt_Y 0;
BA_ "Version" SG_ 294 L_ATCU_CTS_FrPsEVntCtrPt_Y "24.05.11";
BA_ "GenMsgCycleTime" BO_ 295 0;
BA_ "Description" SG_ 295 L_ATCU_CTS_RrDrEVntConsPt_X "Electric Vent RR Dr Console Vent Select Point X Coordinate";
BA_ "GenSigSendType" SG_ 295 L_ATCU_CTS_RrDrEVntConsPt_X 4;
BA_ "UserSigValidity" SG_ 295 L_ATCU_CTS_RrDrEVntConsPt_X 7;
BA_REL_ "GenSigTimeoutTime" BU_SG_REL_ L_EVNT SG_ 295 L_ATCU_CTS_RrDrEVntConsPt_X 0;
BA_ "Version" SG_ 295 L_ATCU_CTS_RrDrEVntConsPt_X "24.05.11";
BA_ "Description" SG_ 295 L_ATCU_CTS_RrDrEVntConsPt_Y "Electric Vent RR Dr Console Vent Select Point Y Coordinate";
BA_ "GenSigSendType" SG_ 295 L_ATCU_CTS_RrDrEVntConsPt_Y 4;
BA_ "UserSigValidity" SG_ 295 L_ATCU_CTS_RrDrEVntConsPt_Y 7;
BA_REL_ "GenSigTimeoutTime" BU_SG_REL_ L_EVNT SG_ 295 L_ATCU_CTS_RrDrEVntConsPt_Y 0;
BA_ "Version" SG_ 295 L_ATCU_CTS_RrDrEVntConsPt_Y "24.05.11";
BA_ "Description" SG_ 295 L_ATCU_CTS_RrPsEVntConsPt_X "Electric Vent RR Ps Console Vent Select Point X Coordinate";
BA_ "GenSigSendType" SG_ 295 L_ATCU_CTS_RrPsEVntConsPt_X 4;
BA_ "UserSigValidity" SG_ 295 L_ATCU_CTS_RrPsEVntConsPt_X 7;
BA_REL_ "GenSigTimeoutTime" BU_SG_REL_ L_EVNT SG_ 295 L_ATCU_CTS_RrPsEVntConsPt_X 0;
BA_ "Version" SG_ 295 L_ATCU_CTS_RrPsEVntConsPt_X "24.05.11";
BA_ "Description" SG_ 295 L_ATCU_CTS_RrPsEVntConsPt_Y "Electric Vent RR Ps Console Vent Select Point Y Coordinate";
BA_ "GenSigSendType" SG_ 295 L_ATCU_CTS_RrPsEVntConsPt_Y 4;
BA_ "UserSigValidity" SG_ 295 L_ATCU_CTS_RrPsEVntConsPt_Y 7;
BA_REL_ "GenSigTimeoutTime" BU_SG_REL_ L_EVNT SG_ 295 L_ATCU_CTS_RrPsEVntConsPt_Y 0;
BA_ "Version" SG_ 295 L_ATCU_CTS_RrPsEVntConsPt_Y "24.05.11";
BA_ "Description" SG_ 295 L_ATCU_CTS_RrDrEVntModeSet "Electric Vent Mode_Rr Dr";
BA_ "GenSigSendType" SG_ 295 L_ATCU_CTS_RrDrEVntModeSet 4;
BA_ "UserSigValidity" SG_ 295 L_ATCU_CTS_RrDrEVntModeSet 7;
BA_REL_ "GenSigTimeoutTime" BU_SG_REL_ L_EVNT SG_ 295 L_ATCU_CTS_RrDrEVntModeSet 0;
BA_ "Version" SG_ 295 L_ATCU_CTS_RrDrEVntModeSet "24.08.00";
BA_ "Description" SG_ 295 L_ATCU_CTS_RrPsEVntModeSet "Electric Vent Mode_Rr Ps";
BA_ "GenSigSendType" SG_ 295 L_ATCU_CTS_RrPsEVntModeSet 4;
BA_ "UserSigValidity" SG_ 295 L_ATCU_CTS_RrPsEVntModeSet 7;
BA_REL_ "GenSigTimeoutTime" BU_SG_REL_ L_EVNT SG_ 295 L_ATCU_CTS_RrPsEVntModeSet 0;
BA_ "Version" SG_ 295 L_ATCU_CTS_RrPsEVntModeSet "24.08.00";
BA_ "Description" SG_ 295 L_ATCU_CTS_RrDrEVntConsOpnCls "Electric Vent RR Dr Console Vent Open/Close Signal";
BA_ "GenSigSendType" SG_ 295 L_ATCU_CTS_RrDrEVntConsOpnCls 4;
BA_ "UserSigValidity" SG_ 295 L_ATCU_CTS_RrDrEVntConsOpnCls 7;
BA_REL_ "GenSigTimeoutTime" BU_SG_REL_ L_EVNT SG_ 295 L_ATCU_CTS_RrDrEVntConsOpnCls 0;
BA_ "Version" SG_ 295 L_ATCU_CTS_RrDrEVntConsOpnCls "24.05.11";
BA_ "Description" SG_ 295 L_ATCU_CTS_RrPsEVntConsOpnCls "Electric Vent RR Ps Console Vent Open/Close Signal";
BA_ "GenSigSendType" SG_ 295 L_ATCU_CTS_RrPsEVntConsOpnCls 4;
BA_ "UserSigValidity" SG_ 295 L_ATCU_CTS_RrPsEVntConsOpnCls 7;
BA_REL_ "GenSigTimeoutTime" BU_SG_REL_ L_EVNT SG_ 295 L_ATCU_CTS_RrPsEVntConsOpnCls 0;
BA_ "Version" SG_ 295 L_ATCU_CTS_RrPsEVntConsOpnCls "24.05.11";
BA_ "GenMsgSendType" BO_ 296 0;
BA_ "GenMsgCycleTime" BO_ 296 1000;
BA_ "GenMsgCycleTimeFast" BO_ 296 0;
BA_ "GenMsgNrOfRepetition" BO_ 296 0;
BA_ "Description" SG_ 296 L_ATCU_CTS_FrDrEVntSideBdryUp_X "Electric Vent FRT Dr Side Electric Vent Upper Range X Coordinate";
BA_ "UserSigValidity" SG_ 296 L_ATCU_CTS_FrDrEVntSideBdryUp_X 7;
BA_REL_ "GenSigTimeoutTime" BU_SG_REL_ L_EVNT SG_ 296 L_ATCU_CTS_FrDrEVntSideBdryUp_X 5000;
BA_ "Version" SG_ 296 L_ATCU_CTS_FrDrEVntSideBdryUp_X "24.05.11";
BA_ "Description" SG_ 296 L_ATCU_CTS_FrDrEVntSideBdryLo_X "Electric Vent FRT Dr Side Electric Vent Lower Range X Coordinate";
BA_ "UserSigValidity" SG_ 296 L_ATCU_CTS_FrDrEVntSideBdryLo_X 7;
BA_REL_ "GenSigTimeoutTime" BU_SG_REL_ L_EVNT SG_ 296 L_ATCU_CTS_FrDrEVntSideBdryLo_X 5000;
BA_ "Version" SG_ 296 L_ATCU_CTS_FrDrEVntSideBdryLo_X "24.05.11";
BA_ "Description" SG_ 296 L_ATCU_CTS_FrDrEVntSideBdryLo_Y "Electric Vent FRT Dr Side Electric Vent Lower Range Y Coordinate";
BA_ "UserSigValidity" SG_ 296 L_ATCU_CTS_FrDrEVntSideBdryLo_Y 7;
BA_REL_ "GenSigTimeoutTime" BU_SG_REL_ L_EVNT SG_ 296 L_ATCU_CTS_FrDrEVntSideBdryLo_Y 5000;
BA_ "Version" SG_ 296 L_ATCU_CTS_FrDrEVntSideBdryLo_Y "24.05.11";
BA_ "Description" SG_ 296 L_ATCU_CTS_FrDrEVntCtrBdryUp_X "Electric Vent FRT Dr Center Electric Vent Upper Range X Coordinate";
BA_ "UserSigValidity" SG_ 296 L_ATCU_CTS_FrDrEVntCtrBdryUp_X 7;
BA_REL_ "GenSigTimeoutTime" BU_SG_REL_ L_EVNT SG_ 296 L_ATCU_CTS_FrDrEVntCtrBdryUp_X 5000;
BA_ "Version" SG_ 296 L_ATCU_CTS_FrDrEVntCtrBdryUp_X "24.05.11";
BA_ "Description" SG_ 296 L_ATCU_CTS_FrDrEVntCtrBdryUp_Y "Electric Vent FRT Dr Center Electric Vent Upper Range Y Coordinate";
BA_ "UserSigValidity" SG_ 296 L_ATCU_CTS_FrDrEVntCtrBdryUp_Y 7;
BA_REL_ "GenSigTimeoutTime" BU_SG_REL_ L_EVNT SG_ 296 L_ATCU_CTS_FrDrEVntCtrBdryUp_Y 5000;
BA_ "Version" SG_ 296 L_ATCU_CTS_FrDrEVntCtrBdryUp_Y "24.05.11";
BA_ "Description" SG_ 296 L_ATCU_CTS_FrDrEVntCtrBdryLo_X "Electric Vent FRT Dr Center Electric Vent Lower Range X Coordinate";
BA_ "UserSigValidity" SG_ 296 L_ATCU_CTS_FrDrEVntCtrBdryLo_X 7;
BA_REL_ "GenSigTimeoutTime" BU_SG_REL_ L_EVNT SG_ 296 L_ATCU_CTS_FrDrEVntCtrBdryLo_X 5000;
BA_ "Version" SG_ 296 L_ATCU_CTS_FrDrEVntCtrBdryLo_X "24.05.11";
BA_ "Description" SG_ 296 L_ATCU_CTS_FrDrEVntCtrBdryLo_Y "Electric Vent FRT Dr Center Electric Vent Lower Range Y Coordinate";
BA_ "UserSigValidity" SG_ 296 L_ATCU_CTS_FrDrEVntCtrBdryLo_Y 7;
BA_REL_ "GenSigTimeoutTime" BU_SG_REL_ L_EVNT SG_ 296 L_ATCU_CTS_FrDrEVntCtrBdryLo_Y 5000;
BA_ "Version" SG_ 296 L_ATCU_CTS_FrDrEVntCtrBdryLo_Y "24.05.11";
BA_ "Description" SG_ 296 L_ATCU_CTS_FrDrEVntSideBdryUp_Y "Electric Vent FRT Dr Side Electric Vent Upper Range Y Coordinate";
BA_ "UserSigValidity" SG_ 296 L_ATCU_CTS_FrDrEVntSideBdryUp_Y 7;
BA_REL_ "GenSigTimeoutTime" BU_SG_REL_ L_EVNT SG_ 296 L_ATCU_CTS_FrDrEVntSideBdryUp_Y 5000;
BA_ "Version" SG_ 296 L_ATCU_CTS_FrDrEVntSideBdryUp_Y "24.05.11";
BA_ "GenMsgSendType" BO_ 297 0;
BA_ "GenMsgCycleTime" BO_ 297 1000;
BA_ "GenMsgCycleTimeFast" BO_ 297 0;
BA_ "GenMsgNrOfRepetition" BO_ 297 0;
BA_ "Description" SG_ 297 L_ATCU_CTS_FrPsEVntSideBdryUp_X "Electric Vent FRT Ps Side Electric Vent Upper Range X Coordinate";
BA_ "UserSigValidity" SG_ 297 L_ATCU_CTS_FrPsEVntSideBdryUp_X 7;
BA_REL_ "GenSigTimeoutTime" BU_SG_REL_ L_EVNT SG_ 297 L_ATCU_CTS_FrPsEVntSideBdryUp_X 5000;
BA_ "Version" SG_ 297 L_ATCU_CTS_FrPsEVntSideBdryUp_X "24.05.11";
BA_ "Description" SG_ 297 L_ATCU_CTS_FrPsEVntSideBdryLo_X "Electric Vent FRT Ps Side Electric Vent Lower Range X Coordinate";
BA_ "UserSigValidity" SG_ 297 L_ATCU_CTS_FrPsEVntSideBdryLo_X 7;
BA_REL_ "GenSigTimeoutTime" BU_SG_REL_ L_EVNT SG_ 297 L_ATCU_CTS_FrPsEVntSideBdryLo_X 5000;
BA_ "Version" SG_ 297 L_ATCU_CTS_FrPsEVntSideBdryLo_X "24.05.11";
BA_ "Description" SG_ 297 L_ATCU_CTS_FrPsEVntSideBdryLo_Y "Electric Vent FRT Ps Side Electric Vent Lower Range Y Coordinate";
BA_ "UserSigValidity" SG_ 297 L_ATCU_CTS_FrPsEVntSideBdryLo_Y 7;
BA_REL_ "GenSigTimeoutTime" BU_SG_REL_ L_EVNT SG_ 297 L_ATCU_CTS_FrPsEVntSideBdryLo_Y 5000;
BA_ "Version" SG_ 297 L_ATCU_CTS_FrPsEVntSideBdryLo_Y "24.05.11";
BA_ "Description" SG_ 297 L_ATCU_CTS_FrPsEVntCtrBdryUp_X "Electric Vent FRT Ps Center Electric Vent Upper Range X Coordinate";
BA_ "UserSigValidity" SG_ 297 L_ATCU_CTS_FrPsEVntCtrBdryUp_X 7;
BA_REL_ "GenSigTimeoutTime" BU_SG_REL_ L_EVNT SG_ 297 L_ATCU_CTS_FrPsEVntCtrBdryUp_X 5000;
BA_ "Version" SG_ 297 L_ATCU_CTS_FrPsEVntCtrBdryUp_X "24.05.11";
BA_ "Description" SG_ 297 L_ATCU_CTS_FrPsEVntCtrBdryUp_Y "Electric Vent FRT Ps Center Electric Vent Upper Range Y Coordinate";
BA_ "UserSigValidity" SG_ 297 L_ATCU_CTS_FrPsEVntCtrBdryUp_Y 7;
BA_REL_ "GenSigTimeoutTime" BU_SG_REL_ L_EVNT SG_ 297 L_ATCU_CTS_FrPsEVntCtrBdryUp_Y 5000;
BA_ "Version" SG_ 297 L_ATCU_CTS_FrPsEVntCtrBdryUp_Y "24.05.11";
BA_ "Description" SG_ 297 L_ATCU_CTS_FrPsEVntCtrBdryLo_X "Electric Vent FRT Ps Center Electric Vent Lower Range X Coordinate";
BA_ "UserSigValidity" SG_ 297 L_ATCU_CTS_FrPsEVntCtrBdryLo_X 7;
BA_REL_ "GenSigTimeoutTime" BU_SG_REL_ L_EVNT SG_ 297 L_ATCU_CTS_FrPsEVntCtrBdryLo_X 5000;
BA_ "Version" SG_ 297 L_ATCU_CTS_FrPsEVntCtrBdryLo_X "24.05.11";
BA_ "Description" SG_ 297 L_ATCU_CTS_FrPsEVntCtrBdryLo_Y "Electric Vent FRT Ps Center Electric Vent Lower Range Y Coordinate";
BA_ "UserSigValidity" SG_ 297 L_ATCU_CTS_FrPsEVntCtrBdryLo_Y 7;
BA_REL_ "GenSigTimeoutTime" BU_SG_REL_ L_EVNT SG_ 297 L_ATCU_CTS_FrPsEVntCtrBdryLo_Y 5000;
BA_ "Version" SG_ 297 L_ATCU_CTS_FrPsEVntCtrBdryLo_Y "24.05.11";
BA_ "Description" SG_ 297 L_ATCU_CTS_FrPsEVntSideBdryUp_Y "Electric Vent FRT Ps Side Electric Vent Upper Range Y Coordinate";
BA_ "UserSigValidity" SG_ 297 L_ATCU_CTS_FrPsEVntSideBdryUp_Y 7;
BA_REL_ "GenSigTimeoutTime" BU_SG_REL_ L_EVNT SG_ 297 L_ATCU_CTS_FrPsEVntSideBdryUp_Y 5000;
BA_ "Version" SG_ 297 L_ATCU_CTS_FrPsEVntSideBdryUp_Y "24.05.11";
BA_ "GenMsgCycleTime" BO_ 353 0;
BA_ "Description" SG_ 353 L_ATCU_HU_FrDrEVntModeSet "Electric Vent Frt Driver Mode Signal";
BA_ "GenSigSendType" SG_ 353 L_ATCU_HU_FrDrEVntModeSet 4;
BA_ "UserSigValidity" SG_ 353 L_ATCU_HU_FrDrEVntModeSet 7;
BA_REL_ "GenSigTimeoutTime" BU_SG_REL_ L_EVNT SG_ 353 L_ATCU_HU_FrDrEVntModeSet 0;
BA_ "Version" SG_ 353 L_ATCU_HU_FrDrEVntModeSet "24.08.00";
BA_ "Description" SG_ 353 L_ATCU_HU_FrDrEVntCtrOpnCls "Electric Vent Frt Driver Center Vent Open/Close Signal";
BA_ "GenSigSendType" SG_ 353 L_ATCU_HU_FrDrEVntCtrOpnCls 4;
BA_ "UserSigValidity" SG_ 353 L_ATCU_HU_FrDrEVntCtrOpnCls 7;
BA_REL_ "GenSigTimeoutTime" BU_SG_REL_ L_EVNT SG_ 353 L_ATCU_HU_FrDrEVntCtrOpnCls 0;
BA_ "Version" SG_ 353 L_ATCU_HU_FrDrEVntCtrOpnCls "24.05.11";
BA_ "Description" SG_ 353 L_ATCU_HU_FrPsEVntSideOpnCls "Electric Vent Frt Passenger Side Vent Open/Close Signal";
BA_ "GenSigSendType" SG_ 353 L_ATCU_HU_FrPsEVntSideOpnCls 4;
BA_ "UserSigValidity" SG_ 353 L_ATCU_HU_FrPsEVntSideOpnCls 7;
BA_REL_ "GenSigTimeoutTime" BU_SG_REL_ L_EVNT SG_ 353 L_ATCU_HU_FrPsEVntSideOpnCls 0;
BA_ "Version" SG_ 353 L_ATCU_HU_FrPsEVntSideOpnCls "24.05.11";
BA_ "Description" SG_ 353 L_ATCU_HU_FrPsEVntCtrOpnCls "Electric Vent Frt Passenger Center Vent Open/Close Signal";
BA_ "GenSigSendType" SG_ 353 L_ATCU_HU_FrPsEVntCtrOpnCls 4;
BA_ "UserSigValidity" SG_ 353 L_ATCU_HU_FrPsEVntCtrOpnCls 7;
BA_REL_ "GenSigTimeoutTime" BU_SG_REL_ L_EVNT SG_ 353 L_ATCU_HU_FrPsEVntCtrOpnCls 0;
BA_ "Version" SG_ 353 L_ATCU_HU_FrPsEVntCtrOpnCls "24.05.11";
BA_ "Description" SG_ 353 L_ATCU_HU_FrPsEVntModeSet "Electric Vent Frt Passenger Mode Signal";
BA_ "GenSigSendType" SG_ 353 L_ATCU_HU_FrPsEVntModeSet 4;
BA_ "UserSigValidity" SG_ 353 L_ATCU_HU_FrPsEVntModeSet 7;
BA_REL_ "GenSigTimeoutTime" BU_SG_REL_ L_EVNT SG_ 353 L_ATCU_HU_FrPsEVntModeSet 0;
BA_ "Version" SG_ 353 L_ATCU_HU_FrPsEVntModeSet "24.08.00";
BA_ "Description" SG_ 353 L_ATCU_HU_FrDrEVntSideOpnCls "Electric Vent Frt Driver Side Vent Open/Close Signal";
BA_ "GenSigSendType" SG_ 353 L_ATCU_HU_FrDrEVntSideOpnCls 4;
BA_ "UserSigValidity" SG_ 353 L_ATCU_HU_FrDrEVntSideOpnCls 7;
BA_REL_ "GenSigTimeoutTime" BU_SG_REL_ L_EVNT SG_ 353 L_ATCU_HU_FrDrEVntSideOpnCls 0;
BA_ "Version" SG_ 353 L_ATCU_HU_FrDrEVntSideOpnCls "24.05.11";
BA_ "GenMsgCycleTime" BO_ 354 0;
BA_ "Description" SG_ 354 L_ATCU_CTS_FrtDrEVntModeSet "Electric Vent Mode_Frt Dr";
BA_ "GenSigSendType" SG_ 354 L_ATCU_CTS_FrtDrEVntModeSet 4;
BA_ "UserSigValidity" SG_ 354 L_ATCU_CTS_FrtDrEVntModeSet 7;
BA_REL_ "GenSigTimeoutTime" BU_SG_REL_ L_EVNT SG_ 354 L_ATCU_CTS_FrtDrEVntModeSet 0;
BA_ "Version" SG_ 354 L_ATCU_CTS_FrtDrEVntModeSet "24.08.00";
BA_ "Description" SG_ 354 L_ATCU_CTS_FrDrEVntCtrOpnCls "Electric Vent FRT Dr Center Vent Open/Close Signal";
BA_ "GenSigSendType" SG_ 354 L_ATCU_CTS_FrDrEVntCtrOpnCls 4;
BA_ "UserSigValidity" SG_ 354 L_ATCU_CTS_FrDrEVntCtrOpnCls 7;
BA_REL_ "GenSigTimeoutTime" BU_SG_REL_ L_EVNT SG_ 354 L_ATCU_CTS_FrDrEVntCtrOpnCls 0;
BA_ "Version" SG_ 354 L_ATCU_CTS_FrDrEVntCtrOpnCls "24.08.00";
BA_ "Description" SG_ 354 L_ATCU_CTS_FrPsEVntSideOpnCls "Electric Vent FRT Ps Side Vent Open/Close Signal";
BA_ "GenSigSendType" SG_ 354 L_ATCU_CTS_FrPsEVntSideOpnCls 4;
BA_ "UserSigValidity" SG_ 354 L_ATCU_CTS_FrPsEVntSideOpnCls 7;
BA_REL_ "GenSigTimeoutTime" BU_SG_REL_ L_EVNT SG_ 354 L_ATCU_CTS_FrPsEVntSideOpnCls 0;
BA_ "Version" SG_ 354 L_ATCU_CTS_FrPsEVntSideOpnCls "24.08.00";
BA_ "Description" SG_ 354 L_ATCU_CTS_FrPsEVntCtrOpnCls "Electric Vent FRT Ps Center Vent Open/Close Signal";
BA_ "GenSigSendType" SG_ 354 L_ATCU_CTS_FrPsEVntCtrOpnCls 4;
BA_ "UserSigValidity" SG_ 354 L_ATCU_CTS_FrPsEVntCtrOpnCls 7;
BA_REL_ "GenSigTimeoutTime" BU_SG_REL_ L_EVNT SG_ 354 L_ATCU_CTS_FrPsEVntCtrOpnCls 0;
BA_ "Version" SG_ 354 L_ATCU_CTS_FrPsEVntCtrOpnCls "24.08.00";
BA_ "Description" SG_ 354 L_ATCU_CTS_FrtPsEVntModeSet "Electric Vent Mode_Frt Ps";
BA_ "GenSigSendType" SG_ 354 L_ATCU_CTS_FrtPsEVntModeSet 4;
BA_ "UserSigValidity" SG_ 354 L_ATCU_CTS_FrtPsEVntModeSet 7;
BA_REL_ "GenSigTimeoutTime" BU_SG_REL_ L_EVNT SG_ 354 L_ATCU_CTS_FrtPsEVntModeSet 0;
BA_ "Version" SG_ 354 L_ATCU_CTS_FrtPsEVntModeSet "24.08.00";
BA_ "Description" SG_ 354 L_ATCU_CTS_FrDrEVntSideOpnCls "Electric Vent FRT Dr Side Vent Open/Close Signal";
BA_ "GenSigSendType" SG_ 354 L_ATCU_CTS_FrDrEVntSideOpnCls 4;
BA_ "UserSigValidity" SG_ 354 L_ATCU_CTS_FrDrEVntSideOpnCls 7;
BA_REL_ "GenSigTimeoutTime" BU_SG_REL_ L_EVNT SG_ 354 L_ATCU_CTS_FrDrEVntSideOpnCls 0;
BA_ "Version" SG_ 354 L_ATCU_CTS_FrDrEVntSideOpnCls "24.08.00";
VAL_ 36 L_ATCU_ArClnIntroEvt 0 "OFF" 1 "ON" ;
VAL_ 36 L_ATCU_ArClnSmblClr 0 "Default (Initial Value)" 1 "Mono Color" 2 "Blue Color" 3 "Green Color" 4 "Orange Color" 5 "Red Color" 6 "Yellow Color" 7 "RESERVED" 8 "RESERVED" 9 "RESERVED" 10 "RESERVED" 11 "RESERVED" 12 "RESERVED" 13 "RESERVED" 14 "Gray Color (Deactivate)" 15 "Invalid" ;
VAL_ 36 L_ATCU_DustLevelDis 0 "Sensor Fail" 1 "Good" 2 "Normal" 3 "Bad" 4 "Very Bad" 5 "RESERVED" 6 "Loading(Init or StandBy)" 7 "Error Indicator" ;
VAL_ 36 L_ATCU_DustBarDisOff 0 "False(Symbol ON)" 1 "True(Symbol OFF)" ;
VAL_ 36 L_ATCU_DustSnrStepDis 0 "default" 1 "0step" 2 "1step" 3 "2step" 4 "3step" 5 "4step" 6 "5step" 7 "6step" 8 "7step" 9 "8step" 10 "9step" 11 "10step" 12 "11step" 13 "12step" 14 "13step" 15 "14step" 16 "15step" 17 "16step" ;
VAL_ 36 L_ATCU_FragStrhDis 0 "OFF" 1 "1st(Low)" 2 "1st&2nd(Mid)" 3 "1st&2nd&3rd(High)" ;
VAL_ 36 L_ATCU_FragKindDis 0 "Default" 1 "First" 2 "Second" 3 "RESERVED" 4 "RESERVED" 5 "RESERVED" 6 "None" 7 "Error Indicator" ;
VAL_ 36 L_ATCU_Frag1Inform 0 "Default" 1 "THE DRIVER'S AWAKENING" 2 "MY FAVORITE PLACE" 3 "THE GREAT OUTDOORS" 4 "RESERVED" 5 "RESERVED" 6 "RESERVED" 7 "RESERVED" 8 "RESERVED" 9 "RESERVED" 10 "RESERVED" 11 "RESERVED" 12 "New Fragrance Mounted" 13 "No Cartridge Mounted" 14 "Unknown Cartridge Monuted" 15 "Error Indicator" ;
VAL_ 36 L_ATCU_Frag2Inform 0 "Default" 1 "THE DRIVER'S AWAKENING" 2 "MY FAVORITE PLACE" 3 "THE GREAT OUTDOORS" 4 "RESERVED" 5 "RESERVED" 6 "RESERVED" 7 "RESERVED" 8 "RESERVED" 9 "RESERVED" 10 "RESERVED" 11 "RESERVED" 12 "New Fragrance Mounted" 13 "No Cartridge Mounted" 14 "Unknown Cartridge Monuted" 15 "Error Indicator" ;
VAL_ 36 L_ATCU_Frag1RemainDisp 0 "Default" 1 "Remains 100% (70~100%)" 2 "Remains 70% (30~70%)" 3 "Remains 30% (0~30%)" 4 "Remains 0%" 5 "RESERVED" 6 "Unknown" 7 "Error Indicator" ;
VAL_ 36 L_ATCU_Frag2RemainDisp 0 "Default" 1 "Remains 100% (70~100%)" 2 "Remains 70% (30~70%)" 3 "Remains 30% (0~30%)" 4 "Remains 0%" 5 "RESERVED" 6 "Unknown" 7 "Error Indicator" ;
VAL_ 36 L_ATCU_ArClnSmblTyp 0 "Default" 1 "BLANK DISPLAY" 2 "Tree Only" 3 "Tree & Fixed Arrow" 4 "Tree & Rotating Arrow" ;
VAL_ 36 L_ATCU_FrtBlwMaxLvlVaild 0 "Invalid (Multi AUTO Not Applied)" 1 "Reversed" 2 "1 Level" 3 "2 Level" 4 "3 Level" 5 "4 Level" 6 "5 Level" 7 "6 Level" 8 "7 Level" 9 "8 Level" 10 "Not used" 11 "Not used" 12 "Not used" 13 "Not used" 14 "Not used" 15 "Error Indicator" ;
VAL_ 36 L_ATCU_OpSta 0 "DATC Off (Power Down)" 1 "DATC Normal" 2 "DATC System Off (Blower Off)" 3 "DATC Self Diagnosis" 4 "Version Display" 5 "Not used" 6 "Not used" 7 "Error Indicator" ;
VAL_ 36 L_ATCU_TempDispUnit 0 "Centigrade(¡É)" 1 "Fahrenheit(¢µ)" 2 "Not used" 3 "Error Indicator" ;
VAL_ 36 L_ATCU_DrvAUTOStep 0 "Default" 1 "OFF" 2 "1st & 2nd & 3rd On (3 Step Type)" 3 "1st & 2nd On (3 Step Type)" 4 "1st On (3 Step Type)" 5 "1st & 2nd On (2 Step Type)" 6 "1st On (2 Step Type)" 7 "RESERVED" 8 "RESERVED" 9 "RESERVED" 10 "RESERVED" 11 "RESERVED" 12 "RESERVED" 13 "RESERVED" 14 "RESERVED" 15 "Error Indicator" ;
VAL_ 36 L_ATCU_DiagCodeDis 0 "Blank Display" 1023 "Error Indicator" ;
VAL_ 37 L_ATCU_RrOpSta 0 "DATC Off (Power Down)" 1 "DATC Normal" 2 "DATC System Off (Blower Off)" 3 "DATC Self Diagnosis" 4 "Not used" 5 "Not used" 6 "Not used" 7 "Error Indicator" ;
VAL_ 37 L_ATCU_RrDrvTempFDis 0 "Blank Display (Default)" 1 "'LO' Display" 2 "58¢µ~92¢µ" 3 "58¢µ~92¢µ" 4 "58¢µ~92¢µ" 5 "58¢µ~92¢µ" 6 "58¢µ~92¢µ" 7 "58¢µ~92¢µ" 8 "58¢µ~92¢µ" 9 "58¢µ~92¢µ" 10 "58¢µ~92¢µ" 11 "58¢µ~92¢µ" 12 "58¢µ~92¢µ" 13 "58¢µ~92¢µ" 14 "58¢µ~92¢µ" 15 "58¢µ~92¢µ" 16 "58¢µ~92¢µ" 17 "58¢µ~92¢µ" 18 "58¢µ~92¢µ" 19 "58¢µ~92¢µ" 20 "58¢µ~92¢µ" 21 "58¢µ~92¢µ" 22 "58¢µ~92¢µ" 23 "58¢µ~92¢µ" 24 "58¢µ~92¢µ" 25 "58¢µ~92¢µ" 26 "58¢µ~92¢µ" 27 "58¢µ~92¢µ" 28 "58¢µ~92¢µ" 29 "58¢µ~92¢µ" 30 "58¢µ~92¢µ" 31 "58¢µ~92¢µ" 32 "58¢µ~92¢µ" 33 "58¢µ~92¢µ" 34 "58¢µ~92¢µ" 35 "58¢µ~92¢µ" 36 "58¢µ~92¢µ" 37 "0x25~0xFD:RESERVED" 253 "0x25~0xFD:RESERVED" 254 "'HI' Display" 255 "Error Indicator" ;
VAL_ 37 L_ATCU_RrDrvModDis 0 "Off(Blank Display, Vent mode not Display ex) Auto" 1 "VENT" 2 "B_L" 3 "FLOOR" 4 "MIX" 5 "DEF(Including Max DEF)" 6 "AUTO DEFOG" 7 "Def (7 mode only)" 8 "DefVent(7 mode only)" 9 "DefFL(7 mode only)" 10 "VentFL(7 mode only)" 11 "DefVentFL(7 mode only)" 12 "Not used" 13 "Not used" 14 "Not used" 15 "Error Indicator" ;
VAL_ 37 L_ATCU_RrDrvBlwDis 0 "OFF(System Off)" 1 "Blank Display(Blower Level no display, ex)Auto mode)" 2 "1 Level" 3 "2 Level" 4 "3 Level" 5 "4 Level" 6 "5 Level" 7 "6 Level" 8 "7 Level" 9 "8 Level" 10 "Not used" 11 "Not used" 12 "Not used" 13 "Not used" 14 "Not used" 15 "Error Indicator" ;
VAL_ 37 L_ATCU_RrDrvAutoDis 0 "RrAUTO Off" 1 "RrAUTO On" 2 "Not used" 3 "Error Indicator" ;
VAL_ 37 L_ATCU_RrDrvMultiAutoBlwDis 0 "MultiAutoBlr Display Off" 1 "Multi Auto Blower Low" 2 "Multi Auto Blower Mid" 3 "Multi Auto Blower High" ;
VAL_ 37 L_ATCU_RrDrvTempCDis 0 "Blank Display (Default)" 1 "'LO' Display" 2 "15.0¡É~32.0¡É" 3 "15.0¡É~32.0¡É" 4 "15.0¡É~32.0¡É" 5 "15.0¡É~32.0¡É" 6 "15.0¡É~32.0¡É" 7 "15.0¡É~32.0¡É" 8 "15.0¡É~32.0¡É" 9 "15.0¡É~32.0¡É" 10 "15.0¡É~32.0¡É" 11 "15.0¡É~32.0¡É" 12 "15.0¡É~32.0¡É" 13 "15.0¡É~32.0¡É" 14 "15.0¡É~32.0¡É" 15 "15.0¡É~32.0¡É" 16 "15.0¡É~32.0¡É" 17 "15.0¡É~32.0¡É" 18 "15.0¡É~32.0¡É" 19 "15.0¡É~32.0¡É" 20 "15.0¡É~32.0¡É" 21 "15.0¡É~32.0¡É" 22 "15.0¡É~32.0¡É" 23 "15.0¡É~32.0¡É" 24 "15.0¡É~32.0¡É" 25 "15.0¡É~32.0¡É" 26 "15.0¡É~32.0¡É" 27 "15.0¡É~32.0¡É" 28 "15.0¡É~32.0¡É" 29 "15.0¡É~32.0¡É" 30 "15.0¡É~32.0¡É" 31 "15.0¡É~32.0¡É" 32 "15.0¡É~32.0¡É" 33 "15.0¡É~32.0¡É" 34 "15.0¡É~32.0¡É" 35 "15.0¡É~32.0¡É" 36 "15.0¡É~32.0¡É" 37 "0x25~0xFD:RESERVED" 253 "0x25~0xFD:RESERVED" 254 "'HI' Display" 255 "Error Indicator" ;
VAL_ 37 L_ATCU_RrSyncDis 0 "RrSYNC Off" 1 "RrSYNC On" 2 "Not used" 3 "Error Indicator" ;
VAL_ 37 L_ATCU_RrLcdBckLightSta 0 "OFF" 1 "ON" ;
VAL_ 37 L_ATCU_RrGUIBlankDis 0 "OFF" 1 "ON" ;
VAL_ 37 L_ATCU_RLStHeatSwHInd 0 "OFF" 1 "ON" ;
VAL_ 37 L_ATCU_RLStHeatSwMInd 0 "OFF" 1 "ON" ;
VAL_ 37 L_ATCU_RLStHeatSwLInd 0 "OFF" 1 "ON" ;
VAL_ 37 L_ATCU_RLStVntSwHInd 0 "OFF" 1 "ON" ;
VAL_ 37 L_ATCU_RLStVntSwMInd 0 "OFF" 1 "ON" ;
VAL_ 37 L_ATCU_RLStVntSwLInd 0 "OFF" 1 "ON" ;
VAL_ 37 L_ATCU_RRStHeatSwHInd 0 "OFF" 1 "ON" ;
VAL_ 37 L_ATCU_RRStHeatSwMInd 0 "OFF" 1 "ON" ;
VAL_ 37 L_ATCU_RRStHeatSwLInd 0 "OFF" 1 "ON" ;
VAL_ 37 L_ATCU_RRStVntSwHInd 0 "OFF" 1 "ON" ;
VAL_ 37 L_ATCU_RRStVntSwMInd 0 "OFF" 1 "ON" ;
VAL_ 37 L_ATCU_RRStVntSwLInd 0 "OFF" 1 "ON" ;
VAL_ 37 L_ATCU_RrMTCOpSta 0 "DATC Off (Power Down)" 1 "DATC Normal" 2 "DATC System Off (Blower Off)" 3 "Error Indicator" ;
VAL_ 37 L_ATCU_RrMTCTempLvl 0 "Off" 1 "Level 1" 2 "Level 2" 3 "Level 3" 4 "Level 4" 5 "Level 5" 6 "Level 6" 7 "Level 7" 8 "Level 8" ;
VAL_ 37 L_ATCU_RrPsModDis 0 "Off(Blank Display, Vent mode not Display ex) Auto" 1 "VENT" 2 "B_L" 3 "FLOOR" 4 "MIX" 5 "DEF(Including Max DEF)" 6 "AUTO DEFOG" 7 "Def (7 mode only)" 8 "DefVent(7 mode only)" 9 "DefFL(7 mode only)" 10 "VentFL(7 mode only)" 11 "DefVentFL(7 mode only)" 12 "Not used" 13 "Not used" 14 "Not used" 15 "Error Indicator" ;
VAL_ 37 L_ATCU_RrLockDis 0 "RearLock Off" 1 "RearLock On" 2 "Not Used" 3 "Error Indicator" ;
VAL_ 37 L_ATCU_RrDrvAutoStep 0 "Default" 1 "OFF" 2 "1st & 2nd & 3rd On (3 Step Type)" 3 "1st & 2nd On (3 Step Type)" 4 "1st On (3 Step Type)" 5 "1st & 2nd On (2 Step Type)" 6 "1st On (2 Step Type)" 7 "RESERVED" 8 "RESERVED" 9 "RESERVED" 10 "RESERVED" 11 "RESERVED" 12 "RESERVED" 13 "RESERVED" 14 "RESERVED" 15 "Error Indicator" ;
VAL_ 40 L_ATCU_PassAUTOStep 0 "Default" 1 "OFF" 2 "1st & 2nd & 3rd On (3 Step Type)" 3 "1st & 2nd On (3 Step Type)" 4 "1st On (3 Step Type)" 5 "1st & 2nd On (2 Step Type)" 6 "1st On (2 Step Type)" 7 "Error Indicator" ;
VAL_ 40 L_ATCU_RrPassTempFDis 0 "Blank Display(Default)" 1 "'LO' Display" 2 "58¢µ~32¢µ" 3 "58¢µ~32¢µ" 4 "58¢µ~32¢µ" 5 "58¢µ~32¢µ" 6 "58¢µ~32¢µ" 7 "58¢µ~32¢µ" 8 "58¢µ~32¢µ" 9 "58¢µ~32¢µ" 10 "58¢µ~32¢µ" 11 "58¢µ~32¢µ" 12 "58¢µ~32¢µ" 13 "58¢µ~32¢µ" 14 "58¢µ~32¢µ" 15 "58¢µ~32¢µ" 16 "58¢µ~32¢µ" 17 "58¢µ~32¢µ" 18 "58¢µ~32¢µ" 19 "58¢µ~32¢µ" 20 "58¢µ~32¢µ" 21 "58¢µ~32¢µ" 22 "58¢µ~32¢µ" 23 "58¢µ~32¢µ" 24 "58¢µ~32¢µ" 25 "58¢µ~32¢µ" 26 "58¢µ~32¢µ" 27 "58¢µ~32¢µ" 28 "58¢µ~32¢µ" 29 "58¢µ~32¢µ" 30 "58¢µ~32¢µ" 31 "58¢µ~32¢µ" 32 "58¢µ~32¢µ" 33 "58¢µ~32¢µ" 34 "58¢µ~32¢µ" 35 "58¢µ~32¢µ" 36 "58¢µ~32¢µ" 37 "0x25~0xFD:RESERVED" 253 "0x25~0xFD:RESERVED" 254 "'HI' Display" 255 "Error Indicator" ;
VAL_ 40 L_ATCU_RrPassBlwDis 0 "OFF(Default)" 1 "Blank Display(Blower level not display, ex)Auto mode)" 2 "1 Step" 3 "2 Step" 4 "3 Step" 5 "4 Step" 6 "5 Step" 7 "6 Step" 8 "7 Step" 9 "8 Step" 10 "BLOWER AUTO" 11 "RESERVED" 12 "RESERVED" 13 "RESERVED" 14 "RESERVED" 15 "Error Indicator" ;
VAL_ 40 L_ATCU_RrPassAUTODis 0 "PsAUTO Off" 1 "PsAUTO On" 2 "Not used" 3 "Error Indicator" ;
VAL_ 40 L_ATCU_RrPassAUTOStep 0 "Default" 1 "OFF" 2 "1st & 2nd & 3rd On (3 Step Type)" 3 "1st & 2nd On (3 Step Type)" 4 "1st On (3 Step Type)" 5 "1st & 2nd On (2 Step Type)" 6 "1st On (2 Step Type)" 7 "Error Indicator" ;
VAL_ 40 L_ATCU_CampModeSta 0 "Default" 1 "Off" 2 "On" 3 "Invalid" ;
VAL_ 40 L_ATCU_RrPassTempCDis 0 "Blank Display(Default)" 1 "'LO' Display" 2 "15.0¡É~32.0¡É" 3 "15.0¡É~32.0¡É" 4 "15.0¡É~32.0¡É" 5 "15.0¡É~32.0¡É" 6 "15.0¡É~32.0¡É" 7 "15.0¡É~32.0¡É" 8 "15.0¡É~32.0¡É" 9 "15.0¡É~32.0¡É" 10 "15.0¡É~32.0¡É" 11 "15.0¡É~32.0¡É" 12 "15.0¡É~32.0¡É" 13 "15.0¡É~32.0¡É" 14 "15.0¡É~32.0¡É" 15 "15.0¡É~32.0¡É" 16 "15.0¡É~32.0¡É" 17 "15.0¡É~32.0¡É" 18 "15.0¡É~32.0¡É" 19 "15.0¡É~32.0¡É" 20 "15.0¡É~32.0¡É" 21 "15.0¡É~32.0¡É" 22 "15.0¡É~32.0¡É" 23 "15.0¡É~32.0¡É" 24 "15.0¡É~32.0¡É" 25 "15.0¡É~32.0¡É" 26 "15.0¡É~32.0¡É" 27 "15.0¡É~32.0¡É" 28 "15.0¡É~32.0¡É" 29 "15.0¡É~32.0¡É" 30 "15.0¡É~32.0¡É" 31 "15.0¡É~32.0¡É" 32 "15.0¡É~32.0¡É" 33 "15.0¡É~32.0¡É" 34 "15.0¡É~32.0¡É" 35 "15.0¡É~32.0¡É" 36 "15.0¡É~32.0¡É" 37 "0x25~0xFD:RESERVED" 253 "0x25~0xFD:RESERVED" 254 "'HI' Display" 255 "Error Indicator" ;
VAL_ 40 L_ATCU_UtilModeUsmSta 0 "Disable" 1 "Rest Mode Off" 2 "Rest Mode On" 3 "Invalid" ;
VAL_ 40 L_ATCU_RrAcDis 0 "AC OFF" 1 "AC ON" 2 "Not used" 3 "Error Indicator" ;
VAL_ 40 L_ATCU_3rdAcDis 0 "AC Off" 1 "AC ON" 2 "Not used" 3 "Error Indicator" ;
VAL_ 41 L_ATCU_OutTempDispC 0 "Default" 1 "Not Used" 2 "0x02~0xCA:-40¡É~60¡É" 202 "0x02~0xCA:-40¡É~60¡É" 203 "RESERVED" 204 "RESERVED" 205 "RESERVED" 206 "RESERVED" 207 "RESERVED" 208 "RESERVED" 209 "RESERVED" 210 "RESERVED" 211 "RESERVED" 212 "RESERVED" 213 "RESERVED" 214 "RESERVED" 215 "RESERVED" 216 "RESERVED" 217 "RESERVED" 218 "RESERVED" 219 "RESERVED" 220 "RESERVED" 221 "RESERVED" 222 "RESERVED" 223 "RESERVED" 224 "RESERVED" 225 "RESERVED" 226 "RESERVED" 227 "RESERVED" 228 "RESERVED" 229 "RESERVED" 230 "RESERVED" 231 "RESERVED" 232 "RESERVED" 233 "RESERVED" 234 "RESERVED" 235 "RESERVED" 236 "RESERVED" 237 "RESERVED" 238 "RESERVED" 239 "RESERVED" 240 "RESERVED" 241 "RESERVED" 242 "RESERVED" 243 "RESERVED" 244 "RESERVED" 245 "RESERVED" 246 "RESERVED" 247 "RESERVED" 248 "RESERVED" 249 "RESERVED" 250 "RESERVED" 251 "RESERVED" 252 "RESERVED" 253 "RESERVED" 254 "Sensor Fail (--Display)" 255 "Invalid" ;
VAL_ 41 L_ATCU_DtntOutSta 0 "Detent Off" 1 "Detent On" ;
VAL_ 41 L_ATCU_AutoBrightSta 0 "RESERVED" 1 "0x01~0xC8:Bright State (1~200 Step)" 200 "0x01~0xC8:Bright State (1~200 Step)" 201 "RESERVED" 202 "RESERVED" 203 "RESERVED" 204 "RESERVED" 205 "RESERVED" 206 "RESERVED" 207 "RESERVED" 208 "RESERVED" 209 "RESERVED" 210 "RESERVED" 211 "RESERVED" 212 "RESERVED" 213 "RESERVED" 214 "RESERVED" 215 "RESERVED" 216 "RESERVED" 217 "RESERVED" 218 "RESERVED" 219 "RESERVED" 220 "RESERVED" 221 "RESERVED" 222 "RESERVED" 223 "RESERVED" 224 "RESERVED" 225 "RESERVED" 226 "RESERVED" 227 "RESERVED" 228 "RESERVED" 229 "RESERVED" 230 "RESERVED" 231 "RESERVED" 232 "RESERVED" 233 "RESERVED" 234 "RESERVED" 235 "RESERVED" 236 "RESERVED" 237 "RESERVED" 238 "RESERVED" 239 "RESERVED" 240 "RESERVED" 241 "RESERVED" 242 "RESERVED" 243 "RESERVED" 244 "RESERVED" 245 "RESERVED" 246 "RESERVED" 247 "RESERVED" 248 "RESERVED" 249 "RESERVED" 250 "RESERVED" 251 "RESERVED" 252 "RESERVED" 253 "RESERVED" 254 "RESERVED" 255 "RESERVED" ;
VAL_ 41 L_ATCU_DustSnrVal 1021 "Standby" 1022 "Init" 1023 "RESERVED" ;
VAL_ 41 L_ATCU_NotMinModeBrightSta 0 "RESERVED (Not Used)" 1 "0x01~0xC8:Bright State(1~200 Step)" 200 "0x01~0xC8:Bright State(1~200 Step)" ;
VAL_ 41 L_ATCU_IAUPrfleVal 0 "Default" 1 "Guest" 2 "Profile 1" 3 "Profile 2" 4 "Profile 3" 5 "Profile 4" 6 "Profile 5" 7 "Proflie 6" 8 "Profile 7" 9 "Profile 8" 10 "Profile 9" 11 "RESERVED" 12 "RESERVED" 13 "RESERVED" 14 "RESERVED" 15 "Invalid" ;
VAL_ 41 L_ATCU_AVNPrfleVal 0 "Default" 1 "Guest" 2 "Profile 1" 3 "Profile 2" 4 "Profile 3" 5 "Profile 4" 6 "Profile 5" 7 "Profile 6" 8 "Profile 7" 9 "Profile 8" 10 "Profile 9" 11 "RESERVED" 12 "RESERVED" 13 "RESERVED" 14 "RESERVED" 15 "Invalid" ;
VAL_ 41 L_ATCU_SchdldClimateSta 0 "Default" 1 "Deactivated" 2 "Activated" 3 "Invalid" ;
VAL_ 41 L_ATCU_OutTempDispF 0 "Default" 1 "Not Used" 2 "0x02~0xCA:-40¢µ~160¢µ" 202 "0x02~0xCA:-40¢µ~160¢µ" 203 "RESERVED" 204 "RESERVED" 205 "RESERVED" 206 "RESERVED" 207 "RESERVED" 208 "RESERVED" 209 "RESERVED" 210 "RESERVED" 211 "RESERVED" 212 "RESERVED" 213 "RESERVED" 214 "RESERVED" 215 "RESERVED" 216 "RESERVED" 217 "RESERVED" 218 "RESERVED" 219 "RESERVED" 220 "RESERVED" 221 "RESERVED" 222 "RESERVED" 223 "RESERVED" 224 "RESERVED" 225 "RESERVED" 226 "RESERVED" 227 "RESERVED" 228 "RESERVED" 229 "RESERVED" 230 "RESERVED" 231 "RESERVED" 232 "RESERVED" 233 "RESERVED" 234 "RESERVED" 235 "RESERVED" 236 "RESERVED" 237 "RESERVED" 238 "RESERVED" 239 "RESERVED" 240 "RESERVED" 241 "RESERVED" 242 "RESERVED" 243 "RESERVED" 244 "RESERVED" 245 "RESERVED" 246 "RESERVED" 247 "RESERVED" 248 "RESERVED" 249 "RESERVED" 250 "RESERVED" 251 "RESERVED" 252 "RESERVED" 253 "RESERVED" 254 "Sensor Fail (--Display)" 255 "Invalid" ;
VAL_ 49 L_ATCU_ResetPreWrngForOthers 0 "No Warning" 1 "Warning" 2 "RESERVED" 3 "Invalid" ;
VAL_ 49 L_ATCU_ResetReqForOthers 0 "No Request" 1 "Reset Request" 2 "RESERVED" 3 "Invalid" ;
VAL_ 290 L_ATCU_HU_FrDrEVntSideBdryUp_X 0 "Default" 1 "0x01~0xC0:PHY=HEX*10 + 0" 192 "0x01~0xC0:PHY=HEX*10 + 0" 193 "RESERVED" 194 "RESERVED" 195 "RESERVED" 196 "RESERVED" 197 "RESERVED" 198 "RESERVED" 199 "RESERVED" 200 "RESERVED" 201 "RESERVED" 202 "RESERVED" 203 "RESERVED" 204 "RESERVED" 205 "RESERVED" 206 "RESERVED" 207 "RESERVED" 208 "RESERVED" 209 "RESERVED" 210 "RESERVED" 211 "RESERVED" 212 "RESERVED" 213 "RESERVED" 214 "RESERVED" 215 "RESERVED" 216 "RESERVED" 217 "RESERVED" 218 "RESERVED" 219 "RESERVED" 220 "RESERVED" 221 "RESERVED" 222 "RESERVED" 223 "RESERVED" 224 "RESERVED" 225 "RESERVED" 226 "RESERVED" 227 "RESERVED" 228 "RESERVED" 229 "RESERVED" 230 "RESERVED" 231 "RESERVED" 232 "RESERVED" 233 "RESERVED" 234 "RESERVED" 235 "RESERVED" 236 "RESERVED" 237 "RESERVED" 238 "RESERVED" 239 "RESERVED" 240 "RESERVED" 241 "RESERVED" 242 "RESERVED" 243 "RESERVED" 244 "RESERVED" 245 "RESERVED" 246 "RESERVED" 247 "RESERVED" 248 "RESERVED" 249 "RESERVED" 250 "RESERVED" 251 "RESERVED" 252 "RESERVED" 253 "RESERVED" 254 "RESERVED" 255 "Invalid" ;
VAL_ 290 L_ATCU_HU_FrDrEVntSideBdryLo_X 0 "Default" 1 "0x01~0xC0:PHY=HEX*10 + 0" 192 "0x01~0xC0:PHY=HEX*10 + 0" 193 "RESERVED" 194 "RESERVED" 195 "RESERVED" 196 "RESERVED" 197 "RESERVED" 198 "RESERVED" 199 "RESERVED" 200 "RESERVED" 201 "RESERVED" 202 "RESERVED" 203 "RESERVED" 204 "RESERVED" 205 "RESERVED" 206 "RESERVED" 207 "RESERVED" 208 "RESERVED" 209 "RESERVED" 210 "RESERVED" 211 "RESERVED" 212 "RESERVED" 213 "RESERVED" 214 "RESERVED" 215 "RESERVED" 216 "RESERVED" 217 "RESERVED" 218 "RESERVED" 219 "RESERVED" 220 "RESERVED" 221 "RESERVED" 222 "RESERVED" 223 "RESERVED" 224 "RESERVED" 225 "RESERVED" 226 "RESERVED" 227 "RESERVED" 228 "RESERVED" 229 "RESERVED" 230 "RESERVED" 231 "RESERVED" 232 "RESERVED" 233 "RESERVED" 234 "RESERVED" 235 "RESERVED" 236 "RESERVED" 237 "RESERVED" 238 "RESERVED" 239 "RESERVED" 240 "RESERVED" 241 "RESERVED" 242 "RESERVED" 243 "RESERVED" 244 "RESERVED" 245 "RESERVED" 246 "RESERVED" 247 "RESERVED" 248 "RESERVED" 249 "RESERVED" 250 "RESERVED" 251 "RESERVED" 252 "RESERVED" 253 "RESERVED" 254 "RESERVED" 255 "Invalid" ;
VAL_ 290 L_ATCU_HU_FrDrEVntSideBdryLo_Y 0 "Default" 1 "0x01~0xC0:PHY=HEX*10 + 0" 192 "0x01~0xC0:PHY=HEX*10 + 0" 193 "RESERVED" 194 "RESERVED" 195 "RESERVED" 196 "RESERVED" 197 "RESERVED" 198 "RESERVED" 199 "RESERVED" 200 "RESERVED" 201 "RESERVED" 202 "RESERVED" 203 "RESERVED" 204 "RESERVED" 205 "RESERVED" 206 "RESERVED" 207 "RESERVED" 208 "RESERVED" 209 "RESERVED" 210 "RESERVED" 211 "RESERVED" 212 "RESERVED" 213 "RESERVED" 214 "RESERVED" 215 "RESERVED" 216 "RESERVED" 217 "RESERVED" 218 "RESERVED" 219 "RESERVED" 220 "RESERVED" 221 "RESERVED" 222 "RESERVED" 223 "RESERVED" 224 "RESERVED" 225 "RESERVED" 226 "RESERVED" 227 "RESERVED" 228 "RESERVED" 229 "RESERVED" 230 "RESERVED" 231 "RESERVED" 232 "RESERVED" 233 "RESERVED" 234 "RESERVED" 235 "RESERVED" 236 "RESERVED" 237 "RESERVED" 238 "RESERVED" 239 "RESERVED" 240 "RESERVED" 241 "RESERVED" 242 "RESERVED" 243 "RESERVED" 244 "RESERVED" 245 "RESERVED" 246 "RESERVED" 247 "RESERVED" 248 "RESERVED" 249 "RESERVED" 250 "RESERVED" 251 "RESERVED" 252 "RESERVED" 253 "RESERVED" 254 "RESERVED" 255 "Invalid" ;
VAL_ 290 L_ATCU_HU_FrDrEVntCtrBdryUp_X 0 "Default" 1 "0x01~0xC0:PHY=HEX*10 + 0" 192 "0x01~0xC0:PHY=HEX*10 + 0" 193 "RESERVED" 194 "RESERVED" 195 "RESERVED" 196 "RESERVED" 197 "RESERVED" 198 "RESERVED" 199 "RESERVED" 200 "RESERVED" 201 "RESERVED" 202 "RESERVED" 203 "RESERVED" 204 "RESERVED" 205 "RESERVED" 206 "RESERVED" 207 "RESERVED" 208 "RESERVED" 209 "RESERVED" 210 "RESERVED" 211 "RESERVED" 212 "RESERVED" 213 "RESERVED" 214 "RESERVED" 215 "RESERVED" 216 "RESERVED" 217 "RESERVED" 218 "RESERVED" 219 "RESERVED" 220 "RESERVED" 221 "RESERVED" 222 "RESERVED" 223 "RESERVED" 224 "RESERVED" 225 "RESERVED" 226 "RESERVED" 227 "RESERVED" 228 "RESERVED" 229 "RESERVED" 230 "RESERVED" 231 "RESERVED" 232 "RESERVED" 233 "RESERVED" 234 "RESERVED" 235 "RESERVED" 236 "RESERVED" 237 "RESERVED" 238 "RESERVED" 239 "RESERVED" 240 "RESERVED" 241 "RESERVED" 242 "RESERVED" 243 "RESERVED" 244 "RESERVED" 245 "RESERVED" 246 "RESERVED" 247 "RESERVED" 248 "RESERVED" 249 "RESERVED" 250 "RESERVED" 251 "RESERVED" 252 "RESERVED" 253 "RESERVED" 254 "RESERVED" 255 "Invalid" ;
VAL_ 290 L_ATCU_HU_FrDrEVntCtrBdryUp_Y 0 "Default" 1 "0x01~0xC0:PHY=HEX*10 + 0" 192 "0x01~0xC0:PHY=HEX*10 + 0" 193 "RESERVED" 194 "RESERVED" 195 "RESERVED" 196 "RESERVED" 197 "RESERVED" 198 "RESERVED" 199 "RESERVED" 200 "RESERVED" 201 "RESERVED" 202 "RESERVED" 203 "RESERVED" 204 "RESERVED" 205 "RESERVED" 206 "RESERVED" 207 "RESERVED" 208 "RESERVED" 209 "RESERVED" 210 "RESERVED" 211 "RESERVED" 212 "RESERVED" 213 "RESERVED" 214 "RESERVED" 215 "RESERVED" 216 "RESERVED" 217 "RESERVED" 218 "RESERVED" 219 "RESERVED" 220 "RESERVED" 221 "RESERVED" 222 "RESERVED" 223 "RESERVED" 224 "RESERVED" 225 "RESERVED" 226 "RESERVED" 227 "RESERVED" 228 "RESERVED" 229 "RESERVED" 230 "RESERVED" 231 "RESERVED" 232 "RESERVED" 233 "RESERVED" 234 "RESERVED" 235 "RESERVED" 236 "RESERVED" 237 "RESERVED" 238 "RESERVED" 239 "RESERVED" 240 "RESERVED" 241 "RESERVED" 242 "RESERVED" 243 "RESERVED" 244 "RESERVED" 245 "RESERVED" 246 "RESERVED" 247 "RESERVED" 248 "RESERVED" 249 "RESERVED" 250 "RESERVED" 251 "RESERVED" 252 "RESERVED" 253 "RESERVED" 254 "RESERVED" 255 "Invalid" ;
VAL_ 290 L_ATCU_HU_FrDrEVntCtrBdryLo_X 0 "Default" 1 "0x01~0xC0:PHY=HEX*10 + 0" 192 "0x01~0xC0:PHY=HEX*10 + 0" 193 "RESERVED" 194 "RESERVED" 195 "RESERVED" 196 "RESERVED" 197 "RESERVED" 198 "RESERVED" 199 "RESERVED" 200 "RESERVED" 201 "RESERVED" 202 "RESERVED" 203 "RESERVED" 204 "RESERVED" 205 "RESERVED" 206 "RESERVED" 207 "RESERVED" 208 "RESERVED" 209 "RESERVED" 210 "RESERVED" 211 "RESERVED" 212 "RESERVED" 213 "RESERVED" 214 "RESERVED" 215 "RESERVED" 216 "RESERVED" 217 "RESERVED" 218 "RESERVED" 219 "RESERVED" 220 "RESERVED" 221 "RESERVED" 222 "RESERVED" 223 "RESERVED" 224 "RESERVED" 225 "RESERVED" 226 "RESERVED" 227 "RESERVED" 228 "RESERVED" 229 "RESERVED" 230 "RESERVED" 231 "RESERVED" 232 "RESERVED" 233 "RESERVED" 234 "RESERVED" 235 "RESERVED" 236 "RESERVED" 237 "RESERVED" 238 "RESERVED" 239 "RESERVED" 240 "RESERVED" 241 "RESERVED" 242 "RESERVED" 243 "RESERVED" 244 "RESERVED" 245 "RESERVED" 246 "RESERVED" 247 "RESERVED" 248 "RESERVED" 249 "RESERVED" 250 "RESERVED" 251 "RESERVED" 252 "RESERVED" 253 "RESERVED" 254 "RESERVED" 255 "Invalid" ;
VAL_ 290 L_ATCU_HU_FrDrEVntCtrBdryLo_Y 0 "Default" 1 "0x01~0xC0:PHY=HEX*10 + 0" 192 "0x01~0xC0:PHY=HEX*10 + 0" 193 "RESERVED" 194 "RESERVED" 195 "RESERVED" 196 "RESERVED" 197 "RESERVED" 198 "RESERVED" 199 "RESERVED" 200 "RESERVED" 201 "RESERVED" 202 "RESERVED" 203 "RESERVED" 204 "RESERVED" 205 "RESERVED" 206 "RESERVED" 207 "RESERVED" 208 "RESERVED" 209 "RESERVED" 210 "RESERVED" 211 "RESERVED" 212 "RESERVED" 213 "RESERVED" 214 "RESERVED" 215 "RESERVED" 216 "RESERVED" 217 "RESERVED" 218 "RESERVED" 219 "RESERVED" 220 "RESERVED" 221 "RESERVED" 222 "RESERVED" 223 "RESERVED" 224 "RESERVED" 225 "RESERVED" 226 "RESERVED" 227 "RESERVED" 228 "RESERVED" 229 "RESERVED" 230 "RESERVED" 231 "RESERVED" 232 "RESERVED" 233 "RESERVED" 234 "RESERVED" 235 "RESERVED" 236 "RESERVED" 237 "RESERVED" 238 "RESERVED" 239 "RESERVED" 240 "RESERVED" 241 "RESERVED" 242 "RESERVED" 243 "RESERVED" 244 "RESERVED" 245 "RESERVED" 246 "RESERVED" 247 "RESERVED" 248 "RESERVED" 249 "RESERVED" 250 "RESERVED" 251 "RESERVED" 252 "RESERVED" 253 "RESERVED" 254 "RESERVED" 255 "Invalid" ;
VAL_ 290 L_ATCU_HU_FrDrEVntSideBdryUp_Y 0 "Default" 1 "0x01~0xC0:PHY=HEX*10 + 0" 192 "0x01~0xC0:PHY=HEX*10 + 0" 193 "RESERVED" 194 "RESERVED" 195 "RESERVED" 196 "RESERVED" 197 "RESERVED" 198 "RESERVED" 199 "RESERVED" 200 "RESERVED" 201 "RESERVED" 202 "RESERVED" 203 "RESERVED" 204 "RESERVED" 205 "RESERVED" 206 "RESERVED" 207 "RESERVED" 208 "RESERVED" 209 "RESERVED" 210 "RESERVED" 211 "RESERVED" 212 "RESERVED" 213 "RESERVED" 214 "RESERVED" 215 "RESERVED" 216 "RESERVED" 217 "RESERVED" 218 "RESERVED" 219 "RESERVED" 220 "RESERVED" 221 "RESERVED" 222 "RESERVED" 223 "RESERVED" 224 "RESERVED" 225 "RESERVED" 226 "RESERVED" 227 "RESERVED" 228 "RESERVED" 229 "RESERVED" 230 "RESERVED" 231 "RESERVED" 232 "RESERVED" 233 "RESERVED" 234 "RESERVED" 235 "RESERVED" 236 "RESERVED" 237 "RESERVED" 238 "RESERVED" 239 "RESERVED" 240 "RESERVED" 241 "RESERVED" 242 "RESERVED" 243 "RESERVED" 244 "RESERVED" 245 "RESERVED" 246 "RESERVED" 247 "RESERVED" 248 "RESERVED" 249 "RESERVED" 250 "RESERVED" 251 "RESERVED" 252 "RESERVED" 253 "RESERVED" 254 "RESERVED" 255 "Invalid" ;
VAL_ 291 L_ATCU_HU_FrPsEVntSideBdryUp_X 0 "Default" 1 "0x01~0xC0:PHY=HEX*10 + 0" 192 "0x01~0xC0:PHY=HEX*10 + 0" 193 "RESERVED" 194 "RESERVED" 195 "RESERVED" 196 "RESERVED" 197 "RESERVED" 198 "RESERVED" 199 "RESERVED" 200 "RESERVED" 201 "RESERVED" 202 "RESERVED" 203 "RESERVED" 204 "RESERVED" 205 "RESERVED" 206 "RESERVED" 207 "RESERVED" 208 "RESERVED" 209 "RESERVED" 210 "RESERVED" 211 "RESERVED" 212 "RESERVED" 213 "RESERVED" 214 "RESERVED" 215 "RESERVED" 216 "RESERVED" 217 "RESERVED" 218 "RESERVED" 219 "RESERVED" 220 "RESERVED" 221 "RESERVED" 222 "RESERVED" 223 "RESERVED" 224 "RESERVED" 225 "RESERVED" 226 "RESERVED" 227 "RESERVED" 228 "RESERVED" 229 "RESERVED" 230 "RESERVED" 231 "RESERVED" 232 "RESERVED" 233 "RESERVED" 234 "RESERVED" 235 "RESERVED" 236 "RESERVED" 237 "RESERVED" 238 "RESERVED" 239 "RESERVED" 240 "RESERVED" 241 "RESERVED" 242 "RESERVED" 243 "RESERVED" 244 "RESERVED" 245 "RESERVED" 246 "RESERVED" 247 "RESERVED" 248 "RESERVED" 249 "RESERVED" 250 "RESERVED" 251 "RESERVED" 252 "RESERVED" 253 "RESERVED" 254 "RESERVED" 255 "Invalid" ;
VAL_ 291 L_ATCU_HU_FrPsEVntSideBdryLo_X 0 "Default" 1 "0x01~0xC0:PHY=HEX*10 + 0" 192 "0x01~0xC0:PHY=HEX*10 + 0" 193 "RESERVED" 194 "RESERVED" 195 "RESERVED" 196 "RESERVED" 197 "RESERVED" 198 "RESERVED" 199 "RESERVED" 200 "RESERVED" 201 "RESERVED" 202 "RESERVED" 203 "RESERVED" 204 "RESERVED" 205 "RESERVED" 206 "RESERVED" 207 "RESERVED" 208 "RESERVED" 209 "RESERVED" 210 "RESERVED" 211 "RESERVED" 212 "RESERVED" 213 "RESERVED" 214 "RESERVED" 215 "RESERVED" 216 "RESERVED" 217 "RESERVED" 218 "RESERVED" 219 "RESERVED" 220 "RESERVED" 221 "RESERVED" 222 "RESERVED" 223 "RESERVED" 224 "RESERVED" 225 "RESERVED" 226 "RESERVED" 227 "RESERVED" 228 "RESERVED" 229 "RESERVED" 230 "RESERVED" 231 "RESERVED" 232 "RESERVED" 233 "RESERVED" 234 "RESERVED" 235 "RESERVED" 236 "RESERVED" 237 "RESERVED" 238 "RESERVED" 239 "RESERVED" 240 "RESERVED" 241 "RESERVED" 242 "RESERVED" 243 "RESERVED" 244 "RESERVED" 245 "RESERVED" 246 "RESERVED" 247 "RESERVED" 248 "RESERVED" 249 "RESERVED" 250 "RESERVED" 251 "RESERVED" 252 "RESERVED" 253 "RESERVED" 254 "RESERVED" 255 "Invalid" ;
VAL_ 291 L_ATCU_HU_FrPsEVntSideBdryLo_Y 0 "Default" 1 "0x01~0xC0:PHY=HEX*10 + 0" 192 "0x01~0xC0:PHY=HEX*10 + 0" 193 "RESERVED" 194 "RESERVED" 195 "RESERVED" 196 "RESERVED" 197 "RESERVED" 198 "RESERVED" 199 "RESERVED" 200 "RESERVED" 201 "RESERVED" 202 "RESERVED" 203 "RESERVED" 204 "RESERVED" 205 "RESERVED" 206 "RESERVED" 207 "RESERVED" 208 "RESERVED" 209 "RESERVED" 210 "RESERVED" 211 "RESERVED" 212 "RESERVED" 213 "RESERVED" 214 "RESERVED" 215 "RESERVED" 216 "RESERVED" 217 "RESERVED" 218 "RESERVED" 219 "RESERVED" 220 "RESERVED" 221 "RESERVED" 222 "RESERVED" 223 "RESERVED" 224 "RESERVED" 225 "RESERVED" 226 "RESERVED" 227 "RESERVED" 228 "RESERVED" 229 "RESERVED" 230 "RESERVED" 231 "RESERVED" 232 "RESERVED" 233 "RESERVED" 234 "RESERVED" 235 "RESERVED" 236 "RESERVED" 237 "RESERVED" 238 "RESERVED" 239 "RESERVED" 240 "RESERVED" 241 "RESERVED" 242 "RESERVED" 243 "RESERVED" 244 "RESERVED" 245 "RESERVED" 246 "RESERVED" 247 "RESERVED" 248 "RESERVED" 249 "RESERVED" 250 "RESERVED" 251 "RESERVED" 252 "RESERVED" 253 "RESERVED" 254 "RESERVED" 255 "Invalid" ;
VAL_ 291 L_ATCU_HU_FrPsEVntCtrBdryUp_X 0 "Default" 1 "0x01~0xC0:PHY=HEX*10 + 0" 192 "0x01~0xC0:PHY=HEX*10 + 0" 193 "RESERVED" 194 "RESERVED" 195 "RESERVED" 196 "RESERVED" 197 "RESERVED" 198 "RESERVED" 199 "RESERVED" 200 "RESERVED" 201 "RESERVED" 202 "RESERVED" 203 "RESERVED" 204 "RESERVED" 205 "RESERVED" 206 "RESERVED" 207 "RESERVED" 208 "RESERVED" 209 "RESERVED" 210 "RESERVED" 211 "RESERVED" 212 "RESERVED" 213 "RESERVED" 214 "RESERVED" 215 "RESERVED" 216 "RESERVED" 217 "RESERVED" 218 "RESERVED" 219 "RESERVED" 220 "RESERVED" 221 "RESERVED" 222 "RESERVED" 223 "RESERVED" 224 "RESERVED" 225 "RESERVED" 226 "RESERVED" 227 "RESERVED" 228 "RESERVED" 229 "RESERVED" 230 "RESERVED" 231 "RESERVED" 232 "RESERVED" 233 "RESERVED" 234 "RESERVED" 235 "RESERVED" 236 "RESERVED" 237 "RESERVED" 238 "RESERVED" 239 "RESERVED" 240 "RESERVED" 241 "RESERVED" 242 "RESERVED" 243 "RESERVED" 244 "RESERVED" 245 "RESERVED" 246 "RESERVED" 247 "RESERVED" 248 "RESERVED" 249 "RESERVED" 250 "RESERVED" 251 "RESERVED" 252 "RESERVED" 253 "RESERVED" 254 "RESERVED" 255 "Invalid" ;
VAL_ 291 L_ATCU_HU_FrPsEVntCtrBdryUp_Y 0 "Default" 1 "0x01~0xC0:PHY=HEX*10 + 0" 192 "0x01~0xC0:PHY=HEX*10 + 0" 193 "RESERVED" 194 "RESERVED" 195 "RESERVED" 196 "RESERVED" 197 "RESERVED" 198 "RESERVED" 199 "RESERVED" 200 "RESERVED" 201 "RESERVED" 202 "RESERVED" 203 "RESERVED" 204 "RESERVED" 205 "RESERVED" 206 "RESERVED" 207 "RESERVED" 208 "RESERVED" 209 "RESERVED" 210 "RESERVED" 211 "RESERVED" 212 "RESERVED" 213 "RESERVED" 214 "RESERVED" 215 "RESERVED" 216 "RESERVED" 217 "RESERVED" 218 "RESERVED" 219 "RESERVED" 220 "RESERVED" 221 "RESERVED" 222 "RESERVED" 223 "RESERVED" 224 "RESERVED" 225 "RESERVED" 226 "RESERVED" 227 "RESERVED" 228 "RESERVED" 229 "RESERVED" 230 "RESERVED" 231 "RESERVED" 232 "RESERVED" 233 "RESERVED" 234 "RESERVED" 235 "RESERVED" 236 "RESERVED" 237 "RESERVED" 238 "RESERVED" 239 "RESERVED" 240 "RESERVED" 241 "RESERVED" 242 "RESERVED" 243 "RESERVED" 244 "RESERVED" 245 "RESERVED" 246 "RESERVED" 247 "RESERVED" 248 "RESERVED" 249 "RESERVED" 250 "RESERVED" 251 "RESERVED" 252 "RESERVED" 253 "RESERVED" 254 "RESERVED" 255 "Invalid" ;
VAL_ 291 L_ATCU_HU_FrPsEVntCtrBdryLo_X 0 "Default" 1 "0x01~0xC0:PHY=HEX*10 + 0" 192 "0x01~0xC0:PHY=HEX*10 + 0" 193 "RESERVED" 194 "RESERVED" 195 "RESERVED" 196 "RESERVED" 197 "RESERVED" 198 "RESERVED" 199 "RESERVED" 200 "RESERVED" 201 "RESERVED" 202 "RESERVED" 203 "RESERVED" 204 "RESERVED" 205 "RESERVED" 206 "RESERVED" 207 "RESERVED" 208 "RESERVED" 209 "RESERVED" 210 "RESERVED" 211 "RESERVED" 212 "RESERVED" 213 "RESERVED" 214 "RESERVED" 215 "RESERVED" 216 "RESERVED" 217 "RESERVED" 218 "RESERVED" 219 "RESERVED" 220 "RESERVED" 221 "RESERVED" 222 "RESERVED" 223 "RESERVED" 224 "RESERVED" 225 "RESERVED" 226 "RESERVED" 227 "RESERVED" 228 "RESERVED" 229 "RESERVED" 230 "RESERVED" 231 "RESERVED" 232 "RESERVED" 233 "RESERVED" 234 "RESERVED" 235 "RESERVED" 236 "RESERVED" 237 "RESERVED" 238 "RESERVED" 239 "RESERVED" 240 "RESERVED" 241 "RESERVED" 242 "RESERVED" 243 "RESERVED" 244 "RESERVED" 245 "RESERVED" 246 "RESERVED" 247 "RESERVED" 248 "RESERVED" 249 "RESERVED" 250 "RESERVED" 251 "RESERVED" 252 "RESERVED" 253 "RESERVED" 254 "RESERVED" 255 "Invalid" ;
VAL_ 291 L_ATCU_HU_FrPsEVntCtrBdryLo_Y 0 "Default" 1 "0x01~0xC0:PHY=HEX*10 + 0" 192 "0x01~0xC0:PHY=HEX*10 + 0" 193 "RESERVED" 194 "RESERVED" 195 "RESERVED" 196 "RESERVED" 197 "RESERVED" 198 "RESERVED" 199 "RESERVED" 200 "RESERVED" 201 "RESERVED" 202 "RESERVED" 203 "RESERVED" 204 "RESERVED" 205 "RESERVED" 206 "RESERVED" 207 "RESERVED" 208 "RESERVED" 209 "RESERVED" 210 "RESERVED" 211 "RESERVED" 212 "RESERVED" 213 "RESERVED" 214 "RESERVED" 215 "RESERVED" 216 "RESERVED" 217 "RESERVED" 218 "RESERVED" 219 "RESERVED" 220 "RESERVED" 221 "RESERVED" 222 "RESERVED" 223 "RESERVED" 224 "RESERVED" 225 "RESERVED" 226 "RESERVED" 227 "RESERVED" 228 "RESERVED" 229 "RESERVED" 230 "RESERVED" 231 "RESERVED" 232 "RESERVED" 233 "RESERVED" 234 "RESERVED" 235 "RESERVED" 236 "RESERVED" 237 "RESERVED" 238 "RESERVED" 239 "RESERVED" 240 "RESERVED" 241 "RESERVED" 242 "RESERVED" 243 "RESERVED" 244 "RESERVED" 245 "RESERVED" 246 "RESERVED" 247 "RESERVED" 248 "RESERVED" 249 "RESERVED" 250 "RESERVED" 251 "RESERVED" 252 "RESERVED" 253 "RESERVED" 254 "RESERVED" 255 "Invalid" ;
VAL_ 291 L_ATCU_HU_FrPsEVntSideBdryUp_Y 0 "Default" 1 "0x01~0xC0:PHY=HEX*10 + 0" 192 "0x01~0xC0:PHY=HEX*10 + 0" 193 "RESERVED" 194 "RESERVED" 195 "RESERVED" 196 "RESERVED" 197 "RESERVED" 198 "RESERVED" 199 "RESERVED" 200 "RESERVED" 201 "RESERVED" 202 "RESERVED" 203 "RESERVED" 204 "RESERVED" 205 "RESERVED" 206 "RESERVED" 207 "RESERVED" 208 "RESERVED" 209 "RESERVED" 210 "RESERVED" 211 "RESERVED" 212 "RESERVED" 213 "RESERVED" 214 "RESERVED" 215 "RESERVED" 216 "RESERVED" 217 "RESERVED" 218 "RESERVED" 219 "RESERVED" 220 "RESERVED" 221 "RESERVED" 222 "RESERVED" 223 "RESERVED" 224 "RESERVED" 225 "RESERVED" 226 "RESERVED" 227 "RESERVED" 228 "RESERVED" 229 "RESERVED" 230 "RESERVED" 231 "RESERVED" 232 "RESERVED" 233 "RESERVED" 234 "RESERVED" 235 "RESERVED" 236 "RESERVED" 237 "RESERVED" 238 "RESERVED" 239 "RESERVED" 240 "RESERVED" 241 "RESERVED" 242 "RESERVED" 243 "RESERVED" 244 "RESERVED" 245 "RESERVED" 246 "RESERVED" 247 "RESERVED" 248 "RESERVED" 249 "RESERVED" 250 "RESERVED" 251 "RESERVED" 252 "RESERVED" 253 "RESERVED" 254 "RESERVED" 255 "Invalid" ;
VAL_ 292 L_ATCU_HU_RrDrEVntConsBdryUp_X 0 "Default" 1 "0x01~0xC0:PHY=HEX*10 + 0" 192 "0x01~0xC0:PHY=HEX*10 + 0" 193 "RESERVED" 194 "RESERVED" 195 "RESERVED" 196 "RESERVED" 197 "RESERVED" 198 "RESERVED" 199 "RESERVED" 200 "RESERVED" 201 "RESERVED" 202 "RESERVED" 203 "RESERVED" 204 "RESERVED" 205 "RESERVED" 206 "RESERVED" 207 "RESERVED" 208 "RESERVED" 209 "RESERVED" 210 "RESERVED" 211 "RESERVED" 212 "RESERVED" 213 "RESERVED" 214 "RESERVED" 215 "RESERVED" 216 "RESERVED" 217 "RESERVED" 218 "RESERVED" 219 "RESERVED" 220 "RESERVED" 221 "RESERVED" 222 "RESERVED" 223 "RESERVED" 224 "RESERVED" 225 "RESERVED" 226 "RESERVED" 227 "RESERVED" 228 "RESERVED" 229 "RESERVED" 230 "RESERVED" 231 "RESERVED" 232 "RESERVED" 233 "RESERVED" 234 "RESERVED" 235 "RESERVED" 236 "RESERVED" 237 "RESERVED" 238 "RESERVED" 239 "RESERVED" 240 "RESERVED" 241 "RESERVED" 242 "RESERVED" 243 "RESERVED" 244 "RESERVED" 245 "RESERVED" 246 "RESERVED" 247 "RESERVED" 248 "RESERVED" 249 "RESERVED" 250 "RESERVED" 251 "RESERVED" 252 "RESERVED" 253 "RESERVED" 254 "RESERVED" 255 "Invalid" ;
VAL_ 292 L_ATCU_HU_RrDrEVntConsBdryLo_X 0 "Default" 1 "0x01~0xC0:PHY=HEX*10 + 0" 192 "0x01~0xC0:PHY=HEX*10 + 0" 193 "RESERVED" 194 "RESERVED" 195 "RESERVED" 196 "RESERVED" 197 "RESERVED" 198 "RESERVED" 199 "RESERVED" 200 "RESERVED" 201 "RESERVED" 202 "RESERVED" 203 "RESERVED" 204 "RESERVED" 205 "RESERVED" 206 "RESERVED" 207 "RESERVED" 208 "RESERVED" 209 "RESERVED" 210 "RESERVED" 211 "RESERVED" 212 "RESERVED" 213 "RESERVED" 214 "RESERVED" 215 "RESERVED" 216 "RESERVED" 217 "RESERVED" 218 "RESERVED" 219 "RESERVED" 220 "RESERVED" 221 "RESERVED" 222 "RESERVED" 223 "RESERVED" 224 "RESERVED" 225 "RESERVED" 226 "RESERVED" 227 "RESERVED" 228 "RESERVED" 229 "RESERVED" 230 "RESERVED" 231 "RESERVED" 232 "RESERVED" 233 "RESERVED" 234 "RESERVED" 235 "RESERVED" 236 "RESERVED" 237 "RESERVED" 238 "RESERVED" 239 "RESERVED" 240 "RESERVED" 241 "RESERVED" 242 "RESERVED" 243 "RESERVED" 244 "RESERVED" 245 "RESERVED" 246 "RESERVED" 247 "RESERVED" 248 "RESERVED" 249 "RESERVED" 250 "RESERVED" 251 "RESERVED" 252 "RESERVED" 253 "RESERVED" 254 "RESERVED" 255 "Invalid" ;
VAL_ 292 L_ATCU_HU_RrDrEVntConsBdryLo_Y 0 "Default" 1 "0x01~0xC0:PHY=HEX*10 + 0" 192 "0x01~0xC0:PHY=HEX*10 + 0" 193 "RESERVED" 194 "RESERVED" 195 "RESERVED" 196 "RESERVED" 197 "RESERVED" 198 "RESERVED" 199 "RESERVED" 200 "RESERVED" 201 "RESERVED" 202 "RESERVED" 203 "RESERVED" 204 "RESERVED" 205 "RESERVED" 206 "RESERVED" 207 "RESERVED" 208 "RESERVED" 209 "RESERVED" 210 "RESERVED" 211 "RESERVED" 212 "RESERVED" 213 "RESERVED" 214 "RESERVED" 215 "RESERVED" 216 "RESERVED" 217 "RESERVED" 218 "RESERVED" 219 "RESERVED" 220 "RESERVED" 221 "RESERVED" 222 "RESERVED" 223 "RESERVED" 224 "RESERVED" 225 "RESERVED" 226 "RESERVED" 227 "RESERVED" 228 "RESERVED" 229 "RESERVED" 230 "RESERVED" 231 "RESERVED" 232 "RESERVED" 233 "RESERVED" 234 "RESERVED" 235 "RESERVED" 236 "RESERVED" 237 "RESERVED" 238 "RESERVED" 239 "RESERVED" 240 "RESERVED" 241 "RESERVED" 242 "RESERVED" 243 "RESERVED" 244 "RESERVED" 245 "RESERVED" 246 "RESERVED" 247 "RESERVED" 248 "RESERVED" 249 "RESERVED" 250 "RESERVED" 251 "RESERVED" 252 "RESERVED" 253 "RESERVED" 254 "RESERVED" 255 "Invalid" ;
VAL_ 292 L_ATCU_HU_RrPsEVntConsBdryUp_X 0 "Default" 1 "0x01~0xC0:PHY=HEX*10 + 0" 192 "0x01~0xC0:PHY=HEX*10 + 0" 193 "RESERVED" 194 "RESERVED" 195 "RESERVED" 196 "RESERVED" 197 "RESERVED" 198 "RESERVED" 199 "RESERVED" 200 "RESERVED" 201 "RESERVED" 202 "RESERVED" 203 "RESERVED" 204 "RESERVED" 205 "RESERVED" 206 "RESERVED" 207 "RESERVED" 208 "RESERVED" 209 "RESERVED" 210 "RESERVED" 211 "RESERVED" 212 "RESERVED" 213 "RESERVED" 214 "RESERVED" 215 "RESERVED" 216 "RESERVED" 217 "RESERVED" 218 "RESERVED" 219 "RESERVED" 220 "RESERVED" 221 "RESERVED" 222 "RESERVED" 223 "RESERVED" 224 "RESERVED" 225 "RESERVED" 226 "RESERVED" 227 "RESERVED" 228 "RESERVED" 229 "RESERVED" 230 "RESERVED" 231 "RESERVED" 232 "RESERVED" 233 "RESERVED" 234 "RESERVED" 235 "RESERVED" 236 "RESERVED" 237 "RESERVED" 238 "RESERVED" 239 "RESERVED" 240 "RESERVED" 241 "RESERVED" 242 "RESERVED" 243 "RESERVED" 244 "RESERVED" 245 "RESERVED" 246 "RESERVED" 247 "RESERVED" 248 "RESERVED" 249 "RESERVED" 250 "RESERVED" 251 "RESERVED" 252 "RESERVED" 253 "RESERVED" 254 "RESERVED" 255 "Invalid" ;
VAL_ 292 L_ATCU_HU_RrPsEVntConsBdryUp_Y 0 "Default" 1 "0x01~0xC0:PHY=HEX*10 + 0" 192 "0x01~0xC0:PHY=HEX*10 + 0" 193 "RESERVED" 194 "RESERVED" 195 "RESERVED" 196 "RESERVED" 197 "RESERVED" 198 "RESERVED" 199 "RESERVED" 200 "RESERVED" 201 "RESERVED" 202 "RESERVED" 203 "RESERVED" 204 "RESERVED" 205 "RESERVED" 206 "RESERVED" 207 "RESERVED" 208 "RESERVED" 209 "RESERVED" 210 "RESERVED" 211 "RESERVED" 212 "RESERVED" 213 "RESERVED" 214 "RESERVED" 215 "RESERVED" 216 "RESERVED" 217 "RESERVED" 218 "RESERVED" 219 "RESERVED" 220 "RESERVED" 221 "RESERVED" 222 "RESERVED" 223 "RESERVED" 224 "RESERVED" 225 "RESERVED" 226 "RESERVED" 227 "RESERVED" 228 "RESERVED" 229 "RESERVED" 230 "RESERVED" 231 "RESERVED" 232 "RESERVED" 233 "RESERVED" 234 "RESERVED" 235 "RESERVED" 236 "RESERVED" 237 "RESERVED" 238 "RESERVED" 239 "RESERVED" 240 "RESERVED" 241 "RESERVED" 242 "RESERVED" 243 "RESERVED" 244 "RESERVED" 245 "RESERVED" 246 "RESERVED" 247 "RESERVED" 248 "RESERVED" 249 "RESERVED" 250 "RESERVED" 251 "RESERVED" 252 "RESERVED" 253 "RESERVED" 254 "RESERVED" 255 "Invalid" ;
VAL_ 292 L_ATCU_HU_RrPsEVntConsBdryLo_X 0 "Default" 1 "0x01~0xC0:PHY=HEX*10 + 0" 192 "0x01~0xC0:PHY=HEX*10 + 0" 193 "RESERVED" 194 "RESERVED" 195 "RESERVED" 196 "RESERVED" 197 "RESERVED" 198 "RESERVED" 199 "RESERVED" 200 "RESERVED" 201 "RESERVED" 202 "RESERVED" 203 "RESERVED" 204 "RESERVED" 205 "RESERVED" 206 "RESERVED" 207 "RESERVED" 208 "RESERVED" 209 "RESERVED" 210 "RESERVED" 211 "RESERVED" 212 "RESERVED" 213 "RESERVED" 214 "RESERVED" 215 "RESERVED" 216 "RESERVED" 217 "RESERVED" 218 "RESERVED" 219 "RESERVED" 220 "RESERVED" 221 "RESERVED" 222 "RESERVED" 223 "RESERVED" 224 "RESERVED" 225 "RESERVED" 226 "RESERVED" 227 "RESERVED" 228 "RESERVED" 229 "RESERVED" 230 "RESERVED" 231 "RESERVED" 232 "RESERVED" 233 "RESERVED" 234 "RESERVED" 235 "RESERVED" 236 "RESERVED" 237 "RESERVED" 238 "RESERVED" 239 "RESERVED" 240 "RESERVED" 241 "RESERVED" 242 "RESERVED" 243 "RESERVED" 244 "RESERVED" 245 "RESERVED" 246 "RESERVED" 247 "RESERVED" 248 "RESERVED" 249 "RESERVED" 250 "RESERVED" 251 "RESERVED" 252 "RESERVED" 253 "RESERVED" 254 "RESERVED" 255 "Invalid" ;
VAL_ 292 L_ATCU_HU_RrPsEVntConsBdryLo_Y 0 "Default" 1 "0x01~0xC0:PHY=HEX*10 + 0" 192 "0x01~0xC0:PHY=HEX*10 + 0" 193 "RESERVED" 194 "RESERVED" 195 "RESERVED" 196 "RESERVED" 197 "RESERVED" 198 "RESERVED" 199 "RESERVED" 200 "RESERVED" 201 "RESERVED" 202 "RESERVED" 203 "RESERVED" 204 "RESERVED" 205 "RESERVED" 206 "RESERVED" 207 "RESERVED" 208 "RESERVED" 209 "RESERVED" 210 "RESERVED" 211 "RESERVED" 212 "RESERVED" 213 "RESERVED" 214 "RESERVED" 215 "RESERVED" 216 "RESERVED" 217 "RESERVED" 218 "RESERVED" 219 "RESERVED" 220 "RESERVED" 221 "RESERVED" 222 "RESERVED" 223 "RESERVED" 224 "RESERVED" 225 "RESERVED" 226 "RESERVED" 227 "RESERVED" 228 "RESERVED" 229 "RESERVED" 230 "RESERVED" 231 "RESERVED" 232 "RESERVED" 233 "RESERVED" 234 "RESERVED" 235 "RESERVED" 236 "RESERVED" 237 "RESERVED" 238 "RESERVED" 239 "RESERVED" 240 "RESERVED" 241 "RESERVED" 242 "RESERVED" 243 "RESERVED" 244 "RESERVED" 245 "RESERVED" 246 "RESERVED" 247 "RESERVED" 248 "RESERVED" 249 "RESERVED" 250 "RESERVED" 251 "RESERVED" 252 "RESERVED" 253 "RESERVED" 254 "RESERVED" 255 "Invalid" ;
VAL_ 292 L_ATCU_HU_RrDrEVntConsBdryUp_Y 0 "Default" 1 "0x01~0xC0:PHY=HEX*10 + 0" 192 "0x01~0xC0:PHY=HEX*10 + 0" 193 "RESERVED" 194 "RESERVED" 195 "RESERVED" 196 "RESERVED" 197 "RESERVED" 198 "RESERVED" 199 "RESERVED" 200 "RESERVED" 201 "RESERVED" 202 "RESERVED" 203 "RESERVED" 204 "RESERVED" 205 "RESERVED" 206 "RESERVED" 207 "RESERVED" 208 "RESERVED" 209 "RESERVED" 210 "RESERVED" 211 "RESERVED" 212 "RESERVED" 213 "RESERVED" 214 "RESERVED" 215 "RESERVED" 216 "RESERVED" 217 "RESERVED" 218 "RESERVED" 219 "RESERVED" 220 "RESERVED" 221 "RESERVED" 222 "RESERVED" 223 "RESERVED" 224 "RESERVED" 225 "RESERVED" 226 "RESERVED" 227 "RESERVED" 228 "RESERVED" 229 "RESERVED" 230 "RESERVED" 231 "RESERVED" 232 "RESERVED" 233 "RESERVED" 234 "RESERVED" 235 "RESERVED" 236 "RESERVED" 237 "RESERVED" 238 "RESERVED" 239 "RESERVED" 240 "RESERVED" 241 "RESERVED" 242 "RESERVED" 243 "RESERVED" 244 "RESERVED" 245 "RESERVED" 246 "RESERVED" 247 "RESERVED" 248 "RESERVED" 249 "RESERVED" 250 "RESERVED" 251 "RESERVED" 252 "RESERVED" 253 "RESERVED" 254 "RESERVED" 255 "Invalid" ;
VAL_ 293 L_ATCU_CTS_FrDrEVntSidePt_X 0 "Default" 1 "0x001~0x780:PHY=HEX*1 + 0" 1920 "0x001~0x780:PHY=HEX*1 + 0" 1921 "0x781~0x7FE:RESERVED" 2046 "0x781~0x7FE:RESERVED" 2047 "Invalid" ;
VAL_ 293 L_ATCU_CTS_FrDrEVntSidePt_Y 0 "Default" 1 "0x001~0x780:PHY=HEX*1 + 0" 1920 "0x001~0x780:PHY=HEX*1 + 0" 1921 "0x781~0x7FE:RESERVED" 2046 "0x781~0x7FE:RESERVED" 2047 "Invalid" ;
VAL_ 293 L_ATCU_CTS_FrDrEVntCtrPt_X 0 "Default" 1 "0x001~0x780:PHY=HEX*1 + 0" 1920 "0x001~0x780:PHY=HEX*1 + 0" 1921 "0x781~0x7FE:RESERVED" 2046 "0x781~0x7FE:RESERVED" 2047 "Invalid" ;
VAL_ 293 L_ATCU_CTS_FrDrEVntCtrPt_Y 0 "Default" 1 "0x001~0x780:PHY=HEX*1 + 0" 1920 "0x001~0x780:PHY=HEX*1 + 0" 1921 "0x781~0x7FE:RESERVED" 2046 "0x781~0x7FE:RESERVED" 2047 "Invalid" ;
VAL_ 294 L_ATCU_CTS_FrPsEVntSidePt_X 0 "Default" 1 "0x001~0x780:PHY=HEX*1 + 0" 1920 "0x001~0x780:PHY=HEX*1 + 0" 1921 "0x781~0x7FE:RESERVED" 2046 "0x781~0x7FE:RESERVED" 2047 "Invalid" ;
VAL_ 294 L_ATCU_CTS_FrPsEVntSidePt_Y 0 "Default" 1 "0x001~0x780:PHY=HEX*1 + 0" 1920 "0x001~0x780:PHY=HEX*1 + 0" 1921 "0x781~0x7FE:RESERVED" 2046 "0x781~0x7FE:RESERVED" 2047 "Invalid" ;
VAL_ 294 L_ATCU_CTS_FrPsEVntCtrPt_X 0 "Default" 1 "0x001~0x780:PHY=HEX*1 + 0" 1920 "0x001~0x780:PHY=HEX*1 + 0" 1921 "0x781~0x7FE:RESERVED" 2046 "0x781~0x7FE:RESERVED" 2047 "Invalid" ;
VAL_ 294 L_ATCU_CTS_FrPsEVntCtrPt_Y 0 "Default" 1 "0x001~0x780:PHY=HEX*1 + 0" 1920 "0x001~0x780:PHY=HEX*1 + 0" 1921 "0x781~0x7FE:RESERVED" 2046 "0x781~0x7FE:RESERVED" 2047 "Invalid" ;
VAL_ 295 L_ATCU_CTS_RrDrEVntConsPt_X 0 "Default" 1 "0x001~0x780:PHY=HEX*1 + 0" 1920 "0x001~0x780:PHY=HEX*1 + 0" 1921 "0x781~0x7FE:RESERVED" 2046 "0x781~0x7FE:RESERVED" 2047 "Invalid" ;
VAL_ 295 L_ATCU_CTS_RrDrEVntConsPt_Y 0 "Default" 1 "0x001~0x780:PHY=HEX*1 + 0" 1920 "0x001~0x780:PHY=HEX*1 + 0" 1921 "0x781~0x7FE:RESERVED" 2046 "0x781~0x7FE:RESERVED" 2047 "Invalid" ;
VAL_ 295 L_ATCU_CTS_RrPsEVntConsPt_X 0 "Default" 1 "0x001~0x780:PHY=HEX*1 + 0" 1920 "0x001~0x780:PHY=HEX*1 + 0" 1921 "0x781~0x7FE:RESERVED" 2046 "0x781~0x7FE:RESERVED" 2047 "Invalid" ;
VAL_ 295 L_ATCU_CTS_RrPsEVntConsPt_Y 0 "Default" 1 "0x001~0x780:PHY=HEX*1 + 0" 1920 "0x001~0x780:PHY=HEX*1 + 0" 1921 "0x781~0x7FE:RESERVED" 2046 "0x781~0x7FE:RESERVED" 2047 "Invalid" ;
VAL_ 295 L_ATCU_CTS_RrDrEVntModeSet 0 "Default" 1 "FOCUS Mode" 2 "SPREAD Mode" 3 "CYCLE Mode" 4 "Manual Mode" 5 "OFF" 6 "RESERVED" 7 "RESERVED" 8 "RESERVED" 9 "RESERVED" 10 "RESERVED" 11 "RESERVED" 12 "RESERVED" 13 "RESERVED" 14 "RESERVED" 15 "Invalid" ;
VAL_ 295 L_ATCU_CTS_RrPsEVntModeSet 0 "Default" 1 "FOCUS Mode" 2 "SPREAD Mode" 3 "CYCLE Mode" 4 "Manual Mode" 5 "OFF" 6 "RESERVED" 7 "RESERVED" 8 "RESERVED" 9 "RESERVED" 10 "RESERVED" 11 "RESERVED" 12 "RESERVED" 13 "RESERVED" 14 "RESERVED" 15 "Invalid" ;
VAL_ 295 L_ATCU_CTS_RrDrEVntConsOpnCls 0 "Default" 1 "OPEN" 2 "CLOSE" 3 "Invalid" ;
VAL_ 295 L_ATCU_CTS_RrPsEVntConsOpnCls 0 "Default" 1 "OPEN" 2 "CLOSE" 3 "Invalid" ;
VAL_ 296 L_ATCU_CTS_FrDrEVntSideBdryUp_X 0 "Default" 1 "0x01~0xC0:PHY=HEX*10 + 0" 192 "0x01~0xC0:PHY=HEX*10 + 0" 193 "RESERVED" 194 "RESERVED" 195 "RESERVED" 196 "RESERVED" 197 "RESERVED" 198 "RESERVED" 199 "RESERVED" 200 "RESERVED" 201 "RESERVED" 202 "RESERVED" 203 "RESERVED" 204 "RESERVED" 205 "RESERVED" 206 "RESERVED" 207 "RESERVED" 208 "RESERVED" 209 "RESERVED" 210 "RESERVED" 211 "RESERVED" 212 "RESERVED" 213 "RESERVED" 214 "RESERVED" 215 "RESERVED" 216 "RESERVED" 217 "RESERVED" 218 "RESERVED" 219 "RESERVED" 220 "RESERVED" 221 "RESERVED" 222 "RESERVED" 223 "RESERVED" 224 "RESERVED" 225 "RESERVED" 226 "RESERVED" 227 "RESERVED" 228 "RESERVED" 229 "RESERVED" 230 "RESERVED" 231 "RESERVED" 232 "RESERVED" 233 "RESERVED" 234 "RESERVED" 235 "RESERVED" 236 "RESERVED" 237 "RESERVED" 238 "RESERVED" 239 "RESERVED" 240 "RESERVED" 241 "RESERVED" 242 "RESERVED" 243 "RESERVED" 244 "RESERVED" 245 "RESERVED" 246 "RESERVED" 247 "RESERVED" 248 "RESERVED" 249 "RESERVED" 250 "RESERVED" 251 "RESERVED" 252 "RESERVED" 253 "RESERVED" 254 "RESERVED" 255 "Invalid" ;
VAL_ 296 L_ATCU_CTS_FrDrEVntSideBdryLo_X 0 "Default" 1 "0x01~0xC0:PHY=HEX*10 + 0" 192 "0x01~0xC0:PHY=HEX*10 + 0" 193 "RESERVED" 194 "RESERVED" 195 "RESERVED" 196 "RESERVED" 197 "RESERVED" 198 "RESERVED" 199 "RESERVED" 200 "RESERVED" 201 "RESERVED" 202 "RESERVED" 203 "RESERVED" 204 "RESERVED" 205 "RESERVED" 206 "RESERVED" 207 "RESERVED" 208 "RESERVED" 209 "RESERVED" 210 "RESERVED" 211 "RESERVED" 212 "RESERVED" 213 "RESERVED" 214 "RESERVED" 215 "RESERVED" 216 "RESERVED" 217 "RESERVED" 218 "RESERVED" 219 "RESERVED" 220 "RESERVED" 221 "RESERVED" 222 "RESERVED" 223 "RESERVED" 224 "RESERVED" 225 "RESERVED" 226 "RESERVED" 227 "RESERVED" 228 "RESERVED" 229 "RESERVED" 230 "RESERVED" 231 "RESERVED" 232 "RESERVED" 233 "RESERVED" 234 "RESERVED" 235 "RESERVED" 236 "RESERVED" 237 "RESERVED" 238 "RESERVED" 239 "RESERVED" 240 "RESERVED" 241 "RESERVED" 242 "RESERVED" 243 "RESERVED" 244 "RESERVED" 245 "RESERVED" 246 "RESERVED" 247 "RESERVED" 248 "RESERVED" 249 "RESERVED" 250 "RESERVED" 251 "RESERVED" 252 "RESERVED" 253 "RESERVED" 254 "RESERVED" 255 "Invalid" ;
VAL_ 296 L_ATCU_CTS_FrDrEVntSideBdryLo_Y 0 "Default" 1 "0x01~0xC0:PHY=HEX*10 + 0" 192 "0x01~0xC0:PHY=HEX*10 + 0" 193 "RESERVED" 194 "RESERVED" 195 "RESERVED" 196 "RESERVED" 197 "RESERVED" 198 "RESERVED" 199 "RESERVED" 200 "RESERVED" 201 "RESERVED" 202 "RESERVED" 203 "RESERVED" 204 "RESERVED" 205 "RESERVED" 206 "RESERVED" 207 "RESERVED" 208 "RESERVED" 209 "RESERVED" 210 "RESERVED" 211 "RESERVED" 212 "RESERVED" 213 "RESERVED" 214 "RESERVED" 215 "RESERVED" 216 "RESERVED" 217 "RESERVED" 218 "RESERVED" 219 "RESERVED" 220 "RESERVED" 221 "RESERVED" 222 "RESERVED" 223 "RESERVED" 224 "RESERVED" 225 "RESERVED" 226 "RESERVED" 227 "RESERVED" 228 "RESERVED" 229 "RESERVED" 230 "RESERVED" 231 "RESERVED" 232 "RESERVED" 233 "RESERVED" 234 "RESERVED" 235 "RESERVED" 236 "RESERVED" 237 "RESERVED" 238 "RESERVED" 239 "RESERVED" 240 "RESERVED" 241 "RESERVED" 242 "RESERVED" 243 "RESERVED" 244 "RESERVED" 245 "RESERVED" 246 "RESERVED" 247 "RESERVED" 248 "RESERVED" 249 "RESERVED" 250 "RESERVED" 251 "RESERVED" 252 "RESERVED" 253 "RESERVED" 254 "RESERVED" 255 "Invalid" ;
VAL_ 296 L_ATCU_CTS_FrDrEVntCtrBdryUp_X 0 "Default" 1 "0x01~0xC0:PHY=HEX*10 + 0" 192 "0x01~0xC0:PHY=HEX*10 + 0" 193 "RESERVED" 194 "RESERVED" 195 "RESERVED" 196 "RESERVED" 197 "RESERVED" 198 "RESERVED" 199 "RESERVED" 200 "RESERVED" 201 "RESERVED" 202 "RESERVED" 203 "RESERVED" 204 "RESERVED" 205 "RESERVED" 206 "RESERVED" 207 "RESERVED" 208 "RESERVED" 209 "RESERVED" 210 "RESERVED" 211 "RESERVED" 212 "RESERVED" 213 "RESERVED" 214 "RESERVED" 215 "RESERVED" 216 "RESERVED" 217 "RESERVED" 218 "RESERVED" 219 "RESERVED" 220 "RESERVED" 221 "RESERVED" 222 "RESERVED" 223 "RESERVED" 224 "RESERVED" 225 "RESERVED" 226 "RESERVED" 227 "RESERVED" 228 "RESERVED" 229 "RESERVED" 230 "RESERVED" 231 "RESERVED" 232 "RESERVED" 233 "RESERVED" 234 "RESERVED" 235 "RESERVED" 236 "RESERVED" 237 "RESERVED" 238 "RESERVED" 239 "RESERVED" 240 "RESERVED" 241 "RESERVED" 242 "RESERVED" 243 "RESERVED" 244 "RESERVED" 245 "RESERVED" 246 "RESERVED" 247 "RESERVED" 248 "RESERVED" 249 "RESERVED" 250 "RESERVED" 251 "RESERVED" 252 "RESERVED" 253 "RESERVED" 254 "RESERVED" 255 "Invalid" ;
VAL_ 296 L_ATCU_CTS_FrDrEVntCtrBdryUp_Y 0 "Default" 1 "0x01~0xC0:PHY=HEX*10 + 0" 192 "0x01~0xC0:PHY=HEX*10 + 0" 193 "RESERVED" 194 "RESERVED" 195 "RESERVED" 196 "RESERVED" 197 "RESERVED" 198 "RESERVED" 199 "RESERVED" 200 "RESERVED" 201 "RESERVED" 202 "RESERVED" 203 "RESERVED" 204 "RESERVED" 205 "RESERVED" 206 "RESERVED" 207 "RESERVED" 208 "RESERVED" 209 "RESERVED" 210 "RESERVED" 211 "RESERVED" 212 "RESERVED" 213 "RESERVED" 214 "RESERVED" 215 "RESERVED" 216 "RESERVED" 217 "RESERVED" 218 "RESERVED" 219 "RESERVED" 220 "RESERVED" 221 "RESERVED" 222 "RESERVED" 223 "RESERVED" 224 "RESERVED" 225 "RESERVED" 226 "RESERVED" 227 "RESERVED" 228 "RESERVED" 229 "RESERVED" 230 "RESERVED" 231 "RESERVED" 232 "RESERVED" 233 "RESERVED" 234 "RESERVED" 235 "RESERVED" 236 "RESERVED" 237 "RESERVED" 238 "RESERVED" 239 "RESERVED" 240 "RESERVED" 241 "RESERVED" 242 "RESERVED" 243 "RESERVED" 244 "RESERVED" 245 "RESERVED" 246 "RESERVED" 247 "RESERVED" 248 "RESERVED" 249 "RESERVED" 250 "RESERVED" 251 "RESERVED" 252 "RESERVED" 253 "RESERVED" 254 "RESERVED" 255 "Invalid" ;
VAL_ 296 L_ATCU_CTS_FrDrEVntCtrBdryLo_X 0 "Default" 1 "0x01~0xC0:PHY=HEX*10 + 0" 192 "0x01~0xC0:PHY=HEX*10 + 0" 193 "RESERVED" 194 "RESERVED" 195 "RESERVED" 196 "RESERVED" 197 "RESERVED" 198 "RESERVED" 199 "RESERVED" 200 "RESERVED" 201 "RESERVED" 202 "RESERVED" 203 "RESERVED" 204 "RESERVED" 205 "RESERVED" 206 "RESERVED" 207 "RESERVED" 208 "RESERVED" 209 "RESERVED" 210 "RESERVED" 211 "RESERVED" 212 "RESERVED" 213 "RESERVED" 214 "RESERVED" 215 "RESERVED" 216 "RESERVED" 217 "RESERVED" 218 "RESERVED" 219 "RESERVED" 220 "RESERVED" 221 "RESERVED" 222 "RESERVED" 223 "RESERVED" 224 "RESERVED" 225 "RESERVED" 226 "RESERVED" 227 "RESERVED" 228 "RESERVED" 229 "RESERVED" 230 "RESERVED" 231 "RESERVED" 232 "RESERVED" 233 "RESERVED" 234 "RESERVED" 235 "RESERVED" 236 "RESERVED" 237 "RESERVED" 238 "RESERVED" 239 "RESERVED" 240 "RESERVED" 241 "RESERVED" 242 "RESERVED" 243 "RESERVED" 244 "RESERVED" 245 "RESERVED" 246 "RESERVED" 247 "RESERVED" 248 "RESERVED" 249 "RESERVED" 250 "RESERVED" 251 "RESERVED" 252 "RESERVED" 253 "RESERVED" 254 "RESERVED" 255 "Invalid" ;
VAL_ 296 L_ATCU_CTS_FrDrEVntCtrBdryLo_Y 0 "Default" 1 "0x01~0xC0:PHY=HEX*10 + 0" 192 "0x01~0xC0:PHY=HEX*10 + 0" 193 "RESERVED" 194 "RESERVED" 195 "RESERVED" 196 "RESERVED" 197 "RESERVED" 198 "RESERVED" 199 "RESERVED" 200 "RESERVED" 201 "RESERVED" 202 "RESERVED" 203 "RESERVED" 204 "RESERVED" 205 "RESERVED" 206 "RESERVED" 207 "RESERVED" 208 "RESERVED" 209 "RESERVED" 210 "RESERVED" 211 "RESERVED" 212 "RESERVED" 213 "RESERVED" 214 "RESERVED" 215 "RESERVED" 216 "RESERVED" 217 "RESERVED" 218 "RESERVED" 219 "RESERVED" 220 "RESERVED" 221 "RESERVED" 222 "RESERVED" 223 "RESERVED" 224 "RESERVED" 225 "RESERVED" 226 "RESERVED" 227 "RESERVED" 228 "RESERVED" 229 "RESERVED" 230 "RESERVED" 231 "RESERVED" 232 "RESERVED" 233 "RESERVED" 234 "RESERVED" 235 "RESERVED" 236 "RESERVED" 237 "RESERVED" 238 "RESERVED" 239 "RESERVED" 240 "RESERVED" 241 "RESERVED" 242 "RESERVED" 243 "RESERVED" 244 "RESERVED" 245 "RESERVED" 246 "RESERVED" 247 "RESERVED" 248 "RESERVED" 249 "RESERVED" 250 "RESERVED" 251 "RESERVED" 252 "RESERVED" 253 "RESERVED" 254 "RESERVED" 255 "Invalid" ;
VAL_ 296 L_ATCU_CTS_FrDrEVntSideBdryUp_Y 0 "Default" 1 "0x01~0xC0:PHY=HEX*10 + 0" 192 "0x01~0xC0:PHY=HEX*10 + 0" 193 "RESERVED" 194 "RESERVED" 195 "RESERVED" 196 "RESERVED" 197 "RESERVED" 198 "RESERVED" 199 "RESERVED" 200 "RESERVED" 201 "RESERVED" 202 "RESERVED" 203 "RESERVED" 204 "RESERVED" 205 "RESERVED" 206 "RESERVED" 207 "RESERVED" 208 "RESERVED" 209 "RESERVED" 210 "RESERVED" 211 "RESERVED" 212 "RESERVED" 213 "RESERVED" 214 "RESERVED" 215 "RESERVED" 216 "RESERVED" 217 "RESERVED" 218 "RESERVED" 219 "RESERVED" 220 "RESERVED" 221 "RESERVED" 222 "RESERVED" 223 "RESERVED" 224 "RESERVED" 225 "RESERVED" 226 "RESERVED" 227 "RESERVED" 228 "RESERVED" 229 "RESERVED" 230 "RESERVED" 231 "RESERVED" 232 "RESERVED" 233 "RESERVED" 234 "RESERVED" 235 "RESERVED" 236 "RESERVED" 237 "RESERVED" 238 "RESERVED" 239 "RESERVED" 240 "RESERVED" 241 "RESERVED" 242 "RESERVED" 243 "RESERVED" 244 "RESERVED" 245 "RESERVED" 246 "RESERVED" 247 "RESERVED" 248 "RESERVED" 249 "RESERVED" 250 "RESERVED" 251 "RESERVED" 252 "RESERVED" 253 "RESERVED" 254 "RESERVED" 255 "Invalid" ;
VAL_ 297 L_ATCU_CTS_FrPsEVntSideBdryUp_X 0 "Default" 1 "0x01~0xC0:PHY=HEX*10 + 0" 192 "0x01~0xC0:PHY=HEX*10 + 0" 193 "RESERVED" 194 "RESERVED" 195 "RESERVED" 196 "RESERVED" 197 "RESERVED" 198 "RESERVED" 199 "RESERVED" 200 "RESERVED" 201 "RESERVED" 202 "RESERVED" 203 "RESERVED" 204 "RESERVED" 205 "RESERVED" 206 "RESERVED" 207 "RESERVED" 208 "RESERVED" 209 "RESERVED" 210 "RESERVED" 211 "RESERVED" 212 "RESERVED" 213 "RESERVED" 214 "RESERVED" 215 "RESERVED" 216 "RESERVED" 217 "RESERVED" 218 "RESERVED" 219 "RESERVED" 220 "RESERVED" 221 "RESERVED" 222 "RESERVED" 223 "RESERVED" 224 "RESERVED" 225 "RESERVED" 226 "RESERVED" 227 "RESERVED" 228 "RESERVED" 229 "RESERVED" 230 "RESERVED" 231 "RESERVED" 232 "RESERVED" 233 "RESERVED" 234 "RESERVED" 235 "RESERVED" 236 "RESERVED" 237 "RESERVED" 238 "RESERVED" 239 "RESERVED" 240 "RESERVED" 241 "RESERVED" 242 "RESERVED" 243 "RESERVED" 244 "RESERVED" 245 "RESERVED" 246 "RESERVED" 247 "RESERVED" 248 "RESERVED" 249 "RESERVED" 250 "RESERVED" 251 "RESERVED" 252 "RESERVED" 253 "RESERVED" 254 "RESERVED" 255 "Invalid" ;
VAL_ 297 L_ATCU_CTS_FrPsEVntSideBdryLo_X 0 "Default" 1 "0x01~0xC0:PHY=HEX*10 + 0" 192 "0x01~0xC0:PHY=HEX*10 + 0" 193 "RESERVED" 194 "RESERVED" 195 "RESERVED" 196 "RESERVED" 197 "RESERVED" 198 "RESERVED" 199 "RESERVED" 200 "RESERVED" 201 "RESERVED" 202 "RESERVED" 203 "RESERVED" 204 "RESERVED" 205 "RESERVED" 206 "RESERVED" 207 "RESERVED" 208 "RESERVED" 209 "RESERVED" 210 "RESERVED" 211 "RESERVED" 212 "RESERVED" 213 "RESERVED" 214 "RESERVED" 215 "RESERVED" 216 "RESERVED" 217 "RESERVED" 218 "RESERVED" 219 "RESERVED" 220 "RESERVED" 221 "RESERVED" 222 "RESERVED" 223 "RESERVED" 224 "RESERVED" 225 "RESERVED" 226 "RESERVED" 227 "RESERVED" 228 "RESERVED" 229 "RESERVED" 230 "RESERVED" 231 "RESERVED" 232 "RESERVED" 233 "RESERVED" 234 "RESERVED" 235 "RESERVED" 236 "RESERVED" 237 "RESERVED" 238 "RESERVED" 239 "RESERVED" 240 "RESERVED" 241 "RESERVED" 242 "RESERVED" 243 "RESERVED" 244 "RESERVED" 245 "RESERVED" 246 "RESERVED" 247 "RESERVED" 248 "RESERVED" 249 "RESERVED" 250 "RESERVED" 251 "RESERVED" 252 "RESERVED" 253 "RESERVED" 254 "RESERVED" 255 "Invalid" ;
VAL_ 297 L_ATCU_CTS_FrPsEVntSideBdryLo_Y 0 "Default" 1 "0x01~0xC0:PHY=HEX*10 + 0" 192 "0x01~0xC0:PHY=HEX*10 + 0" 193 "RESERVED" 194 "RESERVED" 195 "RESERVED" 196 "RESERVED" 197 "RESERVED" 198 "RESERVED" 199 "RESERVED" 200 "RESERVED" 201 "RESERVED" 202 "RESERVED" 203 "RESERVED" 204 "RESERVED" 205 "RESERVED" 206 "RESERVED" 207 "RESERVED" 208 "RESERVED" 209 "RESERVED" 210 "RESERVED" 211 "RESERVED" 212 "RESERVED" 213 "RESERVED" 214 "RESERVED" 215 "RESERVED" 216 "RESERVED" 217 "RESERVED" 218 "RESERVED" 219 "RESERVED" 220 "RESERVED" 221 "RESERVED" 222 "RESERVED" 223 "RESERVED" 224 "RESERVED" 225 "RESERVED" 226 "RESERVED" 227 "RESERVED" 228 "RESERVED" 229 "RESERVED" 230 "RESERVED" 231 "RESERVED" 232 "RESERVED" 233 "RESERVED" 234 "RESERVED" 235 "RESERVED" 236 "RESERVED" 237 "RESERVED" 238 "RESERVED" 239 "RESERVED" 240 "RESERVED" 241 "RESERVED" 242 "RESERVED" 243 "RESERVED" 244 "RESERVED" 245 "RESERVED" 246 "RESERVED" 247 "RESERVED" 248 "RESERVED" 249 "RESERVED" 250 "RESERVED" 251 "RESERVED" 252 "RESERVED" 253 "RESERVED" 254 "RESERVED" 255 "Invalid" ;
VAL_ 297 L_ATCU_CTS_FrPsEVntCtrBdryUp_X 0 "Default" 1 "0x01~0xC0:PHY=HEX*10 + 0" 192 "0x01~0xC0:PHY=HEX*10 + 0" 193 "RESERVED" 194 "RESERVED" 195 "RESERVED" 196 "RESERVED" 197 "RESERVED" 198 "RESERVED" 199 "RESERVED" 200 "RESERVED" 201 "RESERVED" 202 "RESERVED" 203 "RESERVED" 204 "RESERVED" 205 "RESERVED" 206 "RESERVED" 207 "RESERVED" 208 "RESERVED" 209 "RESERVED" 210 "RESERVED" 211 "RESERVED" 212 "RESERVED" 213 "RESERVED" 214 "RESERVED" 215 "RESERVED" 216 "RESERVED" 217 "RESERVED" 218 "RESERVED" 219 "RESERVED" 220 "RESERVED" 221 "RESERVED" 222 "RESERVED" 223 "RESERVED" 224 "RESERVED" 225 "RESERVED" 226 "RESERVED" 227 "RESERVED" 228 "RESERVED" 229 "RESERVED" 230 "RESERVED" 231 "RESERVED" 232 "RESERVED" 233 "RESERVED" 234 "RESERVED" 235 "RESERVED" 236 "RESERVED" 237 "RESERVED" 238 "RESERVED" 239 "RESERVED" 240 "RESERVED" 241 "RESERVED" 242 "RESERVED" 243 "RESERVED" 244 "RESERVED" 245 "RESERVED" 246 "RESERVED" 247 "RESERVED" 248 "RESERVED" 249 "RESERVED" 250 "RESERVED" 251 "RESERVED" 252 "RESERVED" 253 "RESERVED" 254 "RESERVED" 255 "Invalid" ;
VAL_ 297 L_ATCU_CTS_FrPsEVntCtrBdryUp_Y 0 "Default" 1 "0x01~0xC0:PHY=HEX*10 + 0" 192 "0x01~0xC0:PHY=HEX*10 + 0" 193 "RESERVED" 194 "RESERVED" 195 "RESERVED" 196 "RESERVED" 197 "RESERVED" 198 "RESERVED" 199 "RESERVED" 200 "RESERVED" 201 "RESERVED" 202 "RESERVED" 203 "RESERVED" 204 "RESERVED" 205 "RESERVED" 206 "RESERVED" 207 "RESERVED" 208 "RESERVED" 209 "RESERVED" 210 "RESERVED" 211 "RESERVED" 212 "RESERVED" 213 "RESERVED" 214 "RESERVED" 215 "RESERVED" 216 "RESERVED" 217 "RESERVED" 218 "RESERVED" 219 "RESERVED" 220 "RESERVED" 221 "RESERVED" 222 "RESERVED" 223 "RESERVED" 224 "RESERVED" 225 "RESERVED" 226 "RESERVED" 227 "RESERVED" 228 "RESERVED" 229 "RESERVED" 230 "RESERVED" 231 "RESERVED" 232 "RESERVED" 233 "RESERVED" 234 "RESERVED" 235 "RESERVED" 236 "RESERVED" 237 "RESERVED" 238 "RESERVED" 239 "RESERVED" 240 "RESERVED" 241 "RESERVED" 242 "RESERVED" 243 "RESERVED" 244 "RESERVED" 245 "RESERVED" 246 "RESERVED" 247 "RESERVED" 248 "RESERVED" 249 "RESERVED" 250 "RESERVED" 251 "RESERVED" 252 "RESERVED" 253 "RESERVED" 254 "RESERVED" 255 "Invalid" ;
VAL_ 297 L_ATCU_CTS_FrPsEVntCtrBdryLo_X 0 "Default" 1 "0x01~0xC0:PHY=HEX*10 + 0" 192 "0x01~0xC0:PHY=HEX*10 + 0" 193 "RESERVED" 194 "RESERVED" 195 "RESERVED" 196 "RESERVED" 197 "RESERVED" 198 "RESERVED" 199 "RESERVED" 200 "RESERVED" 201 "RESERVED" 202 "RESERVED" 203 "RESERVED" 204 "RESERVED" 205 "RESERVED" 206 "RESERVED" 207 "RESERVED" 208 "RESERVED" 209 "RESERVED" 210 "RESERVED" 211 "RESERVED" 212 "RESERVED" 213 "RESERVED" 214 "RESERVED" 215 "RESERVED" 216 "RESERVED" 217 "RESERVED" 218 "RESERVED" 219 "RESERVED" 220 "RESERVED" 221 "RESERVED" 222 "RESERVED" 223 "RESERVED" 224 "RESERVED" 225 "RESERVED" 226 "RESERVED" 227 "RESERVED" 228 "RESERVED" 229 "RESERVED" 230 "RESERVED" 231 "RESERVED" 232 "RESERVED" 233 "RESERVED" 234 "RESERVED" 235 "RESERVED" 236 "RESERVED" 237 "RESERVED" 238 "RESERVED" 239 "RESERVED" 240 "RESERVED" 241 "RESERVED" 242 "RESERVED" 243 "RESERVED" 244 "RESERVED" 245 "RESERVED" 246 "RESERVED" 247 "RESERVED" 248 "RESERVED" 249 "RESERVED" 250 "RESERVED" 251 "RESERVED" 252 "RESERVED" 253 "RESERVED" 254 "RESERVED" 255 "Invalid" ;
VAL_ 297 L_ATCU_CTS_FrPsEVntCtrBdryLo_Y 0 "Default" 1 "0x01~0xC0:PHY=HEX*10 + 0" 192 "0x01~0xC0:PHY=HEX*10 + 0" 193 "RESERVED" 194 "RESERVED" 195 "RESERVED" 196 "RESERVED" 197 "RESERVED" 198 "RESERVED" 199 "RESERVED" 200 "RESERVED" 201 "RESERVED" 202 "RESERVED" 203 "RESERVED" 204 "RESERVED" 205 "RESERVED" 206 "RESERVED" 207 "RESERVED" 208 "RESERVED" 209 "RESERVED" 210 "RESERVED" 211 "RESERVED" 212 "RESERVED" 213 "RESERVED" 214 "RESERVED" 215 "RESERVED" 216 "RESERVED" 217 "RESERVED" 218 "RESERVED" 219 "RESERVED" 220 "RESERVED" 221 "RESERVED" 222 "RESERVED" 223 "RESERVED" 224 "RESERVED" 225 "RESERVED" 226 "RESERVED" 227 "RESERVED" 228 "RESERVED" 229 "RESERVED" 230 "RESERVED" 231 "RESERVED" 232 "RESERVED" 233 "RESERVED" 234 "RESERVED" 235 "RESERVED" 236 "RESERVED" 237 "RESERVED" 238 "RESERVED" 239 "RESERVED" 240 "RESERVED" 241 "RESERVED" 242 "RESERVED" 243 "RESERVED" 244 "RESERVED" 245 "RESERVED" 246 "RESERVED" 247 "RESERVED" 248 "RESERVED" 249 "RESERVED" 250 "RESERVED" 251 "RESERVED" 252 "RESERVED" 253 "RESERVED" 254 "RESERVED" 255 "Invalid" ;
VAL_ 297 L_ATCU_CTS_FrPsEVntSideBdryUp_Y 0 "Default" 1 "0x01~0xC0:PHY=HEX*10 + 0" 192 "0x01~0xC0:PHY=HEX*10 + 0" 193 "RESERVED" 194 "RESERVED" 195 "RESERVED" 196 "RESERVED" 197 "RESERVED" 198 "RESERVED" 199 "RESERVED" 200 "RESERVED" 201 "RESERVED" 202 "RESERVED" 203 "RESERVED" 204 "RESERVED" 205 "RESERVED" 206 "RESERVED" 207 "RESERVED" 208 "RESERVED" 209 "RESERVED" 210 "RESERVED" 211 "RESERVED" 212 "RESERVED" 213 "RESERVED" 214 "RESERVED" 215 "RESERVED" 216 "RESERVED" 217 "RESERVED" 218 "RESERVED" 219 "RESERVED" 220 "RESERVED" 221 "RESERVED" 222 "RESERVED" 223 "RESERVED" 224 "RESERVED" 225 "RESERVED" 226 "RESERVED" 227 "RESERVED" 228 "RESERVED" 229 "RESERVED" 230 "RESERVED" 231 "RESERVED" 232 "RESERVED" 233 "RESERVED" 234 "RESERVED" 235 "RESERVED" 236 "RESERVED" 237 "RESERVED" 238 "RESERVED" 239 "RESERVED" 240 "RESERVED" 241 "RESERVED" 242 "RESERVED" 243 "RESERVED" 244 "RESERVED" 245 "RESERVED" 246 "RESERVED" 247 "RESERVED" 248 "RESERVED" 249 "RESERVED" 250 "RESERVED" 251 "RESERVED" 252 "RESERVED" 253 "RESERVED" 254 "RESERVED" 255 "Invalid" ;
VAL_ 353 L_ATCU_HU_FrDrEVntModeSet 0 "Default" 1 "FOCUS Mode" 2 "SPREAD Mode" 3 "CYCLE Mode" 4 "Manual Mode" 5 "OFF" 6 "RESERVED" 7 "RESERVED" 8 "RESERVED" 9 "RESERVED" 10 "RESERVED" 11 "RESERVED" 12 "RESERVED" 13 "RESERVED" 14 "RESERVED" 15 "Invalid" ;
VAL_ 353 L_ATCU_HU_FrDrEVntCtrOpnCls 0 "Default" 1 "OPEN" 2 "CLOSE" 3 "Invalid" ;
VAL_ 353 L_ATCU_HU_FrPsEVntSideOpnCls 0 "Default" 1 "OPEN" 2 "CLOSE" 3 "Invalid" ;
VAL_ 353 L_ATCU_HU_FrPsEVntCtrOpnCls 0 "Default" 1 "OPEN" 2 "CLOSE" 3 "Invalid" ;
VAL_ 353 L_ATCU_HU_FrPsEVntModeSet 0 "Default" 1 "FOCUS Mode" 2 "SPREAD Mode" 3 "CYCLE Mode" 4 "Manual Mode" 5 "OFF" 6 "RESERVED" 7 "RESERVED" 8 "RESERVED" 9 "RESERVED" 10 "RESERVED" 11 "RESERVED" 12 "RESERVED" 13 "RESERVED" 14 "RESERVED" 15 "Invalid" ;
VAL_ 353 L_ATCU_HU_FrDrEVntSideOpnCls 0 "Default" 1 "OPEN" 2 "CLOSE" 3 "Invalid" ;
VAL_ 354 L_ATCU_CTS_FrtDrEVntModeSet 0 "Default" 1 "FOCUS Mode" 2 "SPREAD Mode" 3 "CYCLE Mode" 4 "Manual Mode" 5 "OFF" 6 "RESERVED" 7 "RESERVED" 8 "RESERVED" 9 "RESERVED" 10 "RESERVED" 11 "RESERVED" 12 "RESERVED" 13 "RESERVED" 14 "RESERVED" 15 "Invalid" ;
VAL_ 354 L_ATCU_CTS_FrDrEVntCtrOpnCls 0 "Default" 1 "OPEN" 2 "CLOSE" 3 "Invalid" ;
VAL_ 354 L_ATCU_CTS_FrPsEVntSideOpnCls 0 "Default" 1 "OPEN" 2 "CLOSE" 3 "Invalid" ;
VAL_ 354 L_ATCU_CTS_FrPsEVntCtrOpnCls 0 "Default" 1 "OPEN" 2 "CLOSE" 3 "Invalid" ;
VAL_ 354 L_ATCU_CTS_FrtPsEVntModeSet 0 "Default" 1 "FOCUS Mode" 2 "SPREAD Mode" 3 "CYCLE Mode" 4 "Manual Mode" 5 "OFF" 6 "RESERVED" 7 "RESERVED" 8 "RESERVED" 9 "RESERVED" 10 "RESERVED" 11 "RESERVED" 12 "RESERVED" 13 "RESERVED" 14 "RESERVED" 15 "Invalid" ;
VAL_ 354 L_ATCU_CTS_FrDrEVntSideOpnCls 0 "Default" 1 "OPEN" 2 "CLOSE" 3 "Invalid" ;
